[part 1 of 2: package /STLASWCs]
AUTOSAR XML (schema 4-3-0)
package /STLASWCs
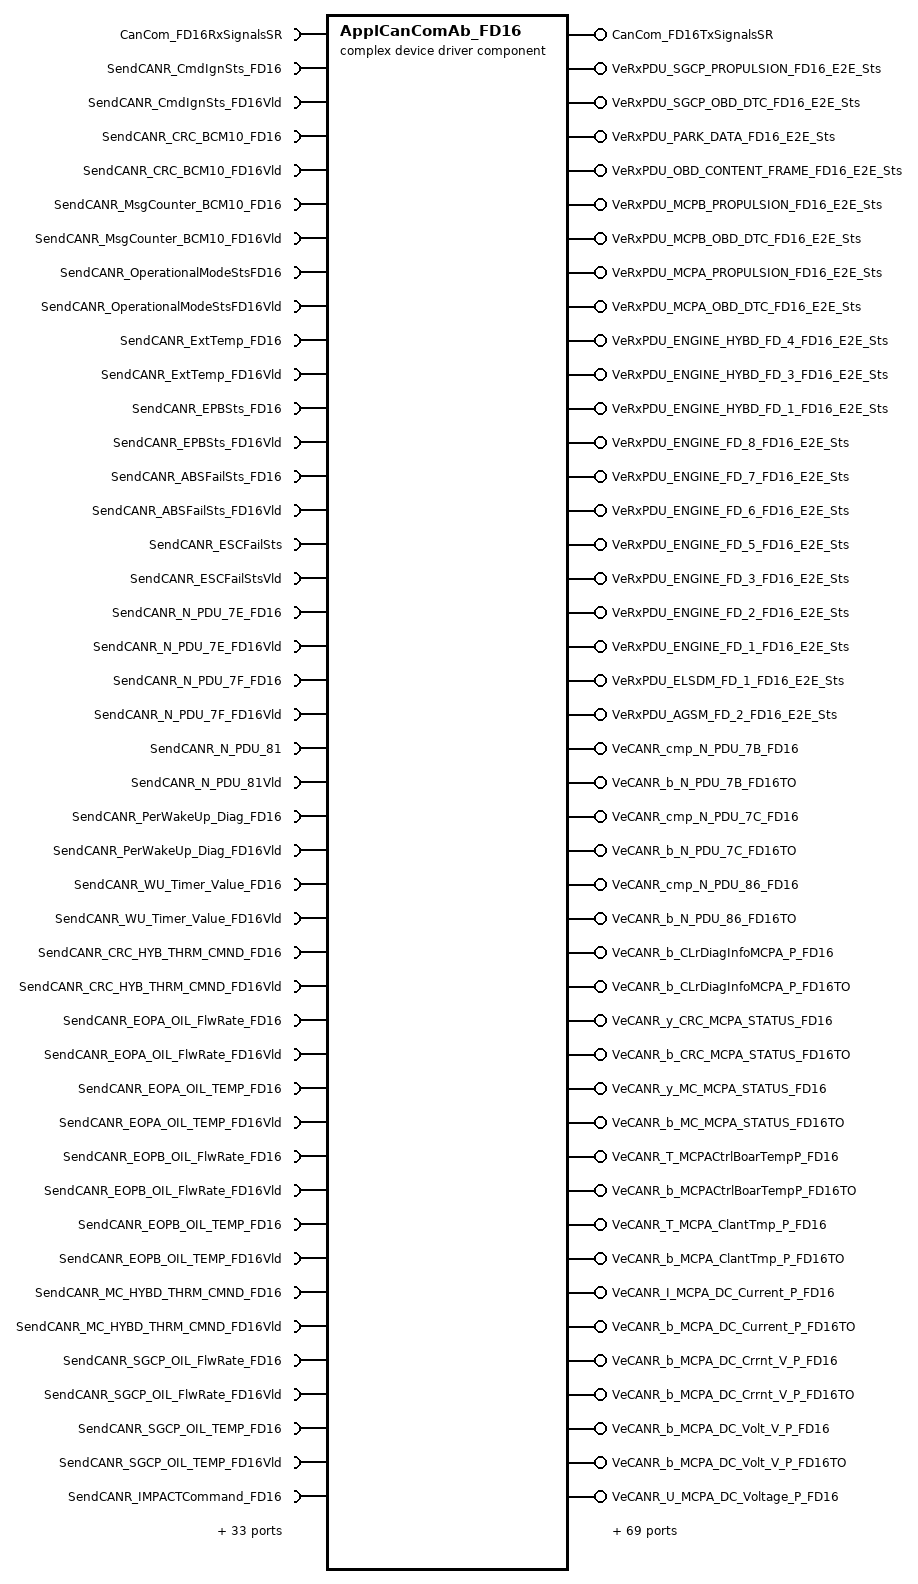
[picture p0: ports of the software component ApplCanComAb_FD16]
  complex device driver sw component type ApplCanComAb_FD16  # Application CAN Communication Abstraction Component - is responsible with receiving and sending CAN data from/to the lower BSW COM layers
    21 x provide port:
      CanCom_FD16TxSignalsSR: provided-interface=CanCom_FD16TxSignalsSR
        provided-com-specs:
          data-element=COMTX_CmdIgnSts_BCM_FD_10_FD16, init-value=constant-reference=COMTX_CmdIgnSts_BCM_FD_10_FD16_Init
          data-element=COMTX_CRC_BCM10_BCM_FD_10_FD16, init-value=constant-reference=COMTX_CRC_BCM10_BCM_FD_10_FD16_Init
          data-element=COMTX_MessageCounter_BCM10_BCM_FD_10_FD16, init-value=constant-reference=COMTX_MessageCounter_BCM10_BCM_FD_10_FD16_Init
          data-element=COMTX_OperationalModeSts_BCM_FD_2_FD16, init-value=constant-reference=COMTX_OperationalModeSts_BCM_FD_2_FD16_Init
          data-element=COMTX_ExternalTemperature_BCM_FD_9_FD16, init-value=constant-reference=COMTX_ExternalTemperature_BCM_FD_9_FD16_Init
          data-element=COMTX_EPBSts_BRAKE_FD_4_FD16, init-value=constant-reference=COMTX_EPBSts_BRAKE_FD_4_FD16_Init
          data-element=COMTX_ABSFailSts_BRAKE_FD_5_FD16, init-value=constant-reference=COMTX_ABSFailSts_BRAKE_FD_5_FD16_Init
          data-element=COMTX_ESCFailSts_BRAKE_FD_5_FD16, init-value=constant-reference=COMTX_ESCFailSts_BRAKE_FD_5_FD16_Init
          data-element=COMTX_N_PDU_7E_GLIWA_MCPA_RX_FD16, init-value=constant-reference=COMTX_N_PDU_7E_GLIWA_MCPA_RX_FD16_Init
          data-element=COMTX_N_PDU_7F_GLIWA_MCPB_RX_FD16, init-value=constant-reference=COMTX_N_PDU_7F_GLIWA_MCPB_RX_FD16_Init
          data-element=COMTX_N_PDU_81_GLIWA_SGCP_RX_FD16, init-value=constant-reference=COMTX_N_PDU_81_GLIWA_SGCP_RX_FD16_Init
          data-element=COMTX_PerWakeUp_Diag_HYBRID_SYSTEM_EPT1_FD16, init-value=constant-reference=COMTX_PerWakeUp_Diag_HYBRID_SYSTEM_EPT1_FD16_Init
          data-element=COMTX_WU_Timer_Value_HYBRID_SYSTEM_EPT1_FD16, init-value=constant-reference=COMTX_WU_Timer_Value_HYBRID_SYSTEM_EPT1_FD16_Init
          data-element=COMTX_CRC_HYBRID_THERMAL_COMMAND_HYBRID_THERMAL_COMMAND_FD16, init-value=constant-reference=COMTX_CRC_HYBRID_THERMAL_COMMAND_HYBRID_THERMAL_COMMAND_FD16_Init
          data-element=COMTX_EOPA_OIL_FlwRate_HYBRID_THERMAL_COMMAND_FD16, init-value=constant-reference=COMTX_EOPA_OIL_FlwRate_HYBRID_THERMAL_COMMAND_FD16_Init
          data-element=COMTX_EOPA_OIL_TEMP_HYBRID_THERMAL_COMMAND_FD16, init-value=constant-reference=COMTX_EOPA_OIL_TEMP_HYBRID_THERMAL_COMMAND_FD16_Init
          data-element=COMTX_EOPB_OIL_FlwRate_HYBRID_THERMAL_COMMAND_FD16, init-value=constant-reference=COMTX_EOPB_OIL_FlwRate_HYBRID_THERMAL_COMMAND_FD16_Init
          data-element=COMTX_EOPB_OIL_TEMP_HYBRID_THERMAL_COMMAND_FD16, init-value=constant-reference=COMTX_EOPB_OIL_TEMP_HYBRID_THERMAL_COMMAND_FD16_Init
          data-element=COMTX_MessageCounter_HYBRID_THERMAL_COMMAND_HYBRID_THERMAL_COMMAND_FD16, init-value=constant-reference=COMTX_MessageCounter_HYBRID_THERMAL_COMMAND_HYBRID_THERMAL_COMMAND_FD16_Init
          data-element=COMTX_SGCP_OIL_FlwRate_HYBRID_THERMAL_COMMAND_FD16, init-value=constant-reference=COMTX_SGCP_OIL_FlwRate_HYBRID_THERMAL_COMMAND_FD16_Init
          data-element=COMTX_SGCP_OIL_TEMP_HYBRID_THERMAL_COMMAND_FD16, init-value=constant-reference=COMTX_SGCP_OIL_TEMP_HYBRID_THERMAL_COMMAND_FD16_Init
          data-element=COMTX_IMPACTCommand_IMPACT_INFO_FD16, init-value=constant-reference=COMTX_IMPACTCommand_IMPACT_INFO_FD16_Init
          data-element=COMTX_IMPACTConfirm_IMPACT_INFO_FD16, init-value=constant-reference=COMTX_IMPACTConfirm_IMPACT_INFO_FD16_Init
          data-element=COMTX_TotalOdometer_IPC_FD_1_FD16, init-value=constant-reference=COMTX_TotalOdometer_IPC_FD_1_FD16_Init
          data-element=COMTX_Real_Time_Clock_REAL_TIME_CLOCK_FD16, init-value=constant-reference=COMTX_Real_Time_Clock_REAL_TIME_CLOCK_FD16_Init
          data-element=COMTX_Real_Time_Validity_REAL_TIME_CLOCK_FD16, init-value=constant-reference=COMTX_Real_Time_Validity_REAL_TIME_CLOCK_FD16_Init
          data-element=COMTX_GPS_Date_Day_TELEMATIC_FD_1_FD16, init-value=constant-reference=COMTX_GPS_Date_Day_TELEMATIC_FD_1_FD16_Init
          data-element=COMTX_GPS_Date_Month_TELEMATIC_FD_1_FD16, init-value=constant-reference=COMTX_GPS_Date_Month_TELEMATIC_FD_1_FD16_Init
          data-element=COMTX_GPS_Date_Year_TELEMATIC_FD_1_FD16, init-value=constant-reference=COMTX_GPS_Date_Year_TELEMATIC_FD_1_FD16_Init
          data-element=COMTX_GPS_UTC_Hour_TELEMATIC_FD_1_FD16, init-value=constant-reference=COMTX_GPS_UTC_Hour_TELEMATIC_FD_1_FD16_Init
          data-element=COMTX_GPS_UTC_Minute_TELEMATIC_FD_1_FD16, init-value=constant-reference=COMTX_GPS_UTC_Minute_TELEMATIC_FD_1_FD16_Init
          data-element=COMTX_GPS_UTC_Second_TELEMATIC_FD_1_FD16, init-value=constant-reference=COMTX_GPS_UTC_Second_TELEMATIC_FD_1_FD16_Init
          data-element=COMTX_T4_Sensor_Temp_VDCM_PWT3_FD16, init-value=constant-reference=COMTX_T4_Sensor_Temp_VDCM_PWT3_FD16_Init
          data-element=COMTX_T7_CoolantTempVldty_VDCM_PWT3_FD16, init-value=constant-reference=COMTX_T7_CoolantTempVldty_VDCM_PWT3_FD16_Init
          data-element=COMTX_T7_Sensor_Temp_VDCM_PWT3_FD16, init-value=constant-reference=COMTX_T7_Sensor_Temp_VDCM_PWT3_FD16_Init
          data-element=COMTX_RELSD_TgtTrq_VEHDYN_FD_1_FD16, init-value=constant-reference=COMTX_RELSD_TgtTrq_VEHDYN_FD_1_FD16_Init
          data-element=COMTX_VIN_DATA_VIN_FD16, init-value=constant-reference=COMTX_VIN_DATA_VIN_FD16_Init
          data-element=COMTX_VIN_MSG_VIN_FD16, init-value=constant-reference=COMTX_VIN_MSG_VIN_FD16_Init
      VeRxPDU_SGCP_PROPULSION_FD16_E2E_Sts: provided-com-specs=[{data-element=E2ECheckSts, init-value=0}, {data-element=OpRetVal, init-value=0}], provided-interface=VeRxPDU_SGCP_PROPULSION_FD16_E2E_Sts
      VeRxPDU_SGCP_OBD_DTC_FD16_E2E_Sts: provided-com-specs=[{data-element=E2ECheckSts, init-value=0}, {data-element=OpRetVal, init-value=0}], provided-interface=VeRxPDU_SGCP_OBD_DTC_FD16_E2E_Sts
      VeRxPDU_PARK_DATA_FD16_E2E_Sts: provided-com-specs=[{data-element=E2ECheckSts, init-value=0}, {data-element=OpRetVal, init-value=0}], provided-interface=VeRxPDU_PARK_DATA_FD16_E2E_Sts
      VeRxPDU_OBD_CONTENT_FRAME_FD16_E2E_Sts: provided-com-specs=[{data-element=E2ECheckSts, init-value=0}, {data-element=OpRetVal, init-value=0}], provided-interface=VeRxPDU_OBD_CONTENT_FRAME_FD16_E2E_Sts
      VeRxPDU_MCPB_PROPULSION_FD16_E2E_Sts: provided-com-specs=[{data-element=E2ECheckSts, init-value=0}, {data-element=OpRetVal, init-value=0}], provided-interface=VeRxPDU_MCPB_PROPULSION_FD16_E2E_Sts
      VeRxPDU_MCPB_OBD_DTC_FD16_E2E_Sts: provided-com-specs=[{data-element=E2ECheckSts, init-value=0}, {data-element=OpRetVal, init-value=0}], provided-interface=VeRxPDU_MCPB_OBD_DTC_FD16_E2E_Sts
      VeRxPDU_MCPA_PROPULSION_FD16_E2E_Sts: provided-com-specs=[{data-element=E2ECheckSts, init-value=0}, {data-element=OpRetVal, init-value=0}], provided-interface=VeRxPDU_MCPA_PROPULSION_FD16_E2E_Sts
      VeRxPDU_MCPA_OBD_DTC_FD16_E2E_Sts: provided-com-specs=[{data-element=E2ECheckSts, init-value=0}, {data-element=OpRetVal, init-value=0}], provided-interface=VeRxPDU_MCPA_OBD_DTC_FD16_E2E_Sts
      VeRxPDU_ENGINE_HYBD_FD_4_FD16_E2E_Sts: provided-com-specs=[{data-element=E2ECheckSts, init-value=0}, {data-element=OpRetVal, init-value=0}], provided-interface=VeRxPDU_ENGINE_HYBD_FD_4_FD16_E2E_Sts
      VeRxPDU_ENGINE_HYBD_FD_3_FD16_E2E_Sts: provided-com-specs=[{data-element=E2ECheckSts, init-value=0}, {data-element=OpRetVal, init-value=0}], provided-interface=VeRxPDU_ENGINE_HYBD_FD_3_FD16_E2E_Sts
      VeRxPDU_ENGINE_HYBD_FD_1_FD16_E2E_Sts: provided-com-specs=[{data-element=E2ECheckSts, init-value=0}, {data-element=OpRetVal, init-value=0}], provided-interface=VeRxPDU_ENGINE_HYBD_FD_1_FD16_E2E_Sts
      VeRxPDU_ENGINE_FD_8_FD16_E2E_Sts: provided-com-specs=[{data-element=E2ECheckSts, init-value=0}, {data-element=OpRetVal, init-value=0}], provided-interface=VeRxPDU_ENGINE_FD_8_FD16_E2E_Sts
      VeRxPDU_ENGINE_FD_7_FD16_E2E_Sts: provided-com-specs=[{data-element=E2ECheckSts, init-value=0}, {data-element=OpRetVal, init-value=0}], provided-interface=VeRxPDU_ENGINE_FD_7_FD16_E2E_Sts
      VeRxPDU_ENGINE_FD_6_FD16_E2E_Sts: provided-com-specs=[{data-element=E2ECheckSts, init-value=0}, {data-element=OpRetVal, init-value=0}], provided-interface=VeRxPDU_ENGINE_FD_6_FD16_E2E_Sts
      VeRxPDU_ENGINE_FD_5_FD16_E2E_Sts: provided-com-specs=[{data-element=E2ECheckSts, init-value=0}, {data-element=OpRetVal, init-value=0}], provided-interface=VeRxPDU_ENGINE_FD_5_FD16_E2E_Sts
      VeRxPDU_ENGINE_FD_3_FD16_E2E_Sts: provided-com-specs=[{data-element=E2ECheckSts, init-value=0}, {data-element=OpRetVal, init-value=0}], provided-interface=VeRxPDU_ENGINE_FD_3_FD16_E2E_Sts
      VeRxPDU_ENGINE_FD_2_FD16_E2E_Sts: provided-com-specs=[{data-element=E2ECheckSts, init-value=0}, {data-element=OpRetVal, init-value=0}], provided-interface=VeRxPDU_ENGINE_FD_2_FD16_E2E_Sts
      VeRxPDU_ENGINE_FD_1_FD16_E2E_Sts: provided-com-specs=[{data-element=E2ECheckSts, init-value=0}, {data-element=OpRetVal, init-value=0}], provided-interface=VeRxPDU_ENGINE_FD_1_FD16_E2E_Sts
      VeRxPDU_ELSDM_FD_1_FD16_E2E_Sts: provided-com-specs=[{data-element=E2ECheckSts, init-value=0}, {data-element=OpRetVal, init-value=0}], provided-interface=VeRxPDU_ELSDM_FD_1_FD16_E2E_Sts
      VeRxPDU_AGSM_FD_2_FD16_E2E_Sts: provided-com-specs=[{data-element=E2ECheckSts, init-value=0}, {data-element=OpRetVal, init-value=0}], provided-interface=VeRxPDU_AGSM_FD_2_FD16_E2E_Sts
    require port CanCom_FD16RxSignalsSR: required-interface=CanCom_FD16RxSignalsSR
      required-com-specs:
        data-element=COMRX_N_PDU_7B_GLIWA_MCPA_TX_FD16, handle-never-received=true, init-value=constant-reference=COMRX_N_PDU_7B_GLIWA_MCPA_TX_FD16_Init
        data-element=COMRX_N_PDU_7C_GLIWA_MCPB_TX_FD16, handle-never-received=true, init-value=constant-reference=COMRX_N_PDU_7C_GLIWA_MCPB_TX_FD16_Init
        data-element=COMRX_N_PDU_86_GLIWA_SGCP_TX_FD16, handle-never-received=true, init-value=constant-reference=COMRX_N_PDU_86_GLIWA_SGCP_TX_FD16_Init
        data-element=COMRX_CLrDiagInfo_MCPA_P_MCPA_STATUS_FD16, alive-timeout=0.2, handle-never-received=true, init-value=constant-reference=COMRX_CLrDiagInfo_MCPA_P_MCPA_STATUS_FD16_Init
        data-element=COMRX_CRC_MCPA_STATUS_MCPA_STATUS_FD16, alive-timeout=0.2, handle-never-received=true, init-value=constant-reference=COMRX_CRC_MCPA_STATUS_MCPA_STATUS_FD16_Init
        data-element=COMRX_MC_MCPA_STATUS_MCPA_STATUS_FD16, alive-timeout=0.2, handle-never-received=true, init-value=constant-reference=COMRX_MC_MCPA_STATUS_MCPA_STATUS_FD16_Init
        data-element=COMRX_MCPA_Control_Board_Temperature_P_MCPA_STATUS_FD16, alive-timeout=0.2, handle-never-received=true, init-value=constant-reference=COMRX_MCPA_Control_Board_Temperature_P_MCPA_STATUS_FD16_Init
        data-element=COMRX_MCPA_CoolantTemp_P_MCPA_STATUS_FD16, alive-timeout=0.2, handle-never-received=true, init-value=constant-reference=COMRX_MCPA_CoolantTemp_P_MCPA_STATUS_FD16_Init
        data-element=COMRX_MCPA_DC_Current_P_MCPA_STATUS_FD16, alive-timeout=0.2, handle-never-received=true, init-value=constant-reference=COMRX_MCPA_DC_Current_P_MCPA_STATUS_FD16_Init
        data-element=COMRX_MCPA_DC_Current_V_P_MCPA_STATUS_FD16, alive-timeout=0.2, handle-never-received=true, init-value=constant-reference=COMRX_MCPA_DC_Current_V_P_MCPA_STATUS_FD16_Init
        data-element=COMRX_MCPA_DC_Volt_V_P_MCPA_STATUS_FD16, alive-timeout=0.2, handle-never-received=true, init-value=constant-reference=COMRX_MCPA_DC_Volt_V_P_MCPA_STATUS_FD16_Init
        data-element=COMRX_MCPA_DC_Voltage_P_MCPA_STATUS_FD16, alive-timeout=0.2, handle-never-received=true, init-value=constant-reference=COMRX_MCPA_DC_Voltage_P_MCPA_STATUS_FD16_Init
        data-element=COMRX_MCPA_DerateReason_P_MCPA_STATUS_FD16, alive-timeout=0.2, handle-never-received=true, init-value=constant-reference=COMRX_MCPA_DerateReason_P_MCPA_STATUS_FD16_Init
        data-element=COMRX_MCPA_Inverter_Temp_P_MCPA_STATUS_FD16, alive-timeout=0.2, handle-never-received=true, init-value=constant-reference=COMRX_MCPA_Inverter_Temp_P_MCPA_STATUS_FD16_Init
        data-element=COMRX_MCPA_PIM_DC_Side_Busbar_Temp_P_MCPA_STATUS_FD16, alive-timeout=0.2, handle-never-received=true, init-value=constant-reference=COMRX_MCPA_PIM_DC_Side_Busbar_Temp_P_MCPA_STATUS_FD16_Init
        data-element=COMRX_MCPA_Rotor_Temperature_P_MCPA_STATUS_FD16, alive-timeout=0.2, handle-never-received=true, init-value=constant-reference=COMRX_MCPA_Rotor_Temperature_P_MCPA_STATUS_FD16_Init
        data-element=COMRX_MCPA_Service_Lamp_Request_P_MCPA_STATUS_FD16, alive-timeout=0.2, handle-never-received=true, init-value=constant-reference=COMRX_MCPA_Service_Lamp_Request_P_MCPA_STATUS_FD16_Init
        data-element=COMRX_CLrDiagInfo_MCPB_P_MCPB_STATUS_FD16, alive-timeout=0.2, handle-never-received=true, init-value=constant-reference=COMRX_CLrDiagInfo_MCPB_P_MCPB_STATUS_FD16_Init
        data-element=COMRX_CRC_MCPB_STATUS_MCPB_STATUS_FD16, alive-timeout=0.2, handle-never-received=true, init-value=constant-reference=COMRX_CRC_MCPB_STATUS_MCPB_STATUS_FD16_Init
        data-element=COMRX_MC_MCPB_STATUS_MCPB_STATUS_FD16, alive-timeout=0.2, handle-never-received=true, init-value=constant-reference=COMRX_MC_MCPB_STATUS_MCPB_STATUS_FD16_Init
        data-element=COMRX_MCPB_Control_Board_Temperature_P_MCPB_STATUS_FD16, alive-timeout=0.2, handle-never-received=true, init-value=constant-reference=COMRX_MCPB_Control_Board_Temperature_P_MCPB_STATUS_FD16_Init
        data-element=COMRX_MCPB_CoolantTemp_P_MCPB_STATUS_FD16, alive-timeout=0.2, handle-never-received=true, init-value=constant-reference=COMRX_MCPB_CoolantTemp_P_MCPB_STATUS_FD16_Init
        data-element=COMRX_MCPB_DC_Current_P_MCPB_STATUS_FD16, alive-timeout=0.2, handle-never-received=true, init-value=constant-reference=COMRX_MCPB_DC_Current_P_MCPB_STATUS_FD16_Init
        data-element=COMRX_MCPB_DC_Current_V_P_MCPB_STATUS_FD16, alive-timeout=0.2, handle-never-received=true, init-value=constant-reference=COMRX_MCPB_DC_Current_V_P_MCPB_STATUS_FD16_Init
        data-element=COMRX_MCPB_DC_Volt_V_P_MCPB_STATUS_FD16, alive-timeout=0.2, handle-never-received=true, init-value=constant-reference=COMRX_MCPB_DC_Volt_V_P_MCPB_STATUS_FD16_Init
        data-element=COMRX_MCPB_DC_Voltage_P_MCPB_STATUS_FD16, alive-timeout=0.2, handle-never-received=true, init-value=constant-reference=COMRX_MCPB_DC_Voltage_P_MCPB_STATUS_FD16_Init
        data-element=COMRX_MCPB_DerateReason_P_MCPB_STATUS_FD16, alive-timeout=0.2, handle-never-received=true, init-value=constant-reference=COMRX_MCPB_DerateReason_P_MCPB_STATUS_FD16_Init
        data-element=COMRX_MCPB_Inverter_Temp_P_MCPB_STATUS_FD16, alive-timeout=0.2, handle-never-received=true, init-value=constant-reference=COMRX_MCPB_Inverter_Temp_P_MCPB_STATUS_FD16_Init
        data-element=COMRX_MCPB_PIM_DC_Side_Busbar_Temp_P_MCPB_STATUS_FD16, alive-timeout=0.2, handle-never-received=true, init-value=constant-reference=COMRX_MCPB_PIM_DC_Side_Busbar_Temp_P_MCPB_STATUS_FD16_Init
        data-element=COMRX_MCPB_Rotor_Temperature_P_MCPB_STATUS_FD16, alive-timeout=0.2, handle-never-received=true, init-value=constant-reference=COMRX_MCPB_Rotor_Temperature_P_MCPB_STATUS_FD16_Init
        data-element=COMRX_MCPB_Service_Lamp_Request_P_MCPB_STATUS_FD16, alive-timeout=0.2, handle-never-received=true, init-value=constant-reference=COMRX_MCPB_Service_Lamp_Request_P_MCPB_STATUS_FD16_Init
        data-element=COMRX_CLrDiagInfo_SGCP_P_SGCP_STATUS_FD16, alive-timeout=0.2, handle-never-received=true, init-value=constant-reference=COMRX_CLrDiagInfo_SGCP_P_SGCP_STATUS_FD16_Init
        data-element=COMRX_CRC_SGCP_STATUS_SGCP_STATUS_FD16, alive-timeout=0.2, handle-never-received=true, init-value=constant-reference=COMRX_CRC_SGCP_STATUS_SGCP_STATUS_FD16_Init
        data-element=COMRX_MC_SGCP_STATUS_SGCP_STATUS_FD16, alive-timeout=0.2, handle-never-received=true, init-value=constant-reference=COMRX_MC_SGCP_STATUS_SGCP_STATUS_FD16_Init
        data-element=COMRX_SGCP_Control_Board_Temperature_P_SGCP_STATUS_FD16, alive-timeout=0.2, handle-never-received=true, init-value=constant-reference=COMRX_SGCP_Control_Board_Temperature_P_SGCP_STATUS_FD16_Init
        data-element=COMRX_SGCP_CoolantTemp_P_SGCP_STATUS_FD16, alive-timeout=0.2, handle-never-received=true, init-value=constant-reference=COMRX_SGCP_CoolantTemp_P_SGCP_STATUS_FD16_Init
        data-element=COMRX_SGCP_DC_Current_P_SGCP_STATUS_FD16, alive-timeout=0.2, handle-never-received=true, init-value=constant-reference=COMRX_SGCP_DC_Current_P_SGCP_STATUS_FD16_Init
        data-element=COMRX_SGCP_DC_Current_V_P_SGCP_STATUS_FD16, alive-timeout=0.2, handle-never-received=true, init-value=constant-reference=COMRX_SGCP_DC_Current_V_P_SGCP_STATUS_FD16_Init
        data-element=COMRX_SGCP_DC_Volt_V_P_SGCP_STATUS_FD16, alive-timeout=0.2, handle-never-received=true, init-value=constant-reference=COMRX_SGCP_DC_Volt_V_P_SGCP_STATUS_FD16_Init
        data-element=COMRX_SGCP_DC_Voltage_P_SGCP_STATUS_FD16, alive-timeout=0.2, handle-never-received=true, init-value=constant-reference=COMRX_SGCP_DC_Voltage_P_SGCP_STATUS_FD16_Init
        data-element=COMRX_SGCP_DerateReason_P_SGCP_STATUS_FD16, alive-timeout=0.2, handle-never-received=true, init-value=constant-reference=COMRX_SGCP_DerateReason_P_SGCP_STATUS_FD16_Init
        data-element=COMRX_SGCP_Inverter_Temp_P_SGCP_STATUS_FD16, alive-timeout=0.2, handle-never-received=true, init-value=constant-reference=COMRX_SGCP_Inverter_Temp_P_SGCP_STATUS_FD16_Init
        data-element=COMRX_SGCP_PIM_AC_Side_Busbar_Temp_P_SGCP_STATUS_FD16, alive-timeout=0.2, handle-never-received=true, init-value=constant-reference=COMRX_SGCP_PIM_AC_Side_Busbar_Temp_P_SGCP_STATUS_FD16_Init
        data-element=COMRX_SGCP_PIM_DC_Side_Busbar_Temp_P_SGCP_STATUS_FD16, alive-timeout=0.2, handle-never-received=true, init-value=constant-reference=COMRX_SGCP_PIM_DC_Side_Busbar_Temp_P_SGCP_STATUS_FD16_Init
        data-element=COMRX_SGCP_Rotor_Temperature_P_SGCP_STATUS_FD16, alive-timeout=0.2, handle-never-received=true, init-value=constant-reference=COMRX_SGCP_Rotor_Temperature_P_SGCP_STATUS_FD16_Init
        data-element=COMRX_SGCP_Service_Lamp_Request_P_SGCP_STATUS_FD16, alive-timeout=0.2, handle-never-received=true, init-value=constant-reference=COMRX_SGCP_Service_Lamp_Request_P_SGCP_STATUS_FD16_Init
    92 x provide port:
      VeCANR_cmp_N_PDU_7B_FD16: nonqueued-sender-com-spec{data-element=VeCANR_cmp_N_PDU_7B_FD16, init-value=VeCANR_cmp_N_PDU_7B_FD16Value:0}, provided-interface=VeCANR_cmp_N_PDU_7B_FD16
      VeCANR_b_N_PDU_7B_FD16TO: nonqueued-sender-com-spec{data-element=VeCANR_b_N_PDU_7B_FD16TO, init-value=VeCANR_b_N_PDU_7B_FD16TOValue:0}, provided-interface=VeCANR_b_N_PDU_7B_FD16TO
      VeCANR_cmp_N_PDU_7C_FD16: nonqueued-sender-com-spec{data-element=VeCANR_cmp_N_PDU_7C_FD16, init-value=VeCANR_cmp_N_PDU_7C_FD16Value:0}, provided-interface=VeCANR_cmp_N_PDU_7C_FD16
      VeCANR_b_N_PDU_7C_FD16TO: nonqueued-sender-com-spec{data-element=VeCANR_b_N_PDU_7C_FD16TO, init-value=VeCANR_b_N_PDU_7C_FD16TOValue:0}, provided-interface=VeCANR_b_N_PDU_7C_FD16TO
      VeCANR_cmp_N_PDU_86_FD16: nonqueued-sender-com-spec{data-element=VeCANR_cmp_N_PDU_86_FD16, init-value=VeCANR_cmp_N_PDU_86_FD16Value:0}, provided-interface=VeCANR_cmp_N_PDU_86_FD16
      VeCANR_b_N_PDU_86_FD16TO: nonqueued-sender-com-spec{data-element=VeCANR_b_N_PDU_86_FD16TO, init-value=VeCANR_b_N_PDU_86_FD16TOValue:0}, provided-interface=VeCANR_b_N_PDU_86_FD16TO
      VeCANR_b_CLrDiagInfoMCPA_P_FD16: nonqueued-sender-com-spec{data-element=VeCANR_b_CLrDiagInfoMCPA_P_FD16, init-value=VeCANR_b_CLrDiagInfoMCPA_P_FD16Value:0}, provided-interface=VeCANR_b_CLrDiagInfoMCPA_P_FD16
      VeCANR_b_CLrDiagInfoMCPA_P_FD16TO: nonqueued-sender-com-spec{data-element=VeCANR_b_CLrDiagInfoMCPA_P_FD16TO, init-value=VeCANR_b_CLrDiagInfoMCPA_P_FD16TOValue:0}, provided-interface=VeCANR_b_CLrDiagInfoMCPA_P_FD16TO
      VeCANR_y_CRC_MCPA_STATUS_FD16: nonqueued-sender-com-spec{data-element=VeCANR_y_CRC_MCPA_STATUS_FD16, init-value=VeCANR_y_CRC_MCPA_STATUS_FD16Value:0}, provided-interface=VeCANR_y_CRC_MCPA_STATUS_FD16
      VeCANR_b_CRC_MCPA_STATUS_FD16TO: nonqueued-sender-com-spec{data-element=VeCANR_b_CRC_MCPA_STATUS_FD16TO, init-value=VeCANR_b_CRC_MCPA_STATUS_FD16TOValue:0}, provided-interface=VeCANR_b_CRC_MCPA_STATUS_FD16TO
      VeCANR_y_MC_MCPA_STATUS_FD16: nonqueued-sender-com-spec{data-element=VeCANR_y_MC_MCPA_STATUS_FD16, init-value=VeCANR_y_MC_MCPA_STATUS_FD16Value:0}, provided-interface=VeCANR_y_MC_MCPA_STATUS_FD16
      VeCANR_b_MC_MCPA_STATUS_FD16TO: nonqueued-sender-com-spec{data-element=VeCANR_b_MC_MCPA_STATUS_FD16TO, init-value=VeCANR_b_MC_MCPA_STATUS_FD16TOValue:0}, provided-interface=VeCANR_b_MC_MCPA_STATUS_FD16TO
      VeCANR_T_MCPACtrlBoarTempP_FD16: nonqueued-sender-com-spec{data-element=VeCANR_T_MCPACtrlBoarTempP_FD16, init-value=VeCANR_T_MCPACtrlBoarTempP_FD16Value:215}, provided-interface=VeCANR_T_MCPACtrlBoarTempP_FD16
      VeCANR_b_MCPACtrlBoarTempP_FD16TO: nonqueued-sender-com-spec{data-element=VeCANR_b_MCPACtrlBoarTempP_FD16TO, init-value=VeCANR_b_MCPACtrlBoarTempP_FD16TOValue:0}, provided-interface=VeCANR_b_MCPACtrlBoarTempP_FD16TO
      VeCANR_T_MCPA_ClantTmp_P_FD16: nonqueued-sender-com-spec{data-element=VeCANR_T_MCPA_ClantTmp_P_FD16, init-value=VeCANR_T_MCPA_ClantTmp_P_FD16Value:-40}, provided-interface=VeCANR_T_MCPA_ClantTmp_P_FD16
      VeCANR_b_MCPA_ClantTmp_P_FD16TO: nonqueued-sender-com-spec{data-element=VeCANR_b_MCPA_ClantTmp_P_FD16TO, init-value=VeCANR_b_MCPA_ClantTmp_P_FD16TOValue:0}, provided-interface=VeCANR_b_MCPA_ClantTmp_P_FD16TO
      VeCANR_I_MCPA_DC_Current_P_FD16: nonqueued-sender-com-spec{data-element=VeCANR_I_MCPA_DC_Current_P_FD16, init-value=VeCANR_I_MCPA_DC_Current_P_FD16Value:0}, provided-interface=VeCANR_I_MCPA_DC_Current_P_FD16
      VeCANR_b_MCPA_DC_Current_P_FD16TO: nonqueued-sender-com-spec{data-element=VeCANR_b_MCPA_DC_Current_P_FD16TO, init-value=VeCANR_b_MCPA_DC_Current_P_FD16TOValue:0}, provided-interface=VeCANR_b_MCPA_DC_Current_P_FD16TO
      VeCANR_b_MCPA_DC_Crrnt_V_P_FD16: nonqueued-sender-com-spec{data-element=VeCANR_b_MCPA_DC_Crrnt_V_P_FD16, init-value=VeCANR_b_MCPA_DC_Crrnt_V_P_FD16Value:0}, provided-interface=VeCANR_b_MCPA_DC_Crrnt_V_P_FD16
      VeCANR_b_MCPA_DC_Crrnt_V_P_FD16TO: nonqueued-sender-com-spec{data-element=VeCANR_b_MCPA_DC_Crrnt_V_P_FD16TO, init-value=VeCANR_b_MCPA_DC_Crrnt_V_P_FD16TOValue:0}, provided-interface=VeCANR_b_MCPA_DC_Crrnt_V_P_FD16TO
      VeCANR_b_MCPA_DC_Volt_V_P_FD16: nonqueued-sender-com-spec{data-element=VeCANR_b_MCPA_DC_Volt_V_P_FD16, init-value=VeCANR_b_MCPA_DC_Volt_V_P_FD16Value:0}, provided-interface=VeCANR_b_MCPA_DC_Volt_V_P_FD16
      VeCANR_b_MCPA_DC_Volt_V_P_FD16TO: nonqueued-sender-com-spec{data-element=VeCANR_b_MCPA_DC_Volt_V_P_FD16TO, init-value=VeCANR_b_MCPA_DC_Volt_V_P_FD16TOValue:0}, provided-interface=VeCANR_b_MCPA_DC_Volt_V_P_FD16TO
      VeCANR_U_MCPA_DC_Voltage_P_FD16: nonqueued-sender-com-spec{data-element=VeCANR_U_MCPA_DC_Voltage_P_FD16, init-value=VeCANR_U_MCPA_DC_Voltage_P_FD16Value:0}, provided-interface=VeCANR_U_MCPA_DC_Voltage_P_FD16
      VeCANR_b_MCPA_DC_Voltage_P_FD16TO: nonqueued-sender-com-spec{data-element=VeCANR_b_MCPA_DC_Voltage_P_FD16TO, init-value=VeCANR_b_MCPA_DC_Voltage_P_FD16TOValue:0}, provided-interface=VeCANR_b_MCPA_DC_Voltage_P_FD16TO
      VeCANR_e_MCPA_DerateResn_P_FD16: nonqueued-sender-com-spec{data-element=VeCANR_e_MCPA_DerateResn_P_FD16, init-value=VeCANR_e_MCPA_DerateResn_P_FD16Value:0}, provided-interface=VeCANR_e_MCPA_DerateResn_P_FD16
      VeCANR_b_MCPA_DerateResn_P_FD16TO: nonqueued-sender-com-spec{data-element=VeCANR_b_MCPA_DerateResn_P_FD16TO, init-value=VeCANR_b_MCPA_DerateResn_P_FD16TOValue:0}, provided-interface=VeCANR_b_MCPA_DerateResn_P_FD16TO
      VeCANR_T_MCPA_InvertTemp_P_FD16: nonqueued-sender-com-spec{data-element=VeCANR_T_MCPA_InvertTemp_P_FD16, init-value=VeCANR_T_MCPA_InvertTemp_P_FD16Value:0}, provided-interface=VeCANR_T_MCPA_InvertTemp_P_FD16
      VeCANR_b_MCPA_InvertTemp_P_FD16TO: nonqueued-sender-com-spec{data-element=VeCANR_b_MCPA_InvertTemp_P_FD16TO, init-value=VeCANR_b_MCPA_InvertTemp_P_FD16TOValue:0}, provided-interface=VeCANR_b_MCPA_InvertTemp_P_FD16TO
      VeCANR_T_MCPAPIMDCSdBusTmpPFD16: nonqueued-sender-com-spec{data-element=VeCANR_T_MCPAPIMDCSdBusTmpPFD16, init-value=VeCANR_T_MCPAPIMDCSdBusTmpPFD16Value:-40}, provided-interface=VeCANR_T_MCPAPIMDCSdBusTmpPFD16
      VeCANR_b_MCPAPIMDCSdBusTmpPFD16TO: nonqueued-sender-com-spec{data-element=VeCANR_b_MCPAPIMDCSdBusTmpPFD16TO, init-value=VeCANR_b_MCPAPIMDCSdBusTmpPFD16TOValue:0}, provided-interface=VeCANR_b_MCPAPIMDCSdBusTmpPFD16TO
      VeCANR_T_MCPARotorTemp_P_FD16: nonqueued-sender-com-spec{data-element=VeCANR_T_MCPARotorTemp_P_FD16, init-value=VeCANR_T_MCPARotorTemp_P_FD16Value:215}, provided-interface=VeCANR_T_MCPARotorTemp_P_FD16
      VeCANR_b_MCPARotorTemp_P_FD16TO: nonqueued-sender-com-spec{data-element=VeCANR_b_MCPARotorTemp_P_FD16TO, init-value=VeCANR_b_MCPARotorTemp_P_FD16TOValue:0}, provided-interface=VeCANR_b_MCPARotorTemp_P_FD16TO
      VeCANR_b_MCPAServLampReq_P_FD16: nonqueued-sender-com-spec{data-element=VeCANR_b_MCPAServLampReq_P_FD16, init-value=VeCANR_b_MCPAServLampReq_P_FD16Value:0}, provided-interface=VeCANR_b_MCPAServLampReq_P_FD16
      VeCANR_b_MCPAServLampReq_P_FD16TO: nonqueued-sender-com-spec{data-element=VeCANR_b_MCPAServLampReq_P_FD16TO, init-value=VeCANR_b_MCPAServLampReq_P_FD16TOValue:0}, provided-interface=VeCANR_b_MCPAServLampReq_P_FD16TO
      VeCANR_b_CLrDiagInfoMCPB_P_FD16: nonqueued-sender-com-spec{data-element=VeCANR_b_CLrDiagInfoMCPB_P_FD16, init-value=VeCANR_b_CLrDiagInfoMCPB_P_FD16Value:0}, provided-interface=VeCANR_b_CLrDiagInfoMCPB_P_FD16
      VeCANR_b_CLrDiagInfoMCPB_P_FD16TO: nonqueued-sender-com-spec{data-element=VeCANR_b_CLrDiagInfoMCPB_P_FD16TO, init-value=VeCANR_b_CLrDiagInfoMCPB_P_FD16TOValue:0}, provided-interface=VeCANR_b_CLrDiagInfoMCPB_P_FD16TO
      VeCANR_y_CRC_MCPB_STATUS_FD16: nonqueued-sender-com-spec{data-element=VeCANR_y_CRC_MCPB_STATUS_FD16, init-value=VeCANR_y_CRC_MCPB_STATUS_FD16Value:0}, provided-interface=VeCANR_y_CRC_MCPB_STATUS_FD16
      VeCANR_b_CRC_MCPB_STATUS_FD16TO: nonqueued-sender-com-spec{data-element=VeCANR_b_CRC_MCPB_STATUS_FD16TO, init-value=VeCANR_b_CRC_MCPB_STATUS_FD16TOValue:0}, provided-interface=VeCANR_b_CRC_MCPB_STATUS_FD16TO
      VeCANR_y_MC_MCPB_STATUS_FD16: nonqueued-sender-com-spec{data-element=VeCANR_y_MC_MCPB_STATUS_FD16, init-value=VeCANR_y_MC_MCPB_STATUS_FD16Value:0}, provided-interface=VeCANR_y_MC_MCPB_STATUS_FD16
      VeCANR_b_MC_MCPB_STATUS_FD16TO: nonqueued-sender-com-spec{data-element=VeCANR_b_MC_MCPB_STATUS_FD16TO, init-value=VeCANR_b_MC_MCPB_STATUS_FD16TOValue:0}, provided-interface=VeCANR_b_MC_MCPB_STATUS_FD16TO
      VeCANR_y_MCPBCtrlBoarTempP_FD16: nonqueued-sender-com-spec{data-element=VeCANR_y_MCPBCtrlBoarTempP_FD16, init-value=VeCANR_y_MCPBCtrlBoarTempP_FD16Value:-40}, provided-interface=VeCANR_y_MCPBCtrlBoarTempP_FD16
      VeCANR_b_MCPBCtrlBoarTempP_FD16TO: nonqueued-sender-com-spec{data-element=VeCANR_b_MCPBCtrlBoarTempP_FD16TO, init-value=VeCANR_b_MCPBCtrlBoarTempP_FD16TOValue:0}, provided-interface=VeCANR_b_MCPBCtrlBoarTempP_FD16TO
      VeCANR_T_MCPB_CoolantTmp_P_FD16: nonqueued-sender-com-spec{data-element=VeCANR_T_MCPB_CoolantTmp_P_FD16, init-value=VeCANR_T_MCPB_CoolantTmp_P_FD16Value:-40}, provided-interface=VeCANR_T_MCPB_CoolantTmp_P_FD16
      VeCANR_b_MCPB_CoolantTmp_P_FD16TO: nonqueued-sender-com-spec{data-element=VeCANR_b_MCPB_CoolantTmp_P_FD16TO, init-value=VeCANR_b_MCPB_CoolantTmp_P_FD16TOValue:0}, provided-interface=VeCANR_b_MCPB_CoolantTmp_P_FD16TO
      VeCANR_I_MCPB_DC_Current_P_FD16: nonqueued-sender-com-spec{data-element=VeCANR_I_MCPB_DC_Current_P_FD16, init-value=VeCANR_I_MCPB_DC_Current_P_FD16Value:0}, provided-interface=VeCANR_I_MCPB_DC_Current_P_FD16
      VeCANR_b_MCPB_DC_Current_P_FD16TO: nonqueued-sender-com-spec{data-element=VeCANR_b_MCPB_DC_Current_P_FD16TO, init-value=VeCANR_b_MCPB_DC_Current_P_FD16TOValue:0}, provided-interface=VeCANR_b_MCPB_DC_Current_P_FD16TO
      VeCANR_b_MCPB_DC_Crrnt_V_P_FD16: nonqueued-sender-com-spec{data-element=VeCANR_b_MCPB_DC_Crrnt_V_P_FD16, init-value=VeCANR_b_MCPB_DC_Crrnt_V_P_FD16Value:0}, provided-interface=VeCANR_b_MCPB_DC_Crrnt_V_P_FD16
      VeCANR_b_MCPB_DC_Crrnt_V_P_FD16TO: nonqueued-sender-com-spec{data-element=VeCANR_b_MCPB_DC_Crrnt_V_P_FD16TO, init-value=VeCANR_b_MCPB_DC_Crrnt_V_P_FD16TOValue:0}, provided-interface=VeCANR_b_MCPB_DC_Crrnt_V_P_FD16TO
      VeCANR_b_MCPB_DC_Volt_V_P_FD16: nonqueued-sender-com-spec{data-element=VeCANR_b_MCPB_DC_Volt_V_P_FD16, init-value=VeCANR_b_MCPB_DC_Volt_V_P_FD16Value:0}, provided-interface=VeCANR_b_MCPB_DC_Volt_V_P_FD16
      VeCANR_b_MCPB_DC_Volt_V_P_FD16TO: nonqueued-sender-com-spec{data-element=VeCANR_b_MCPB_DC_Volt_V_P_FD16TO, init-value=VeCANR_b_MCPB_DC_Volt_V_P_FD16TOValue:0}, provided-interface=VeCANR_b_MCPB_DC_Volt_V_P_FD16TO
      VeCANR_U_MCPB_DC_Voltage_P_FD16: nonqueued-sender-com-spec{data-element=VeCANR_U_MCPB_DC_Voltage_P_FD16, init-value=VeCANR_U_MCPB_DC_Voltage_P_FD16Value:0}, provided-interface=VeCANR_U_MCPB_DC_Voltage_P_FD16
      VeCANR_b_MCPB_DC_Voltage_P_FD16TO: nonqueued-sender-com-spec{data-element=VeCANR_b_MCPB_DC_Voltage_P_FD16TO, init-value=VeCANR_b_MCPB_DC_Voltage_P_FD16TOValue:0}, provided-interface=VeCANR_b_MCPB_DC_Voltage_P_FD16TO
      VeCANR_e_MCPB_DerateResn_P_FD16: nonqueued-sender-com-spec{data-element=VeCANR_e_MCPB_DerateResn_P_FD16, init-value=VeCANR_e_MCPB_DerateResn_P_FD16Value:0}, provided-interface=VeCANR_e_MCPB_DerateResn_P_FD16
      VeCANR_b_MCPB_DerateResn_P_FD16TO: nonqueued-sender-com-spec{data-element=VeCANR_b_MCPB_DerateResn_P_FD16TO, init-value=VeCANR_b_MCPB_DerateResn_P_FD16TOValue:0}, provided-interface=VeCANR_b_MCPB_DerateResn_P_FD16TO
      VeCANR_T_MCPB_InvertTemp_P_FD16: nonqueued-sender-com-spec{data-element=VeCANR_T_MCPB_InvertTemp_P_FD16, init-value=VeCANR_T_MCPB_InvertTemp_P_FD16Value:0}, provided-interface=VeCANR_T_MCPB_InvertTemp_P_FD16
      VeCANR_b_MCPB_InvertTemp_P_FD16TO: nonqueued-sender-com-spec{data-element=VeCANR_b_MCPB_InvertTemp_P_FD16TO, init-value=VeCANR_b_MCPB_InvertTemp_P_FD16TOValue:0}, provided-interface=VeCANR_b_MCPB_InvertTemp_P_FD16TO
      VeCANR_T_MCPBPIMDCSdBusTmpPFD16: nonqueued-sender-com-spec{data-element=VeCANR_T_MCPBPIMDCSdBusTmpPFD16, init-value=VeCANR_T_MCPBPIMDCSdBusTmpPFD16Value:-40}, provided-interface=VeCANR_T_MCPBPIMDCSdBusTmpPFD16
      VeCANR_b_MCPBPIMDCSdBusTmpPFD16TO: nonqueued-sender-com-spec{data-element=VeCANR_b_MCPBPIMDCSdBusTmpPFD16TO, init-value=VeCANR_b_MCPBPIMDCSdBusTmpPFD16TOValue:0}, provided-interface=VeCANR_b_MCPBPIMDCSdBusTmpPFD16TO
      VeCANR_T_MCPBRotorTemp_P_FD16: nonqueued-sender-com-spec{data-element=VeCANR_T_MCPBRotorTemp_P_FD16, init-value=VeCANR_T_MCPBRotorTemp_P_FD16Value:215}, provided-interface=VeCANR_T_MCPBRotorTemp_P_FD16
      VeCANR_b_MCPBRotorTemp_P_FD16TO: nonqueued-sender-com-spec{data-element=VeCANR_b_MCPBRotorTemp_P_FD16TO, init-value=VeCANR_b_MCPBRotorTemp_P_FD16TOValue:0}, provided-interface=VeCANR_b_MCPBRotorTemp_P_FD16TO
      VeCANR_b_MCPBServLampReq_P_FD16: nonqueued-sender-com-spec{data-element=VeCANR_b_MCPBServLampReq_P_FD16, init-value=VeCANR_b_MCPBServLampReq_P_FD16Value:0}, provided-interface=VeCANR_b_MCPBServLampReq_P_FD16
      VeCANR_b_MCPBServLampReq_P_FD16TO: nonqueued-sender-com-spec{data-element=VeCANR_b_MCPBServLampReq_P_FD16TO, init-value=VeCANR_b_MCPBServLampReq_P_FD16TOValue:0}, provided-interface=VeCANR_b_MCPBServLampReq_P_FD16TO
      VeCANR_b_CLrDiagInfoSGCP_P_FD16: nonqueued-sender-com-spec{data-element=VeCANR_b_CLrDiagInfoSGCP_P_FD16, init-value=VeCANR_b_CLrDiagInfoSGCP_P_FD16Value:0}, provided-interface=VeCANR_b_CLrDiagInfoSGCP_P_FD16
      VeCANR_b_CLrDiagInfoSGCP_P_FD16TO: nonqueued-sender-com-spec{data-element=VeCANR_b_CLrDiagInfoSGCP_P_FD16TO, init-value=VeCANR_b_CLrDiagInfoSGCP_P_FD16TOValue:0}, provided-interface=VeCANR_b_CLrDiagInfoSGCP_P_FD16TO
      VeCANR_y_CRC_SGCP_STATUS_FD16: nonqueued-sender-com-spec{data-element=VeCANR_y_CRC_SGCP_STATUS_FD16, init-value=VeCANR_y_CRC_SGCP_STATUS_FD16Value:0}, provided-interface=VeCANR_y_CRC_SGCP_STATUS_FD16
      VeCANR_b_CRC_SGCP_STATUS_FD16TO: nonqueued-sender-com-spec{data-element=VeCANR_b_CRC_SGCP_STATUS_FD16TO, init-value=VeCANR_b_CRC_SGCP_STATUS_FD16TOValue:0}, provided-interface=VeCANR_b_CRC_SGCP_STATUS_FD16TO
      VeCANR_y_MC_SGCP_STATUS_FD16: nonqueued-sender-com-spec{data-element=VeCANR_y_MC_SGCP_STATUS_FD16, init-value=VeCANR_y_MC_SGCP_STATUS_FD16Value:0}, provided-interface=VeCANR_y_MC_SGCP_STATUS_FD16
      VeCANR_b_MC_SGCP_STATUS_FD16TO: nonqueued-sender-com-spec{data-element=VeCANR_b_MC_SGCP_STATUS_FD16TO, init-value=VeCANR_b_MC_SGCP_STATUS_FD16TOValue:0}, provided-interface=VeCANR_b_MC_SGCP_STATUS_FD16TO
      VeCANR_T_SGCPCtrlBoarTempP_FD16: nonqueued-sender-com-spec{data-element=VeCANR_T_SGCPCtrlBoarTempP_FD16, init-value=VeCANR_T_SGCPCtrlBoarTempP_FD16Value:215}, provided-interface=VeCANR_T_SGCPCtrlBoarTempP_FD16
      VeCANR_b_SGCPCtrlBoarTempP_FD16TO: nonqueued-sender-com-spec{data-element=VeCANR_b_SGCPCtrlBoarTempP_FD16TO, init-value=VeCANR_b_SGCPCtrlBoarTempP_FD16TOValue:0}, provided-interface=VeCANR_b_SGCPCtrlBoarTempP_FD16TO
      VeCANR_T_SGCP_CoolantTmp_P_FD16: nonqueued-sender-com-spec{data-element=VeCANR_T_SGCP_CoolantTmp_P_FD16, init-value=VeCANR_T_SGCP_CoolantTmp_P_FD16Value:-40}, provided-interface=VeCANR_T_SGCP_CoolantTmp_P_FD16
      VeCANR_b_SGCP_CoolantTmp_P_FD16TO: nonqueued-sender-com-spec{data-element=VeCANR_b_SGCP_CoolantTmp_P_FD16TO, init-value=VeCANR_b_SGCP_CoolantTmp_P_FD16TOValue:0}, provided-interface=VeCANR_b_SGCP_CoolantTmp_P_FD16TO
      VeCANR_I_SGCP_DC_Current_P_FD16: nonqueued-sender-com-spec{data-element=VeCANR_I_SGCP_DC_Current_P_FD16, init-value=VeCANR_I_SGCP_DC_Current_P_FD16Value:0}, provided-interface=VeCANR_I_SGCP_DC_Current_P_FD16
      VeCANR_b_SGCP_DC_Current_P_FD16TO: nonqueued-sender-com-spec{data-element=VeCANR_b_SGCP_DC_Current_P_FD16TO, init-value=VeCANR_b_SGCP_DC_Current_P_FD16TOValue:0}, provided-interface=VeCANR_b_SGCP_DC_Current_P_FD16TO
      VeCANR_b_SGCP_DC_Crrnt_V_P_FD16: nonqueued-sender-com-spec{data-element=VeCANR_b_SGCP_DC_Crrnt_V_P_FD16, init-value=VeCANR_b_SGCP_DC_Crrnt_V_P_FD16Value:0}, provided-interface=VeCANR_b_SGCP_DC_Crrnt_V_P_FD16
      VeCANR_b_SGCP_DC_Crrnt_V_P_FD16TO: nonqueued-sender-com-spec{data-element=VeCANR_b_SGCP_DC_Crrnt_V_P_FD16TO, init-value=VeCANR_b_SGCP_DC_Crrnt_V_P_FD16TOValue:0}, provided-interface=VeCANR_b_SGCP_DC_Crrnt_V_P_FD16TO
      VeCANR_b_SGCP_DC_Volt_V_P_FD16: nonqueued-sender-com-spec{data-element=VeCANR_b_SGCP_DC_Volt_V_P_FD16, init-value=VeCANR_b_SGCP_DC_Volt_V_P_FD16Value:0}, provided-interface=VeCANR_b_SGCP_DC_Volt_V_P_FD16
      VeCANR_b_SGCP_DC_Volt_V_P_FD16TO: nonqueued-sender-com-spec{data-element=VeCANR_b_SGCP_DC_Volt_V_P_FD16TO, init-value=VeCANR_b_SGCP_DC_Volt_V_P_FD16TOValue:0}, provided-interface=VeCANR_b_SGCP_DC_Volt_V_P_FD16TO
      VeCANR_U_SGCP_DC_Voltage_P_FD16: nonqueued-sender-com-spec{data-element=VeCANR_U_SGCP_DC_Voltage_P_FD16, init-value=VeCANR_U_SGCP_DC_Voltage_P_FD16Value:0}, provided-interface=VeCANR_U_SGCP_DC_Voltage_P_FD16
      VeCANR_b_SGCP_DC_Voltage_P_FD16TO: nonqueued-sender-com-spec{data-element=VeCANR_b_SGCP_DC_Voltage_P_FD16TO, init-value=VeCANR_b_SGCP_DC_Voltage_P_FD16TOValue:0}, provided-interface=VeCANR_b_SGCP_DC_Voltage_P_FD16TO
      VeCANR_e_SGCP_DerateResn_P_FD16: nonqueued-sender-com-spec{data-element=VeCANR_e_SGCP_DerateResn_P_FD16, init-value=VeCANR_e_SGCP_DerateResn_P_FD16Value:0}, provided-interface=VeCANR_e_SGCP_DerateResn_P_FD16
      VeCANR_b_SGCP_DerateResn_P_FD16TO: nonqueued-sender-com-spec{data-element=VeCANR_b_SGCP_DerateResn_P_FD16TO, init-value=VeCANR_b_SGCP_DerateResn_P_FD16TOValue:0}, provided-interface=VeCANR_b_SGCP_DerateResn_P_FD16TO
      VeCANR_T_SGCP_InvertTemp_P_FD16: nonqueued-sender-com-spec{data-element=VeCANR_T_SGCP_InvertTemp_P_FD16, init-value=VeCANR_T_SGCP_InvertTemp_P_FD16Value:0}, provided-interface=VeCANR_T_SGCP_InvertTemp_P_FD16
      VeCANR_b_SGCP_InvertTemp_P_FD16TO: nonqueued-sender-com-spec{data-element=VeCANR_b_SGCP_InvertTemp_P_FD16TO, init-value=VeCANR_b_SGCP_InvertTemp_P_FD16TOValue:0}, provided-interface=VeCANR_b_SGCP_InvertTemp_P_FD16TO
      VeCANR_y_SGCPPIMACSdBusTmpPFD16: nonqueued-sender-com-spec{data-element=VeCANR_y_SGCPPIMACSdBusTmpPFD16, init-value=VeCANR_y_SGCPPIMACSdBusTmpPFD16Value:-40}, provided-interface=VeCANR_y_SGCPPIMACSdBusTmpPFD16
      VeCANR_b_SGCPPIMACSdBusTmpPFD16TO: nonqueued-sender-com-spec{data-element=VeCANR_b_SGCPPIMACSdBusTmpPFD16TO, init-value=VeCANR_b_SGCPPIMACSdBusTmpPFD16TOValue:0}, provided-interface=VeCANR_b_SGCPPIMACSdBusTmpPFD16TO
      VeCANR_T_SGCPPIMDCSdBusTmpPFD16: nonqueued-sender-com-spec{data-element=VeCANR_T_SGCPPIMDCSdBusTmpPFD16, init-value=VeCANR_T_SGCPPIMDCSdBusTmpPFD16Value:-40}, provided-interface=VeCANR_T_SGCPPIMDCSdBusTmpPFD16
      VeCANR_b_SGCPPIMDCSdBusTmpPFD16TO: nonqueued-sender-com-spec{data-element=VeCANR_b_SGCPPIMDCSdBusTmpPFD16TO, init-value=VeCANR_b_SGCPPIMDCSdBusTmpPFD16TOValue:0}, provided-interface=VeCANR_b_SGCPPIMDCSdBusTmpPFD16TO
      VeCANR_T_SGCPRotorTemp_P_FD16: nonqueued-sender-com-spec{data-element=VeCANR_T_SGCPRotorTemp_P_FD16, init-value=VeCANR_T_SGCPRotorTemp_P_FD16Value:215}, provided-interface=VeCANR_T_SGCPRotorTemp_P_FD16
      VeCANR_b_SGCPRotorTemp_P_FD16TO: nonqueued-sender-com-spec{data-element=VeCANR_b_SGCPRotorTemp_P_FD16TO, init-value=VeCANR_b_SGCPRotorTemp_P_FD16TOValue:0}, provided-interface=VeCANR_b_SGCPRotorTemp_P_FD16TO
      VeCANR_b_SGCPServLampReq_P_FD16: nonqueued-sender-com-spec{data-element=VeCANR_b_SGCPServLampReq_P_FD16, init-value=VeCANR_b_SGCPServLampReq_P_FD16Value:0}, provided-interface=VeCANR_b_SGCPServLampReq_P_FD16
      VeCANR_b_SGCPServLampReq_P_FD16TO: nonqueued-sender-com-spec{data-element=VeCANR_b_SGCPServLampReq_P_FD16TO, init-value=VeCANR_b_SGCPServLampReq_P_FD16TOValue:0}, provided-interface=VeCANR_b_SGCPServLampReq_P_FD16TO
    76 x require port:
      SendCANR_CmdIgnSts_FD16: nonqueued-receiver-com-spec{data-element=SendCANR_CmdIgnSts_FD16, init-value=SendCANR_CmdIgnSts_FD16Value:0}, required-interface=SendCANR_CmdIgnSts_FD16
      SendCANR_CmdIgnSts_FD16Vld: nonqueued-receiver-com-spec{data-element=SendCANR_CmdIgnSts_FD16Vld, init-value=SendCANR_CmdIgnSts_FD16VldValue:1}, required-interface=SendCANR_CmdIgnSts_FD16Vld
      SendCANR_CRC_BCM10_FD16: nonqueued-receiver-com-spec{data-element=SendCANR_CRC_BCM10_FD16, init-value=SendCANR_CRC_BCM10_FD16Value:0}, required-interface=SendCANR_CRC_BCM10_FD16
      SendCANR_CRC_BCM10_FD16Vld: nonqueued-receiver-com-spec{data-element=SendCANR_CRC_BCM10_FD16Vld, init-value=SendCANR_CRC_BCM10_FD16VldValue:1}, required-interface=SendCANR_CRC_BCM10_FD16Vld
      SendCANR_MsgCounter_BCM10_FD16: nonqueued-receiver-com-spec{data-element=SendCANR_MsgCounter_BCM10_FD16, init-value=SendCANR_MsgCounter_BCM10_FD16Value:0}, required-interface=SendCANR_MsgCounter_BCM10_FD16
      SendCANR_MsgCounter_BCM10_FD16Vld: nonqueued-receiver-com-spec{data-element=SendCANR_MsgCounter_BCM10_FD16Vld, init-value=SendCANR_MsgCounter_BCM10_FD16VldValue:1}, required-interface=SendCANR_MsgCounter_BCM10_FD16Vld
      SendCANR_OperationalModeStsFD16: nonqueued-receiver-com-spec{data-element=SendCANR_OperationalModeStsFD16, init-value=SendCANR_OperationalModeStsFD16Value:0}, required-interface=SendCANR_OperationalModeStsFD16
      SendCANR_OperationalModeStsFD16Vld: nonqueued-receiver-com-spec{data-element=SendCANR_OperationalModeStsFD16Vld, init-value=SendCANR_OperationalModeStsFD16VldValue:1}, required-interface=SendCANR_OperationalModeStsFD16Vld
      SendCANR_ExtTemp_FD16: nonqueued-receiver-com-spec{data-element=SendCANR_ExtTemp_FD16, init-value=SendCANR_ExtTemp_FD16Value:-85}, required-interface=SendCANR_ExtTemp_FD16
      SendCANR_ExtTemp_FD16Vld: nonqueued-receiver-com-spec{data-element=SendCANR_ExtTemp_FD16Vld, init-value=SendCANR_ExtTemp_FD16VldValue:1}, required-interface=SendCANR_ExtTemp_FD16Vld
      SendCANR_EPBSts_FD16: nonqueued-receiver-com-spec{data-element=SendCANR_EPBSts_FD16, init-value=SendCANR_EPBSts_FD16Value:0}, required-interface=SendCANR_EPBSts_FD16
      SendCANR_EPBSts_FD16Vld: nonqueued-receiver-com-spec{data-element=SendCANR_EPBSts_FD16Vld, init-value=SendCANR_EPBSts_FD16VldValue:1}, required-interface=SendCANR_EPBSts_FD16Vld
      SendCANR_ABSFailSts_FD16: nonqueued-receiver-com-spec{data-element=SendCANR_ABSFailSts_FD16, init-value=SendCANR_ABSFailSts_FD16Value:0}, required-interface=SendCANR_ABSFailSts_FD16
      SendCANR_ABSFailSts_FD16Vld: nonqueued-receiver-com-spec{data-element=SendCANR_ABSFailSts_FD16Vld, init-value=SendCANR_ABSFailSts_FD16VldValue:1}, required-interface=SendCANR_ABSFailSts_FD16Vld
      SendCANR_ESCFailSts: nonqueued-receiver-com-spec{data-element=SendCANR_ESCFailSts, init-value=SendCANR_ESCFailStsValue:0}, required-interface=SendCANR_ESCFailSts
      SendCANR_ESCFailStsVld: nonqueued-receiver-com-spec{data-element=SendCANR_ESCFailStsVld, init-value=SendCANR_ESCFailStsVldValue:1}, required-interface=SendCANR_ESCFailStsVld
      SendCANR_N_PDU_7E_FD16: nonqueued-receiver-com-spec{data-element=SendCANR_N_PDU_7E_FD16, init-value=SendCANR_N_PDU_7E_FD16Value:0}, required-interface=SendCANR_N_PDU_7E_FD16
      SendCANR_N_PDU_7E_FD16Vld: nonqueued-receiver-com-spec{data-element=SendCANR_N_PDU_7E_FD16Vld, init-value=SendCANR_N_PDU_7E_FD16VldValue:1}, required-interface=SendCANR_N_PDU_7E_FD16Vld
      SendCANR_N_PDU_7F_FD16: nonqueued-receiver-com-spec{data-element=SendCANR_N_PDU_7F_FD16, init-value=SendCANR_N_PDU_7F_FD16Value:0}, required-interface=SendCANR_N_PDU_7F_FD16
      SendCANR_N_PDU_7F_FD16Vld: nonqueued-receiver-com-spec{data-element=SendCANR_N_PDU_7F_FD16Vld, init-value=SendCANR_N_PDU_7F_FD16VldValue:1}, required-interface=SendCANR_N_PDU_7F_FD16Vld
      SendCANR_N_PDU_81: nonqueued-receiver-com-spec{data-element=SendCANR_N_PDU_81, init-value=SendCANR_N_PDU_81Value:0}, required-interface=SendCANR_N_PDU_81
      SendCANR_N_PDU_81Vld: nonqueued-receiver-com-spec{data-element=SendCANR_N_PDU_81Vld, init-value=SendCANR_N_PDU_81VldValue:1}, required-interface=SendCANR_N_PDU_81Vld
      SendCANR_PerWakeUp_Diag_FD16: nonqueued-receiver-com-spec{data-element=SendCANR_PerWakeUp_Diag_FD16, init-value=SendCANR_PerWakeUp_Diag_FD16Value:0}, required-interface=SendCANR_PerWakeUp_Diag_FD16
      SendCANR_PerWakeUp_Diag_FD16Vld: nonqueued-receiver-com-spec{data-element=SendCANR_PerWakeUp_Diag_FD16Vld, init-value=SendCANR_PerWakeUp_Diag_FD16VldValue:1}, required-interface=SendCANR_PerWakeUp_Diag_FD16Vld
      SendCANR_WU_Timer_Value_FD16: nonqueued-receiver-com-spec{data-element=SendCANR_WU_Timer_Value_FD16, init-value=SendCANR_WU_Timer_Value_FD16Value:0}, required-interface=SendCANR_WU_Timer_Value_FD16
      SendCANR_WU_Timer_Value_FD16Vld: nonqueued-receiver-com-spec{data-element=SendCANR_WU_Timer_Value_FD16Vld, init-value=SendCANR_WU_Timer_Value_FD16VldValue:1}, required-interface=SendCANR_WU_Timer_Value_FD16Vld
      SendCANR_CRC_HYB_THRM_CMND_FD16: nonqueued-receiver-com-spec{data-element=SendCANR_CRC_HYB_THRM_CMND_FD16, init-value=SendCANR_CRC_HYB_THRM_CMND_FD16Value:0}, required-interface=SendCANR_CRC_HYB_THRM_CMND_FD16
      SendCANR_CRC_HYB_THRM_CMND_FD16Vld: nonqueued-receiver-com-spec{data-element=SendCANR_CRC_HYB_THRM_CMND_FD16Vld, init-value=SendCANR_CRC_HYB_THRM_CMND_FD16VldValue:1}, required-interface=SendCANR_CRC_HYB_THRM_CMND_FD16Vld
      SendCANR_EOPA_OIL_FlwRate_FD16: nonqueued-receiver-com-spec{data-element=SendCANR_EOPA_OIL_FlwRate_FD16, init-value=SendCANR_EOPA_OIL_FlwRate_FD16Value:0}, required-interface=SendCANR_EOPA_OIL_FlwRate_FD16
      SendCANR_EOPA_OIL_FlwRate_FD16Vld: nonqueued-receiver-com-spec{data-element=SendCANR_EOPA_OIL_FlwRate_FD16Vld, init-value=SendCANR_EOPA_OIL_FlwRate_FD16VldValue:1}, required-interface=SendCANR_EOPA_OIL_FlwRate_FD16Vld
      SendCANR_EOPA_OIL_TEMP_FD16: nonqueued-receiver-com-spec{data-element=SendCANR_EOPA_OIL_TEMP_FD16, init-value=SendCANR_EOPA_OIL_TEMP_FD16Value:-50}, required-interface=SendCANR_EOPA_OIL_TEMP_FD16
      SendCANR_EOPA_OIL_TEMP_FD16Vld: nonqueued-receiver-com-spec{data-element=SendCANR_EOPA_OIL_TEMP_FD16Vld, init-value=SendCANR_EOPA_OIL_TEMP_FD16VldValue:1}, required-interface=SendCANR_EOPA_OIL_TEMP_FD16Vld
      SendCANR_EOPB_OIL_FlwRate_FD16: nonqueued-receiver-com-spec{data-element=SendCANR_EOPB_OIL_FlwRate_FD16, init-value=SendCANR_EOPB_OIL_FlwRate_FD16Value:0}, required-interface=SendCANR_EOPB_OIL_FlwRate_FD16
      SendCANR_EOPB_OIL_FlwRate_FD16Vld: nonqueued-receiver-com-spec{data-element=SendCANR_EOPB_OIL_FlwRate_FD16Vld, init-value=SendCANR_EOPB_OIL_FlwRate_FD16VldValue:1}, required-interface=SendCANR_EOPB_OIL_FlwRate_FD16Vld
      SendCANR_EOPB_OIL_TEMP_FD16: nonqueued-receiver-com-spec{data-element=SendCANR_EOPB_OIL_TEMP_FD16, init-value=SendCANR_EOPB_OIL_TEMP_FD16Value:-50}, required-interface=SendCANR_EOPB_OIL_TEMP_FD16
      SendCANR_EOPB_OIL_TEMP_FD16Vld: nonqueued-receiver-com-spec{data-element=SendCANR_EOPB_OIL_TEMP_FD16Vld, init-value=SendCANR_EOPB_OIL_TEMP_FD16VldValue:1}, required-interface=SendCANR_EOPB_OIL_TEMP_FD16Vld
      SendCANR_MC_HYBD_THRM_CMND_FD16: nonqueued-receiver-com-spec{data-element=SendCANR_MC_HYBD_THRM_CMND_FD16, init-value=SendCANR_MC_HYBD_THRM_CMND_FD16Value:0}, required-interface=SendCANR_MC_HYBD_THRM_CMND_FD16
      SendCANR_MC_HYBD_THRM_CMND_FD16Vld: nonqueued-receiver-com-spec{data-element=SendCANR_MC_HYBD_THRM_CMND_FD16Vld, init-value=SendCANR_MC_HYBD_THRM_CMND_FD16VldValue:1}, required-interface=SendCANR_MC_HYBD_THRM_CMND_FD16Vld
      SendCANR_SGCP_OIL_FlwRate_FD16: nonqueued-receiver-com-spec{data-element=SendCANR_SGCP_OIL_FlwRate_FD16, init-value=SendCANR_SGCP_OIL_FlwRate_FD16Value:0}, required-interface=SendCANR_SGCP_OIL_FlwRate_FD16
      SendCANR_SGCP_OIL_FlwRate_FD16Vld: nonqueued-receiver-com-spec{data-element=SendCANR_SGCP_OIL_FlwRate_FD16Vld, init-value=SendCANR_SGCP_OIL_FlwRate_FD16VldValue:1}, required-interface=SendCANR_SGCP_OIL_FlwRate_FD16Vld
      SendCANR_SGCP_OIL_TEMP_FD16: nonqueued-receiver-com-spec{data-element=SendCANR_SGCP_OIL_TEMP_FD16, init-value=SendCANR_SGCP_OIL_TEMP_FD16Value:-50}, required-interface=SendCANR_SGCP_OIL_TEMP_FD16
      SendCANR_SGCP_OIL_TEMP_FD16Vld: nonqueued-receiver-com-spec{data-element=SendCANR_SGCP_OIL_TEMP_FD16Vld, init-value=SendCANR_SGCP_OIL_TEMP_FD16VldValue:1}, required-interface=SendCANR_SGCP_OIL_TEMP_FD16Vld
      SendCANR_IMPACTCommand_FD16: nonqueued-receiver-com-spec{data-element=SendCANR_IMPACTCommand_FD16, init-value=SendCANR_IMPACTCommand_FD16Value:0}, required-interface=SendCANR_IMPACTCommand_FD16
      SendCANR_IMPACTCommand_FD16Vld: nonqueued-receiver-com-spec{data-element=SendCANR_IMPACTCommand_FD16Vld, init-value=SendCANR_IMPACTCommand_FD16VldValue:1}, required-interface=SendCANR_IMPACTCommand_FD16Vld
      SendCANR_IMPACTConfirm_FD16: nonqueued-receiver-com-spec{data-element=SendCANR_IMPACTConfirm_FD16, init-value=SendCANR_IMPACTConfirm_FD16Value:1}, required-interface=SendCANR_IMPACTConfirm_FD16
      SendCANR_IMPACTConfirm_FD16Vld: nonqueued-receiver-com-spec{data-element=SendCANR_IMPACTConfirm_FD16Vld, init-value=SendCANR_IMPACTConfirm_FD16VldValue:1}, required-interface=SendCANR_IMPACTConfirm_FD16Vld
      SendCANR_TotalOdometer_FD16: nonqueued-receiver-com-spec{data-element=SendCANR_TotalOdometer_FD16, init-value=SendCANR_TotalOdometer_FD16Value:0}, required-interface=SendCANR_TotalOdometer_FD16
      SendCANR_TotalOdometer_FD16Vld: nonqueued-receiver-com-spec{data-element=SendCANR_TotalOdometer_FD16Vld, init-value=SendCANR_TotalOdometer_FD16VldValue:1}, required-interface=SendCANR_TotalOdometer_FD16Vld
      SendCANR_Real_Time_Clock_FD16: nonqueued-receiver-com-spec{data-element=SendCANR_Real_Time_Clock_FD16, init-value=SendCANR_Real_Time_Clock_FD16Value:0}, required-interface=SendCANR_Real_Time_Clock_FD16
      SendCANR_Real_Time_Clock_FD16Vld: nonqueued-receiver-com-spec{data-element=SendCANR_Real_Time_Clock_FD16Vld, init-value=SendCANR_Real_Time_Clock_FD16VldValue:1}, required-interface=SendCANR_Real_Time_Clock_FD16Vld
      SendCANR_Real_Time_Valdity_FD16: nonqueued-receiver-com-spec{data-element=SendCANR_Real_Time_Valdity_FD16, init-value=SendCANR_Real_Time_Valdity_FD16Value:0}, required-interface=SendCANR_Real_Time_Valdity_FD16
      SendCANR_Real_Time_Valdity_FD16Vld: nonqueued-receiver-com-spec{data-element=SendCANR_Real_Time_Valdity_FD16Vld, init-value=SendCANR_Real_Time_Valdity_FD16VldValue:1}, required-interface=SendCANR_Real_Time_Valdity_FD16Vld
      SendCANR_GPS_Date_Day_FD16: nonqueued-receiver-com-spec{data-element=SendCANR_GPS_Date_Day_FD16, init-value=SendCANR_GPS_Date_Day_FD16Value:255}, required-interface=SendCANR_GPS_Date_Day_FD16
      SendCANR_GPS_Date_Day_FD16Vld: nonqueued-receiver-com-spec{data-element=SendCANR_GPS_Date_Day_FD16Vld, init-value=SendCANR_GPS_Date_Day_FD16VldValue:1}, required-interface=SendCANR_GPS_Date_Day_FD16Vld
      SendCANR_GPS_Date_Month_FD16: nonqueued-receiver-com-spec{data-element=SendCANR_GPS_Date_Month_FD16, init-value=SendCANR_GPS_Date_Month_FD16Value:255}, required-interface=SendCANR_GPS_Date_Month_FD16
      SendCANR_GPS_Date_Month_FD16Vld: nonqueued-receiver-com-spec{data-element=SendCANR_GPS_Date_Month_FD16Vld, init-value=SendCANR_GPS_Date_Month_FD16VldValue:1}, required-interface=SendCANR_GPS_Date_Month_FD16Vld
      SendCANR_GPS_Date_Year_FD16: nonqueued-receiver-com-spec{data-element=SendCANR_GPS_Date_Year_FD16, init-value=SendCANR_GPS_Date_Year_FD16Value:65535}, required-interface=SendCANR_GPS_Date_Year_FD16
      SendCANR_GPS_Date_Year_FD16Vld: nonqueued-receiver-com-spec{data-element=SendCANR_GPS_Date_Year_FD16Vld, init-value=SendCANR_GPS_Date_Year_FD16VldValue:1}, required-interface=SendCANR_GPS_Date_Year_FD16Vld
      SendCANR_GPS_UTC_Hour_FD16: nonqueued-receiver-com-spec{data-element=SendCANR_GPS_UTC_Hour_FD16, init-value=SendCANR_GPS_UTC_Hour_FD16Value:255}, required-interface=SendCANR_GPS_UTC_Hour_FD16
      SendCANR_GPS_UTC_Hour_FD16Vld: nonqueued-receiver-com-spec{data-element=SendCANR_GPS_UTC_Hour_FD16Vld, init-value=SendCANR_GPS_UTC_Hour_FD16VldValue:1}, required-interface=SendCANR_GPS_UTC_Hour_FD16Vld
      SendCANR_GPS_UTC_Minute_FD16: nonqueued-receiver-com-spec{data-element=SendCANR_GPS_UTC_Minute_FD16, init-value=SendCANR_GPS_UTC_Minute_FD16Value:255}, required-interface=SendCANR_GPS_UTC_Minute_FD16
      SendCANR_GPS_UTC_Minute_FD16Vld: nonqueued-receiver-com-spec{data-element=SendCANR_GPS_UTC_Minute_FD16Vld, init-value=SendCANR_GPS_UTC_Minute_FD16VldValue:1}, required-interface=SendCANR_GPS_UTC_Minute_FD16Vld
      SendCANR_GPS_UTC_Second_FD16: nonqueued-receiver-com-spec{data-element=SendCANR_GPS_UTC_Second_FD16, init-value=SendCANR_GPS_UTC_Second_FD16Value:655.35}, required-interface=SendCANR_GPS_UTC_Second_FD16
      SendCANR_GPS_UTC_Second_FD16Vld: nonqueued-receiver-com-spec{data-element=SendCANR_GPS_UTC_Second_FD16Vld, init-value=SendCANR_GPS_UTC_Second_FD16VldValue:1}, required-interface=SendCANR_GPS_UTC_Second_FD16Vld
      SendCANR_T4_Sensor_Temp_FD16: nonqueued-receiver-com-spec{data-element=SendCANR_T4_Sensor_Temp_FD16, init-value=SendCANR_T4_Sensor_Temp_FD16Value:-40}, required-interface=SendCANR_T4_Sensor_Temp_FD16
      SendCANR_T4_Sensor_Temp_FD16Vld: nonqueued-receiver-com-spec{data-element=SendCANR_T4_Sensor_Temp_FD16Vld, init-value=SendCANR_T4_Sensor_Temp_FD16VldValue:1}, required-interface=SendCANR_T4_Sensor_Temp_FD16Vld
      SendCANR_T7_CoolntTmpVldty_FD16: nonqueued-receiver-com-spec{data-element=SendCANR_T7_CoolntTmpVldty_FD16, init-value=SendCANR_T7_CoolntTmpVldty_FD16Value:0}, required-interface=SendCANR_T7_CoolntTmpVldty_FD16
      SendCANR_T7_CoolntTmpVldty_FD16Vld: nonqueued-receiver-com-spec{data-element=SendCANR_T7_CoolntTmpVldty_FD16Vld, init-value=SendCANR_T7_CoolntTmpVldty_FD16VldValue:1}, required-interface=SendCANR_T7_CoolntTmpVldty_FD16Vld
      SendCANR_T7_Sensor_Temp_FD16: nonqueued-receiver-com-spec{data-element=SendCANR_T7_Sensor_Temp_FD16, init-value=SendCANR_T7_Sensor_Temp_FD16Value:-40}, required-interface=SendCANR_T7_Sensor_Temp_FD16
      SendCANR_T7_Sensor_Temp_FD16Vld: nonqueued-receiver-com-spec{data-element=SendCANR_T7_Sensor_Temp_FD16Vld, init-value=SendCANR_T7_Sensor_Temp_FD16VldValue:1}, required-interface=SendCANR_T7_Sensor_Temp_FD16Vld
      SendCANR_RELSD_TgtTrq_FD16: nonqueued-receiver-com-spec{data-element=SendCANR_RELSD_TgtTrq_FD16, init-value=SendCANR_RELSD_TgtTrq_FD16Value:0}, required-interface=SendCANR_RELSD_TgtTrq_FD16
      SendCANR_RELSD_TgtTrq_FD16Vld: nonqueued-receiver-com-spec{data-element=SendCANR_RELSD_TgtTrq_FD16Vld, init-value=SendCANR_RELSD_TgtTrq_FD16VldValue:1}, required-interface=SendCANR_RELSD_TgtTrq_FD16Vld
      SendCANR_VIN_DATA_FD16: nonqueued-receiver-com-spec{data-element=SendCANR_VIN_DATA_FD16, init-value=SendCANR_VIN_DATA_FD16Value:0}, required-interface=SendCANR_VIN_DATA_FD16
      SendCANR_VIN_DATA_FD16Vld: nonqueued-receiver-com-spec{data-element=SendCANR_VIN_DATA_FD16Vld, init-value=SendCANR_VIN_DATA_FD16VldValue:1}, required-interface=SendCANR_VIN_DATA_FD16Vld
      SendCANR_VIN_MSG_FD16: nonqueued-receiver-com-spec{data-element=SendCANR_VIN_MSG_FD16, init-value=SendCANR_VIN_MSG_FD16Value:3}, required-interface=SendCANR_VIN_MSG_FD16
      SendCANR_VIN_MSG_FD16Vld: nonqueued-receiver-com-spec{data-element=SendCANR_VIN_MSG_FD16Vld, init-value=SendCANR_VIN_MSG_FD16VldValue:1}, required-interface=SendCANR_VIN_MSG_FD16Vld
    behavior IBApplCanComAb_FD16: data-type-mapping=ADTtoIDTMapping, handle-termination-and-restart=NO-SUPPORT
      init event IninEve: start-on-event=ApplCanComAb_FD16Inin
      data received event DRECOMRX_N_PDU_7B_GLIWA_MCPA_TX_FD16: start-on-event=COMRX_N_PDU_7B_GLIWA_MCPA_TX_FD16_Received, data=CanCom_FD16RxSignalsSR.COMRX_N_PDU_7B_GLIWA_MCPA_TX_FD16
      data receive error event DEECOMRX_N_PDU_7B_GLIWA_MCPA_TX_FD16: start-on-event=COMRX_N_PDU_7B_GLIWA_MCPA_TX_FD16_Error, data=CanCom_FD16RxSignalsSR.COMRX_N_PDU_7B_GLIWA_MCPA_TX_FD16
      data received event DRECOMRX_N_PDU_7C_GLIWA_MCPB_TX_FD16: start-on-event=COMRX_N_PDU_7C_GLIWA_MCPB_TX_FD16_Received, data=CanCom_FD16RxSignalsSR.COMRX_N_PDU_7C_GLIWA_MCPB_TX_FD16
      data receive error event DEECOMRX_N_PDU_7C_GLIWA_MCPB_TX_FD16: start-on-event=COMRX_N_PDU_7C_GLIWA_MCPB_TX_FD16_Error, data=CanCom_FD16RxSignalsSR.COMRX_N_PDU_7C_GLIWA_MCPB_TX_FD16
      data received event DRECOMRX_N_PDU_86_GLIWA_SGCP_TX_FD16: start-on-event=COMRX_N_PDU_86_GLIWA_SGCP_TX_FD16_Received, data=CanCom_FD16RxSignalsSR.COMRX_N_PDU_86_GLIWA_SGCP_TX_FD16
      data receive error event DEECOMRX_N_PDU_86_GLIWA_SGCP_TX_FD16: start-on-event=COMRX_N_PDU_86_GLIWA_SGCP_TX_FD16_Error, data=CanCom_FD16RxSignalsSR.COMRX_N_PDU_86_GLIWA_SGCP_TX_FD16
      data received event DRECOMRX_CLrDiagInfo_MCPA_P_MCPA_STATUS_FD16: start-on-event=COMRX_CLrDiagInfo_MCPA_P_MCPA_STATUS_FD16_Received, data=CanCom_FD16RxSignalsSR.COMRX_CLrDiagInfo_MCPA_P_MCPA_STATUS_FD16
      data receive error event DEECOMRX_CLrDiagInfo_MCPA_P_MCPA_STATUS_FD16: start-on-event=COMRX_CLrDiagInfo_MCPA_P_MCPA_STATUS_FD16_Error, data=CanCom_FD16RxSignalsSR.COMRX_CLrDiagInfo_MCPA_P_MCPA_STATUS_FD16
      data received event DRECOMRX_CRC_MCPA_STATUS_MCPA_STATUS_FD16: start-on-event=COMRX_CRC_MCPA_STATUS_MCPA_STATUS_FD16_Received, data=CanCom_FD16RxSignalsSR.COMRX_CRC_MCPA_STATUS_MCPA_STATUS_FD16
      data receive error event DEECOMRX_CRC_MCPA_STATUS_MCPA_STATUS_FD16: start-on-event=COMRX_CRC_MCPA_STATUS_MCPA_STATUS_FD16_Error, data=CanCom_FD16RxSignalsSR.COMRX_CRC_MCPA_STATUS_MCPA_STATUS_FD16
      data received event DRECOMRX_MC_MCPA_STATUS_MCPA_STATUS_FD16: start-on-event=COMRX_MC_MCPA_STATUS_MCPA_STATUS_FD16_Received, data=CanCom_FD16RxSignalsSR.COMRX_MC_MCPA_STATUS_MCPA_STATUS_FD16
      data receive error event DEECOMRX_MC_MCPA_STATUS_MCPA_STATUS_FD16: start-on-event=COMRX_MC_MCPA_STATUS_MCPA_STATUS_FD16_Error, data=CanCom_FD16RxSignalsSR.COMRX_MC_MCPA_STATUS_MCPA_STATUS_FD16
      data received event DRECOMRX_MCPA_Control_Board_Temperature_P_MCPA_STATUS_FD16: start-on-event=COMRX_MCPA_Control_Board_Temperature_P_MCPA_STATUS_FD16_Received, data=CanCom_FD16RxSignalsSR.COMRX_MCPA_Control_Board_Temperature_P_MCPA_STATUS_FD16
      data receive error event DEECOMRX_MCPA_Control_Board_Temperature_P_MCPA_STATUS_FD16: start-on-event=COMRX_MCPA_Control_Board_Temperature_P_MCPA_STATUS_FD16_Error, data=CanCom_FD16RxSignalsSR.COMRX_MCPA_Control_Board_Temperature_P_MCPA_STATUS_FD16
      data received event DRECOMRX_MCPA_CoolantTemp_P_MCPA_STATUS_FD16: start-on-event=COMRX_MCPA_CoolantTemp_P_MCPA_STATUS_FD16_Received, data=CanCom_FD16RxSignalsSR.COMRX_MCPA_CoolantTemp_P_MCPA_STATUS_FD16
      data receive error event DEECOMRX_MCPA_CoolantTemp_P_MCPA_STATUS_FD16: start-on-event=COMRX_MCPA_CoolantTemp_P_MCPA_STATUS_FD16_Error, data=CanCom_FD16RxSignalsSR.COMRX_MCPA_CoolantTemp_P_MCPA_STATUS_FD16
      data received event DRECOMRX_MCPA_DC_Current_P_MCPA_STATUS_FD16: start-on-event=COMRX_MCPA_DC_Current_P_MCPA_STATUS_FD16_Received, data=CanCom_FD16RxSignalsSR.COMRX_MCPA_DC_Current_P_MCPA_STATUS_FD16
      data receive error event DEECOMRX_MCPA_DC_Current_P_MCPA_STATUS_FD16: start-on-event=COMRX_MCPA_DC_Current_P_MCPA_STATUS_FD16_Error, data=CanCom_FD16RxSignalsSR.COMRX_MCPA_DC_Current_P_MCPA_STATUS_FD16
      data received event DRECOMRX_MCPA_DC_Current_V_P_MCPA_STATUS_FD16: start-on-event=COMRX_MCPA_DC_Current_V_P_MCPA_STATUS_FD16_Received, data=CanCom_FD16RxSignalsSR.COMRX_MCPA_DC_Current_V_P_MCPA_STATUS_FD16
      data receive error event DEECOMRX_MCPA_DC_Current_V_P_MCPA_STATUS_FD16: start-on-event=COMRX_MCPA_DC_Current_V_P_MCPA_STATUS_FD16_Error, data=CanCom_FD16RxSignalsSR.COMRX_MCPA_DC_Current_V_P_MCPA_STATUS_FD16
      data received event DRECOMRX_MCPA_DC_Volt_V_P_MCPA_STATUS_FD16: start-on-event=COMRX_MCPA_DC_Volt_V_P_MCPA_STATUS_FD16_Received, data=CanCom_FD16RxSignalsSR.COMRX_MCPA_DC_Volt_V_P_MCPA_STATUS_FD16
      data receive error event DEECOMRX_MCPA_DC_Volt_V_P_MCPA_STATUS_FD16: start-on-event=COMRX_MCPA_DC_Volt_V_P_MCPA_STATUS_FD16_Error, data=CanCom_FD16RxSignalsSR.COMRX_MCPA_DC_Volt_V_P_MCPA_STATUS_FD16
      data received event DRECOMRX_MCPA_DC_Voltage_P_MCPA_STATUS_FD16: start-on-event=COMRX_MCPA_DC_Voltage_P_MCPA_STATUS_FD16_Received, data=CanCom_FD16RxSignalsSR.COMRX_MCPA_DC_Voltage_P_MCPA_STATUS_FD16
      data receive error event DEECOMRX_MCPA_DC_Voltage_P_MCPA_STATUS_FD16: start-on-event=COMRX_MCPA_DC_Voltage_P_MCPA_STATUS_FD16_Error, data=CanCom_FD16RxSignalsSR.COMRX_MCPA_DC_Voltage_P_MCPA_STATUS_FD16
      data received event DRECOMRX_MCPA_DerateReason_P_MCPA_STATUS_FD16: start-on-event=COMRX_MCPA_DerateReason_P_MCPA_STATUS_FD16_Received, data=CanCom_FD16RxSignalsSR.COMRX_MCPA_DerateReason_P_MCPA_STATUS_FD16
      data receive error event DEECOMRX_MCPA_DerateReason_P_MCPA_STATUS_FD16: start-on-event=COMRX_MCPA_DerateReason_P_MCPA_STATUS_FD16_Error, data=CanCom_FD16RxSignalsSR.COMRX_MCPA_DerateReason_P_MCPA_STATUS_FD16
      data received event DRECOMRX_MCPA_Inverter_Temp_P_MCPA_STATUS_FD16: start-on-event=COMRX_MCPA_Inverter_Temp_P_MCPA_STATUS_FD16_Received, data=CanCom_FD16RxSignalsSR.COMRX_MCPA_Inverter_Temp_P_MCPA_STATUS_FD16
      data receive error event DEECOMRX_MCPA_Inverter_Temp_P_MCPA_STATUS_FD16: start-on-event=COMRX_MCPA_Inverter_Temp_P_MCPA_STATUS_FD16_Error, data=CanCom_FD16RxSignalsSR.COMRX_MCPA_Inverter_Temp_P_MCPA_STATUS_FD16
      data received event DRECOMRX_MCPA_PIM_DC_Side_Busbar_Temp_P_MCPA_STATUS_FD16: start-on-event=COMRX_MCPA_PIM_DC_Side_Busbar_Temp_P_MCPA_STATUS_FD16_Received, data=CanCom_FD16RxSignalsSR.COMRX_MCPA_PIM_DC_Side_Busbar_Temp_P_MCPA_STATUS_FD16
      data receive error event DEECOMRX_MCPA_PIM_DC_Side_Busbar_Temp_P_MCPA_STATUS_FD16: start-on-event=COMRX_MCPA_PIM_DC_Side_Busbar_Temp_P_MCPA_STATUS_FD16_Error, data=CanCom_FD16RxSignalsSR.COMRX_MCPA_PIM_DC_Side_Busbar_Temp_P_MCPA_STATUS_FD16
      data received event DRECOMRX_MCPA_Rotor_Temperature_P_MCPA_STATUS_FD16: start-on-event=COMRX_MCPA_Rotor_Temperature_P_MCPA_STATUS_FD16_Received, data=CanCom_FD16RxSignalsSR.COMRX_MCPA_Rotor_Temperature_P_MCPA_STATUS_FD16
      data receive error event DEECOMRX_MCPA_Rotor_Temperature_P_MCPA_STATUS_FD16: start-on-event=COMRX_MCPA_Rotor_Temperature_P_MCPA_STATUS_FD16_Error, data=CanCom_FD16RxSignalsSR.COMRX_MCPA_Rotor_Temperature_P_MCPA_STATUS_FD16
      data received event DRECOMRX_MCPA_Service_Lamp_Request_P_MCPA_STATUS_FD16: start-on-event=COMRX_MCPA_Service_Lamp_Request_P_MCPA_STATUS_FD16_Received, data=CanCom_FD16RxSignalsSR.COMRX_MCPA_Service_Lamp_Request_P_MCPA_STATUS_FD16
      data receive error event DEECOMRX_MCPA_Service_Lamp_Request_P_MCPA_STATUS_FD16: start-on-event=COMRX_MCPA_Service_Lamp_Request_P_MCPA_STATUS_FD16_Error, data=CanCom_FD16RxSignalsSR.COMRX_MCPA_Service_Lamp_Request_P_MCPA_STATUS_FD16
      data received event DRECOMRX_CLrDiagInfo_MCPB_P_MCPB_STATUS_FD16: start-on-event=COMRX_CLrDiagInfo_MCPB_P_MCPB_STATUS_FD16_Received, data=CanCom_FD16RxSignalsSR.COMRX_CLrDiagInfo_MCPB_P_MCPB_STATUS_FD16
      data receive error event DEECOMRX_CLrDiagInfo_MCPB_P_MCPB_STATUS_FD16: start-on-event=COMRX_CLrDiagInfo_MCPB_P_MCPB_STATUS_FD16_Error, data=CanCom_FD16RxSignalsSR.COMRX_CLrDiagInfo_MCPB_P_MCPB_STATUS_FD16
      data received event DRECOMRX_CRC_MCPB_STATUS_MCPB_STATUS_FD16: start-on-event=COMRX_CRC_MCPB_STATUS_MCPB_STATUS_FD16_Received, data=CanCom_FD16RxSignalsSR.COMRX_CRC_MCPB_STATUS_MCPB_STATUS_FD16
      data receive error event DEECOMRX_CRC_MCPB_STATUS_MCPB_STATUS_FD16: start-on-event=COMRX_CRC_MCPB_STATUS_MCPB_STATUS_FD16_Error, data=CanCom_FD16RxSignalsSR.COMRX_CRC_MCPB_STATUS_MCPB_STATUS_FD16
      data received event DRECOMRX_MC_MCPB_STATUS_MCPB_STATUS_FD16: start-on-event=COMRX_MC_MCPB_STATUS_MCPB_STATUS_FD16_Received, data=CanCom_FD16RxSignalsSR.COMRX_MC_MCPB_STATUS_MCPB_STATUS_FD16
      data receive error event DEECOMRX_MC_MCPB_STATUS_MCPB_STATUS_FD16: start-on-event=COMRX_MC_MCPB_STATUS_MCPB_STATUS_FD16_Error, data=CanCom_FD16RxSignalsSR.COMRX_MC_MCPB_STATUS_MCPB_STATUS_FD16
      data received event DRECOMRX_MCPB_Control_Board_Temperature_P_MCPB_STATUS_FD16: start-on-event=COMRX_MCPB_Control_Board_Temperature_P_MCPB_STATUS_FD16_Received, data=CanCom_FD16RxSignalsSR.COMRX_MCPB_Control_Board_Temperature_P_MCPB_STATUS_FD16
      data receive error event DEECOMRX_MCPB_Control_Board_Temperature_P_MCPB_STATUS_FD16: start-on-event=COMRX_MCPB_Control_Board_Temperature_P_MCPB_STATUS_FD16_Error, data=CanCom_FD16RxSignalsSR.COMRX_MCPB_Control_Board_Temperature_P_MCPB_STATUS_FD16
      data received event DRECOMRX_MCPB_CoolantTemp_P_MCPB_STATUS_FD16: start-on-event=COMRX_MCPB_CoolantTemp_P_MCPB_STATUS_FD16_Received, data=CanCom_FD16RxSignalsSR.COMRX_MCPB_CoolantTemp_P_MCPB_STATUS_FD16
      data receive error event DEECOMRX_MCPB_CoolantTemp_P_MCPB_STATUS_FD16: start-on-event=COMRX_MCPB_CoolantTemp_P_MCPB_STATUS_FD16_Error, data=CanCom_FD16RxSignalsSR.COMRX_MCPB_CoolantTemp_P_MCPB_STATUS_FD16
      data received event DRECOMRX_MCPB_DC_Current_P_MCPB_STATUS_FD16: start-on-event=COMRX_MCPB_DC_Current_P_MCPB_STATUS_FD16_Received, data=CanCom_FD16RxSignalsSR.COMRX_MCPB_DC_Current_P_MCPB_STATUS_FD16
      data receive error event DEECOMRX_MCPB_DC_Current_P_MCPB_STATUS_FD16: start-on-event=COMRX_MCPB_DC_Current_P_MCPB_STATUS_FD16_Error, data=CanCom_FD16RxSignalsSR.COMRX_MCPB_DC_Current_P_MCPB_STATUS_FD16
      data received event DRECOMRX_MCPB_DC_Current_V_P_MCPB_STATUS_FD16: start-on-event=COMRX_MCPB_DC_Current_V_P_MCPB_STATUS_FD16_Received, data=CanCom_FD16RxSignalsSR.COMRX_MCPB_DC_Current_V_P_MCPB_STATUS_FD16
      data receive error event DEECOMRX_MCPB_DC_Current_V_P_MCPB_STATUS_FD16: start-on-event=COMRX_MCPB_DC_Current_V_P_MCPB_STATUS_FD16_Error, data=CanCom_FD16RxSignalsSR.COMRX_MCPB_DC_Current_V_P_MCPB_STATUS_FD16
      data received event DRECOMRX_MCPB_DC_Volt_V_P_MCPB_STATUS_FD16: start-on-event=COMRX_MCPB_DC_Volt_V_P_MCPB_STATUS_FD16_Received, data=CanCom_FD16RxSignalsSR.COMRX_MCPB_DC_Volt_V_P_MCPB_STATUS_FD16
      data receive error event DEECOMRX_MCPB_DC_Volt_V_P_MCPB_STATUS_FD16: start-on-event=COMRX_MCPB_DC_Volt_V_P_MCPB_STATUS_FD16_Error, data=CanCom_FD16RxSignalsSR.COMRX_MCPB_DC_Volt_V_P_MCPB_STATUS_FD16
      data received event DRECOMRX_MCPB_DC_Voltage_P_MCPB_STATUS_FD16: start-on-event=COMRX_MCPB_DC_Voltage_P_MCPB_STATUS_FD16_Received, data=CanCom_FD16RxSignalsSR.COMRX_MCPB_DC_Voltage_P_MCPB_STATUS_FD16
      data receive error event DEECOMRX_MCPB_DC_Voltage_P_MCPB_STATUS_FD16: start-on-event=COMRX_MCPB_DC_Voltage_P_MCPB_STATUS_FD16_Error, data=CanCom_FD16RxSignalsSR.COMRX_MCPB_DC_Voltage_P_MCPB_STATUS_FD16
      data received event DRECOMRX_MCPB_DerateReason_P_MCPB_STATUS_FD16: start-on-event=COMRX_MCPB_DerateReason_P_MCPB_STATUS_FD16_Received, data=CanCom_FD16RxSignalsSR.COMRX_MCPB_DerateReason_P_MCPB_STATUS_FD16
      data receive error event DEECOMRX_MCPB_DerateReason_P_MCPB_STATUS_FD16: start-on-event=COMRX_MCPB_DerateReason_P_MCPB_STATUS_FD16_Error, data=CanCom_FD16RxSignalsSR.COMRX_MCPB_DerateReason_P_MCPB_STATUS_FD16
      data received event DRECOMRX_MCPB_Inverter_Temp_P_MCPB_STATUS_FD16: start-on-event=COMRX_MCPB_Inverter_Temp_P_MCPB_STATUS_FD16_Received, data=CanCom_FD16RxSignalsSR.COMRX_MCPB_Inverter_Temp_P_MCPB_STATUS_FD16
      data receive error event DEECOMRX_MCPB_Inverter_Temp_P_MCPB_STATUS_FD16: start-on-event=COMRX_MCPB_Inverter_Temp_P_MCPB_STATUS_FD16_Error, data=CanCom_FD16RxSignalsSR.COMRX_MCPB_Inverter_Temp_P_MCPB_STATUS_FD16
      data received event DRECOMRX_MCPB_PIM_DC_Side_Busbar_Temp_P_MCPB_STATUS_FD16: start-on-event=COMRX_MCPB_PIM_DC_Side_Busbar_Temp_P_MCPB_STATUS_FD16_Received, data=CanCom_FD16RxSignalsSR.COMRX_MCPB_PIM_DC_Side_Busbar_Temp_P_MCPB_STATUS_FD16
      data receive error event DEECOMRX_MCPB_PIM_DC_Side_Busbar_Temp_P_MCPB_STATUS_FD16: start-on-event=COMRX_MCPB_PIM_DC_Side_Busbar_Temp_P_MCPB_STATUS_FD16_Error, data=CanCom_FD16RxSignalsSR.COMRX_MCPB_PIM_DC_Side_Busbar_Temp_P_MCPB_STATUS_FD16
      data received event DRECOMRX_MCPB_Rotor_Temperature_P_MCPB_STATUS_FD16: start-on-event=COMRX_MCPB_Rotor_Temperature_P_MCPB_STATUS_FD16_Received, data=CanCom_FD16RxSignalsSR.COMRX_MCPB_Rotor_Temperature_P_MCPB_STATUS_FD16
      data receive error event DEECOMRX_MCPB_Rotor_Temperature_P_MCPB_STATUS_FD16: start-on-event=COMRX_MCPB_Rotor_Temperature_P_MCPB_STATUS_FD16_Error, data=CanCom_FD16RxSignalsSR.COMRX_MCPB_Rotor_Temperature_P_MCPB_STATUS_FD16
      data received event DRECOMRX_MCPB_Service_Lamp_Request_P_MCPB_STATUS_FD16: start-on-event=COMRX_MCPB_Service_Lamp_Request_P_MCPB_STATUS_FD16_Received, data=CanCom_FD16RxSignalsSR.COMRX_MCPB_Service_Lamp_Request_P_MCPB_STATUS_FD16
      data receive error event DEECOMRX_MCPB_Service_Lamp_Request_P_MCPB_STATUS_FD16: start-on-event=COMRX_MCPB_Service_Lamp_Request_P_MCPB_STATUS_FD16_Error, data=CanCom_FD16RxSignalsSR.COMRX_MCPB_Service_Lamp_Request_P_MCPB_STATUS_FD16
      data received event DRECOMRX_CLrDiagInfo_SGCP_P_SGCP_STATUS_FD16: start-on-event=COMRX_CLrDiagInfo_SGCP_P_SGCP_STATUS_FD16_Received, data=CanCom_FD16RxSignalsSR.COMRX_CLrDiagInfo_SGCP_P_SGCP_STATUS_FD16
      data receive error event DEECOMRX_CLrDiagInfo_SGCP_P_SGCP_STATUS_FD16: start-on-event=COMRX_CLrDiagInfo_SGCP_P_SGCP_STATUS_FD16_Error, data=CanCom_FD16RxSignalsSR.COMRX_CLrDiagInfo_SGCP_P_SGCP_STATUS_FD16
      data received event DRECOMRX_CRC_SGCP_STATUS_SGCP_STATUS_FD16: start-on-event=COMRX_CRC_SGCP_STATUS_SGCP_STATUS_FD16_Received, data=CanCom_FD16RxSignalsSR.COMRX_CRC_SGCP_STATUS_SGCP_STATUS_FD16
      data receive error event DEECOMRX_CRC_SGCP_STATUS_SGCP_STATUS_FD16: start-on-event=COMRX_CRC_SGCP_STATUS_SGCP_STATUS_FD16_Error, data=CanCom_FD16RxSignalsSR.COMRX_CRC_SGCP_STATUS_SGCP_STATUS_FD16
      data received event DRECOMRX_MC_SGCP_STATUS_SGCP_STATUS_FD16: start-on-event=COMRX_MC_SGCP_STATUS_SGCP_STATUS_FD16_Received, data=CanCom_FD16RxSignalsSR.COMRX_MC_SGCP_STATUS_SGCP_STATUS_FD16
      data receive error event DEECOMRX_MC_SGCP_STATUS_SGCP_STATUS_FD16: start-on-event=COMRX_MC_SGCP_STATUS_SGCP_STATUS_FD16_Error, data=CanCom_FD16RxSignalsSR.COMRX_MC_SGCP_STATUS_SGCP_STATUS_FD16
      data received event DRECOMRX_SGCP_Control_Board_Temperature_P_SGCP_STATUS_FD16: start-on-event=COMRX_SGCP_Control_Board_Temperature_P_SGCP_STATUS_FD16_Received, data=CanCom_FD16RxSignalsSR.COMRX_SGCP_Control_Board_Temperature_P_SGCP_STATUS_FD16
      data receive error event DEECOMRX_SGCP_Control_Board_Temperature_P_SGCP_STATUS_FD16: start-on-event=COMRX_SGCP_Control_Board_Temperature_P_SGCP_STATUS_FD16_Error, data=CanCom_FD16RxSignalsSR.COMRX_SGCP_Control_Board_Temperature_P_SGCP_STATUS_FD16
      data received event DRECOMRX_SGCP_CoolantTemp_P_SGCP_STATUS_FD16: start-on-event=COMRX_SGCP_CoolantTemp_P_SGCP_STATUS_FD16_Received, data=CanCom_FD16RxSignalsSR.COMRX_SGCP_CoolantTemp_P_SGCP_STATUS_FD16
      data receive error event DEECOMRX_SGCP_CoolantTemp_P_SGCP_STATUS_FD16: start-on-event=COMRX_SGCP_CoolantTemp_P_SGCP_STATUS_FD16_Error, data=CanCom_FD16RxSignalsSR.COMRX_SGCP_CoolantTemp_P_SGCP_STATUS_FD16
      data received event DRECOMRX_SGCP_DC_Current_P_SGCP_STATUS_FD16: start-on-event=COMRX_SGCP_DC_Current_P_SGCP_STATUS_FD16_Received, data=CanCom_FD16RxSignalsSR.COMRX_SGCP_DC_Current_P_SGCP_STATUS_FD16
      data receive error event DEECOMRX_SGCP_DC_Current_P_SGCP_STATUS_FD16: start-on-event=COMRX_SGCP_DC_Current_P_SGCP_STATUS_FD16_Error, data=CanCom_FD16RxSignalsSR.COMRX_SGCP_DC_Current_P_SGCP_STATUS_FD16
      data received event DRECOMRX_SGCP_DC_Current_V_P_SGCP_STATUS_FD16: start-on-event=COMRX_SGCP_DC_Current_V_P_SGCP_STATUS_FD16_Received, data=CanCom_FD16RxSignalsSR.COMRX_SGCP_DC_Current_V_P_SGCP_STATUS_FD16
      data receive error event DEECOMRX_SGCP_DC_Current_V_P_SGCP_STATUS_FD16: start-on-event=COMRX_SGCP_DC_Current_V_P_SGCP_STATUS_FD16_Error, data=CanCom_FD16RxSignalsSR.COMRX_SGCP_DC_Current_V_P_SGCP_STATUS_FD16
      data received event DRECOMRX_SGCP_DC_Volt_V_P_SGCP_STATUS_FD16: start-on-event=COMRX_SGCP_DC_Volt_V_P_SGCP_STATUS_FD16_Received, data=CanCom_FD16RxSignalsSR.COMRX_SGCP_DC_Volt_V_P_SGCP_STATUS_FD16
      data receive error event DEECOMRX_SGCP_DC_Volt_V_P_SGCP_STATUS_FD16: start-on-event=COMRX_SGCP_DC_Volt_V_P_SGCP_STATUS_FD16_Error, data=CanCom_FD16RxSignalsSR.COMRX_SGCP_DC_Volt_V_P_SGCP_STATUS_FD16
      data received event DRECOMRX_SGCP_DC_Voltage_P_SGCP_STATUS_FD16: start-on-event=COMRX_SGCP_DC_Voltage_P_SGCP_STATUS_FD16_Received, data=CanCom_FD16RxSignalsSR.COMRX_SGCP_DC_Voltage_P_SGCP_STATUS_FD16
      data receive error event DEECOMRX_SGCP_DC_Voltage_P_SGCP_STATUS_FD16: start-on-event=COMRX_SGCP_DC_Voltage_P_SGCP_STATUS_FD16_Error, data=CanCom_FD16RxSignalsSR.COMRX_SGCP_DC_Voltage_P_SGCP_STATUS_FD16
      data received event DRECOMRX_SGCP_DerateReason_P_SGCP_STATUS_FD16: start-on-event=COMRX_SGCP_DerateReason_P_SGCP_STATUS_FD16_Received, data=CanCom_FD16RxSignalsSR.COMRX_SGCP_DerateReason_P_SGCP_STATUS_FD16
      data receive error event DEECOMRX_SGCP_DerateReason_P_SGCP_STATUS_FD16: start-on-event=COMRX_SGCP_DerateReason_P_SGCP_STATUS_FD16_Error, data=CanCom_FD16RxSignalsSR.COMRX_SGCP_DerateReason_P_SGCP_STATUS_FD16
      data received event DRECOMRX_SGCP_Inverter_Temp_P_SGCP_STATUS_FD16: start-on-event=COMRX_SGCP_Inverter_Temp_P_SGCP_STATUS_FD16_Received, data=CanCom_FD16RxSignalsSR.COMRX_SGCP_Inverter_Temp_P_SGCP_STATUS_FD16
      data receive error event DEECOMRX_SGCP_Inverter_Temp_P_SGCP_STATUS_FD16: start-on-event=COMRX_SGCP_Inverter_Temp_P_SGCP_STATUS_FD16_Error, data=CanCom_FD16RxSignalsSR.COMRX_SGCP_Inverter_Temp_P_SGCP_STATUS_FD16
      data received event DRECOMRX_SGCP_PIM_AC_Side_Busbar_Temp_P_SGCP_STATUS_FD16: start-on-event=COMRX_SGCP_PIM_AC_Side_Busbar_Temp_P_SGCP_STATUS_FD16_Received, data=CanCom_FD16RxSignalsSR.COMRX_SGCP_PIM_AC_Side_Busbar_Temp_P_SGCP_STATUS_FD16
      data receive error event DEECOMRX_SGCP_PIM_AC_Side_Busbar_Temp_P_SGCP_STATUS_FD16: start-on-event=COMRX_SGCP_PIM_AC_Side_Busbar_Temp_P_SGCP_STATUS_FD16_Error, data=CanCom_FD16RxSignalsSR.COMRX_SGCP_PIM_AC_Side_Busbar_Temp_P_SGCP_STATUS_FD16
      data received event DRECOMRX_SGCP_PIM_DC_Side_Busbar_Temp_P_SGCP_STATUS_FD16: start-on-event=COMRX_SGCP_PIM_DC_Side_Busbar_Temp_P_SGCP_STATUS_FD16_Received, data=CanCom_FD16RxSignalsSR.COMRX_SGCP_PIM_DC_Side_Busbar_Temp_P_SGCP_STATUS_FD16
      data receive error event DEECOMRX_SGCP_PIM_DC_Side_Busbar_Temp_P_SGCP_STATUS_FD16: start-on-event=COMRX_SGCP_PIM_DC_Side_Busbar_Temp_P_SGCP_STATUS_FD16_Error, data=CanCom_FD16RxSignalsSR.COMRX_SGCP_PIM_DC_Side_Busbar_Temp_P_SGCP_STATUS_FD16
      data received event DRECOMRX_SGCP_Rotor_Temperature_P_SGCP_STATUS_FD16: start-on-event=COMRX_SGCP_Rotor_Temperature_P_SGCP_STATUS_FD16_Received, data=CanCom_FD16RxSignalsSR.COMRX_SGCP_Rotor_Temperature_P_SGCP_STATUS_FD16
      data receive error event DEECOMRX_SGCP_Rotor_Temperature_P_SGCP_STATUS_FD16: start-on-event=COMRX_SGCP_Rotor_Temperature_P_SGCP_STATUS_FD16_Error, data=CanCom_FD16RxSignalsSR.COMRX_SGCP_Rotor_Temperature_P_SGCP_STATUS_FD16
      data received event DRECOMRX_SGCP_Service_Lamp_Request_P_SGCP_STATUS_FD16: start-on-event=COMRX_SGCP_Service_Lamp_Request_P_SGCP_STATUS_FD16_Received, data=CanCom_FD16RxSignalsSR.COMRX_SGCP_Service_Lamp_Request_P_SGCP_STATUS_FD16
      data receive error event DEECOMRX_SGCP_Service_Lamp_Request_P_SGCP_STATUS_FD16: start-on-event=COMRX_SGCP_Service_Lamp_Request_P_SGCP_STATUS_FD16_Error, data=CanCom_FD16RxSignalsSR.COMRX_SGCP_Service_Lamp_Request_P_SGCP_STATUS_FD16
      38 x data received event:
        DRESendCANR_CmdIgnSts_FD16: start-on-event=SendCANR_CmdIgnSts_FD16, data=SendCANR_CmdIgnSts_FD16.SendCANR_CmdIgnSts_FD16
        DRESendCANR_CRC_BCM10_FD16: start-on-event=SendCANR_CRC_BCM10_FD16, data=SendCANR_CRC_BCM10_FD16.SendCANR_CRC_BCM10_FD16
        DRESendCANR_MsgCounter_BCM10_FD16: start-on-event=SendCANR_MsgCounter_BCM10_FD16, data=SendCANR_MsgCounter_BCM10_FD16.SendCANR_MsgCounter_BCM10_FD16
        DRESendCANR_OperationalModeStsFD16: start-on-event=SendCANR_OperationalModeStsFD16, data=SendCANR_OperationalModeStsFD16.SendCANR_OperationalModeStsFD16
        DRESendCANR_ExtTemp_FD16: start-on-event=SendCANR_ExtTemp_FD16, data=SendCANR_ExtTemp_FD16.SendCANR_ExtTemp_FD16
        DRESendCANR_EPBSts_FD16: start-on-event=SendCANR_EPBSts_FD16, data=SendCANR_EPBSts_FD16.SendCANR_EPBSts_FD16
        DRESendCANR_ABSFailSts_FD16: start-on-event=SendCANR_ABSFailSts_FD16, data=SendCANR_ABSFailSts_FD16.SendCANR_ABSFailSts_FD16
        DRESendCANR_ESCFailSts: start-on-event=SendCANR_ESCFailSts, data=SendCANR_ESCFailSts.SendCANR_ESCFailSts
        DRESendCANR_N_PDU_7E_FD16: start-on-event=SendCANR_N_PDU_7E_FD16, data=SendCANR_N_PDU_7E_FD16.SendCANR_N_PDU_7E_FD16
        DRESendCANR_N_PDU_7F_FD16: start-on-event=SendCANR_N_PDU_7F_FD16, data=SendCANR_N_PDU_7F_FD16.SendCANR_N_PDU_7F_FD16
        DRESendCANR_N_PDU_81: start-on-event=SendCANR_N_PDU_81, data=SendCANR_N_PDU_81.SendCANR_N_PDU_81
        DRESendCANR_PerWakeUp_Diag_FD16: start-on-event=SendCANR_PerWakeUp_Diag_FD16, data=SendCANR_PerWakeUp_Diag_FD16.SendCANR_PerWakeUp_Diag_FD16
        DRESendCANR_WU_Timer_Value_FD16: start-on-event=SendCANR_WU_Timer_Value_FD16, data=SendCANR_WU_Timer_Value_FD16.SendCANR_WU_Timer_Value_FD16
        DRESendCANR_CRC_HYB_THRM_CMND_FD16: start-on-event=SendCANR_CRC_HYB_THRM_CMND_FD16, data=SendCANR_CRC_HYB_THRM_CMND_FD16.SendCANR_CRC_HYB_THRM_CMND_FD16
        DRESendCANR_EOPA_OIL_FlwRate_FD16: start-on-event=SendCANR_EOPA_OIL_FlwRate_FD16, data=SendCANR_EOPA_OIL_FlwRate_FD16.SendCANR_EOPA_OIL_FlwRate_FD16
        DRESendCANR_EOPA_OIL_TEMP_FD16: start-on-event=SendCANR_EOPA_OIL_TEMP_FD16, data=SendCANR_EOPA_OIL_TEMP_FD16.SendCANR_EOPA_OIL_TEMP_FD16
        DRESendCANR_EOPB_OIL_FlwRate_FD16: start-on-event=SendCANR_EOPB_OIL_FlwRate_FD16, data=SendCANR_EOPB_OIL_FlwRate_FD16.SendCANR_EOPB_OIL_FlwRate_FD16
        DRESendCANR_EOPB_OIL_TEMP_FD16: start-on-event=SendCANR_EOPB_OIL_TEMP_FD16, data=SendCANR_EOPB_OIL_TEMP_FD16.SendCANR_EOPB_OIL_TEMP_FD16
        DRESendCANR_MC_HYBD_THRM_CMND_FD16: start-on-event=SendCANR_MC_HYBD_THRM_CMND_FD16, data=SendCANR_MC_HYBD_THRM_CMND_FD16.SendCANR_MC_HYBD_THRM_CMND_FD16
        DRESendCANR_SGCP_OIL_FlwRate_FD16: start-on-event=SendCANR_SGCP_OIL_FlwRate_FD16, data=SendCANR_SGCP_OIL_FlwRate_FD16.SendCANR_SGCP_OIL_FlwRate_FD16
        DRESendCANR_SGCP_OIL_TEMP_FD16: start-on-event=SendCANR_SGCP_OIL_TEMP_FD16, data=SendCANR_SGCP_OIL_TEMP_FD16.SendCANR_SGCP_OIL_TEMP_FD16
        DRESendCANR_IMPACTCommand_FD16: start-on-event=SendCANR_IMPACTCommand_FD16, data=SendCANR_IMPACTCommand_FD16.SendCANR_IMPACTCommand_FD16
        DRESendCANR_IMPACTConfirm_FD16: start-on-event=SendCANR_IMPACTConfirm_FD16, data=SendCANR_IMPACTConfirm_FD16.SendCANR_IMPACTConfirm_FD16
        DRESendCANR_TotalOdometer_FD16: start-on-event=SendCANR_TotalOdometer_FD16, data=SendCANR_TotalOdometer_FD16.SendCANR_TotalOdometer_FD16
        DRESendCANR_Real_Time_Clock_FD16: start-on-event=SendCANR_Real_Time_Clock_FD16, data=SendCANR_Real_Time_Clock_FD16.SendCANR_Real_Time_Clock_FD16
        DRESendCANR_Real_Time_Valdity_FD16: start-on-event=SendCANR_Real_Time_Valdity_FD16, data=SendCANR_Real_Time_Valdity_FD16.SendCANR_Real_Time_Valdity_FD16
        DRESendCANR_GPS_Date_Day_FD16: start-on-event=SendCANR_GPS_Date_Day_FD16, data=SendCANR_GPS_Date_Day_FD16.SendCANR_GPS_Date_Day_FD16
        DRESendCANR_GPS_Date_Month_FD16: start-on-event=SendCANR_GPS_Date_Month_FD16, data=SendCANR_GPS_Date_Month_FD16.SendCANR_GPS_Date_Month_FD16
        DRESendCANR_GPS_Date_Year_FD16: start-on-event=SendCANR_GPS_Date_Year_FD16, data=SendCANR_GPS_Date_Year_FD16.SendCANR_GPS_Date_Year_FD16
        DRESendCANR_GPS_UTC_Hour_FD16: start-on-event=SendCANR_GPS_UTC_Hour_FD16, data=SendCANR_GPS_UTC_Hour_FD16.SendCANR_GPS_UTC_Hour_FD16
        DRESendCANR_GPS_UTC_Minute_FD16: start-on-event=SendCANR_GPS_UTC_Minute_FD16, data=SendCANR_GPS_UTC_Minute_FD16.SendCANR_GPS_UTC_Minute_FD16
        DRESendCANR_GPS_UTC_Second_FD16: start-on-event=SendCANR_GPS_UTC_Second_FD16, data=SendCANR_GPS_UTC_Second_FD16.SendCANR_GPS_UTC_Second_FD16
        DRESendCANR_T4_Sensor_Temp_FD16: start-on-event=SendCANR_T4_Sensor_Temp_FD16, data=SendCANR_T4_Sensor_Temp_FD16.SendCANR_T4_Sensor_Temp_FD16
        DRESendCANR_T7_CoolntTmpVldty_FD16: start-on-event=SendCANR_T7_CoolntTmpVldty_FD16, data=SendCANR_T7_CoolntTmpVldty_FD16.SendCANR_T7_CoolntTmpVldty_FD16
        DRESendCANR_T7_Sensor_Temp_FD16: start-on-event=SendCANR_T7_Sensor_Temp_FD16, data=SendCANR_T7_Sensor_Temp_FD16.SendCANR_T7_Sensor_Temp_FD16
        DRESendCANR_RELSD_TgtTrq_FD16: start-on-event=SendCANR_RELSD_TgtTrq_FD16, data=SendCANR_RELSD_TgtTrq_FD16.SendCANR_RELSD_TgtTrq_FD16
        DRESendCANR_VIN_DATA_FD16: start-on-event=SendCANR_VIN_DATA_FD16, data=SendCANR_VIN_DATA_FD16.SendCANR_VIN_DATA_FD16
        DRESendCANR_VIN_MSG_FD16: start-on-event=SendCANR_VIN_MSG_FD16, data=SendCANR_VIN_MSG_FD16.SendCANR_VIN_MSG_FD16
      131 x runnable:
        ApplCanComAb_FD16Inin: symbol=ApplCanComAb_FD16_ApplCanComAb_FD16Inin  # CAN SWC initialization runnable
          data-send-points:
            40 x access:
              DSP_VeRxPDU_SGCP_PROPULSION_FD16_E2E_Sts_E2ECheckSts: accessed-variable=VeRxPDU_SGCP_PROPULSION_FD16_E2E_Sts.E2ECheckSts
              DSP_VeRxPDU_SGCP_PROPULSION_FD16_E2E_Sts_OpRetVal: accessed-variable=VeRxPDU_SGCP_PROPULSION_FD16_E2E_Sts.OpRetVal
              DSP_VeRxPDU_SGCP_OBD_DTC_FD16_E2E_Sts_E2ECheckSts: accessed-variable=VeRxPDU_SGCP_OBD_DTC_FD16_E2E_Sts.E2ECheckSts
              DSP_VeRxPDU_SGCP_OBD_DTC_FD16_E2E_Sts_OpRetVal: accessed-variable=VeRxPDU_SGCP_OBD_DTC_FD16_E2E_Sts.OpRetVal
              DSP_VeRxPDU_PARK_DATA_FD16_E2E_Sts_E2ECheckSts: accessed-variable=VeRxPDU_PARK_DATA_FD16_E2E_Sts.E2ECheckSts
              DSP_VeRxPDU_PARK_DATA_FD16_E2E_Sts_OpRetVal: accessed-variable=VeRxPDU_PARK_DATA_FD16_E2E_Sts.OpRetVal
              DSP_VeRxPDU_OBD_CONTENT_FRAME_FD16_E2E_Sts_E2ECheckSts: accessed-variable=VeRxPDU_OBD_CONTENT_FRAME_FD16_E2E_Sts.E2ECheckSts
              DSP_VeRxPDU_OBD_CONTENT_FRAME_FD16_E2E_Sts_OpRetVal: accessed-variable=VeRxPDU_OBD_CONTENT_FRAME_FD16_E2E_Sts.OpRetVal
              DSP_VeRxPDU_MCPB_PROPULSION_FD16_E2E_Sts_E2ECheckSts: accessed-variable=VeRxPDU_MCPB_PROPULSION_FD16_E2E_Sts.E2ECheckSts
              DSP_VeRxPDU_MCPB_PROPULSION_FD16_E2E_Sts_OpRetVal: accessed-variable=VeRxPDU_MCPB_PROPULSION_FD16_E2E_Sts.OpRetVal
              DSP_VeRxPDU_MCPB_OBD_DTC_FD16_E2E_Sts_E2ECheckSts: accessed-variable=VeRxPDU_MCPB_OBD_DTC_FD16_E2E_Sts.E2ECheckSts
              DSP_VeRxPDU_MCPB_OBD_DTC_FD16_E2E_Sts_OpRetVal: accessed-variable=VeRxPDU_MCPB_OBD_DTC_FD16_E2E_Sts.OpRetVal
              DSP_VeRxPDU_MCPA_PROPULSION_FD16_E2E_Sts_E2ECheckSts: accessed-variable=VeRxPDU_MCPA_PROPULSION_FD16_E2E_Sts.E2ECheckSts
              DSP_VeRxPDU_MCPA_PROPULSION_FD16_E2E_Sts_OpRetVal: accessed-variable=VeRxPDU_MCPA_PROPULSION_FD16_E2E_Sts.OpRetVal
              DSP_VeRxPDU_MCPA_OBD_DTC_FD16_E2E_Sts_E2ECheckSts: accessed-variable=VeRxPDU_MCPA_OBD_DTC_FD16_E2E_Sts.E2ECheckSts
              DSP_VeRxPDU_MCPA_OBD_DTC_FD16_E2E_Sts_OpRetVal: accessed-variable=VeRxPDU_MCPA_OBD_DTC_FD16_E2E_Sts.OpRetVal
              DSP_VeRxPDU_ENGINE_HYBD_FD_4_FD16_E2E_Sts_E2ECheckSts: accessed-variable=VeRxPDU_ENGINE_HYBD_FD_4_FD16_E2E_Sts.E2ECheckSts
              DSP_VeRxPDU_ENGINE_HYBD_FD_4_FD16_E2E_Sts_OpRetVal: accessed-variable=VeRxPDU_ENGINE_HYBD_FD_4_FD16_E2E_Sts.OpRetVal
              DSP_VeRxPDU_ENGINE_HYBD_FD_3_FD16_E2E_Sts_E2ECheckSts: accessed-variable=VeRxPDU_ENGINE_HYBD_FD_3_FD16_E2E_Sts.E2ECheckSts
              DSP_VeRxPDU_ENGINE_HYBD_FD_3_FD16_E2E_Sts_OpRetVal: accessed-variable=VeRxPDU_ENGINE_HYBD_FD_3_FD16_E2E_Sts.OpRetVal
              DSP_VeRxPDU_ENGINE_HYBD_FD_1_FD16_E2E_Sts_E2ECheckSts: accessed-variable=VeRxPDU_ENGINE_HYBD_FD_1_FD16_E2E_Sts.E2ECheckSts
              DSP_VeRxPDU_ENGINE_HYBD_FD_1_FD16_E2E_Sts_OpRetVal: accessed-variable=VeRxPDU_ENGINE_HYBD_FD_1_FD16_E2E_Sts.OpRetVal
              DSP_VeRxPDU_ENGINE_FD_8_FD16_E2E_Sts_E2ECheckSts: accessed-variable=VeRxPDU_ENGINE_FD_8_FD16_E2E_Sts.E2ECheckSts
              DSP_VeRxPDU_ENGINE_FD_8_FD16_E2E_Sts_OpRetVal: accessed-variable=VeRxPDU_ENGINE_FD_8_FD16_E2E_Sts.OpRetVal
              DSP_VeRxPDU_ENGINE_FD_7_FD16_E2E_Sts_E2ECheckSts: accessed-variable=VeRxPDU_ENGINE_FD_7_FD16_E2E_Sts.E2ECheckSts
              DSP_VeRxPDU_ENGINE_FD_7_FD16_E2E_Sts_OpRetVal: accessed-variable=VeRxPDU_ENGINE_FD_7_FD16_E2E_Sts.OpRetVal
              DSP_VeRxPDU_ENGINE_FD_6_FD16_E2E_Sts_E2ECheckSts: accessed-variable=VeRxPDU_ENGINE_FD_6_FD16_E2E_Sts.E2ECheckSts
              DSP_VeRxPDU_ENGINE_FD_6_FD16_E2E_Sts_OpRetVal: accessed-variable=VeRxPDU_ENGINE_FD_6_FD16_E2E_Sts.OpRetVal
              DSP_VeRxPDU_ENGINE_FD_5_FD16_E2E_Sts_E2ECheckSts: accessed-variable=VeRxPDU_ENGINE_FD_5_FD16_E2E_Sts.E2ECheckSts
              DSP_VeRxPDU_ENGINE_FD_5_FD16_E2E_Sts_OpRetVal: accessed-variable=VeRxPDU_ENGINE_FD_5_FD16_E2E_Sts.OpRetVal
              DSP_VeRxPDU_ENGINE_FD_3_FD16_E2E_Sts_E2ECheckSts: accessed-variable=VeRxPDU_ENGINE_FD_3_FD16_E2E_Sts.E2ECheckSts
              DSP_VeRxPDU_ENGINE_FD_3_FD16_E2E_Sts_OpRetVal: accessed-variable=VeRxPDU_ENGINE_FD_3_FD16_E2E_Sts.OpRetVal
              DSP_VeRxPDU_ENGINE_FD_2_FD16_E2E_Sts_E2ECheckSts: accessed-variable=VeRxPDU_ENGINE_FD_2_FD16_E2E_Sts.E2ECheckSts
              DSP_VeRxPDU_ENGINE_FD_2_FD16_E2E_Sts_OpRetVal: accessed-variable=VeRxPDU_ENGINE_FD_2_FD16_E2E_Sts.OpRetVal
              DSP_VeRxPDU_ENGINE_FD_1_FD16_E2E_Sts_E2ECheckSts: accessed-variable=VeRxPDU_ENGINE_FD_1_FD16_E2E_Sts.E2ECheckSts
              DSP_VeRxPDU_ENGINE_FD_1_FD16_E2E_Sts_OpRetVal: accessed-variable=VeRxPDU_ENGINE_FD_1_FD16_E2E_Sts.OpRetVal
              DSP_VeRxPDU_ELSDM_FD_1_FD16_E2E_Sts_E2ECheckSts: accessed-variable=VeRxPDU_ELSDM_FD_1_FD16_E2E_Sts.E2ECheckSts
              DSP_VeRxPDU_ELSDM_FD_1_FD16_E2E_Sts_OpRetVal: accessed-variable=VeRxPDU_ELSDM_FD_1_FD16_E2E_Sts.OpRetVal
              DSP_VeRxPDU_AGSM_FD_2_FD16_E2E_Sts_E2ECheckSts: accessed-variable=VeRxPDU_AGSM_FD_2_FD16_E2E_Sts.E2ECheckSts
              DSP_VeRxPDU_AGSM_FD_2_FD16_E2E_Sts_OpRetVal: accessed-variable=VeRxPDU_AGSM_FD_2_FD16_E2E_Sts.OpRetVal
          27 x parameter access:
            SCPVA_KeCANR_b_ComTxMsg_BCM_FD_10_FD16_Enbld: accessed-parameter=KeCANR_b_ComTxMsg_BCM_FD_10_FD16_Enbld
            SCPVA_KeCANR_b_ComTxMsg_BCM_FD_2_FD16_Enbld: accessed-parameter=KeCANR_b_ComTxMsg_BCM_FD_2_FD16_Enbld
            SCPVA_KeCANR_b_ComTxMsg_BCM_FD_9_FD16_Enbld: accessed-parameter=KeCANR_b_ComTxMsg_BCM_FD_9_FD16_Enbld
            SCPVA_KeCANR_b_ComTxMsg_BRAKE_FD_2_FD16_Enbld: accessed-parameter=KeCANR_b_ComTxMsg_BRAKE_FD_2_FD16_Enbld
            SCPVA_KeCANR_b_ComTxMsg_BRAKE_FD_4_FD16_Enbld: accessed-parameter=KeCANR_b_ComTxMsg_BRAKE_FD_4_FD16_Enbld
            SCPVA_KeCANR_b_ComTxMsg_BRAKE_FD_5_FD16_Enbld: accessed-parameter=KeCANR_b_ComTxMsg_BRAKE_FD_5_FD16_Enbld
            SCPVA_KeCANR_b_ComTxMsg_GLIWA_MCPA_RX_FD16_Enbld: accessed-parameter=KeCANR_b_ComTxMsg_GLIWA_MCPA_RX_FD16_Enbld
            SCPVA_KeCANR_b_ComTxMsg_GLIWA_MCPB_RX_FD16_Enbld: accessed-parameter=KeCANR_b_ComTxMsg_GLIWA_MCPB_RX_FD16_Enbld
            SCPVA_KeCANR_b_ComTxMsg_GLIWA_SGCP_RX_FD16_Enbld: accessed-parameter=KeCANR_b_ComTxMsg_GLIWA_SGCP_RX_FD16_Enbld
            SCPVA_KeCANR_b_ComTxMsg_HYBRID_POWERTRAIN1_FD16_Enbld: accessed-parameter=KeCANR_b_ComTxMsg_HYBRID_POWERTRAIN1_FD16_Enbld
            SCPVA_KeCANR_b_ComTxMsg_HYBRID_POWERTRAIN2_FD16_Enbld: accessed-parameter=KeCANR_b_ComTxMsg_HYBRID_POWERTRAIN2_FD16_Enbld
            SCPVA_KeCANR_b_ComTxMsg_HYBRID_POWERTRAIN5_FD16_Enbld: accessed-parameter=KeCANR_b_ComTxMsg_HYBRID_POWERTRAIN5_FD16_Enbld
            SCPVA_KeCANR_b_ComTxMsg_HYBRID_SYSTEM_EPT1_FD16_Enbld: accessed-parameter=KeCANR_b_ComTxMsg_HYBRID_SYSTEM_EPT1_FD16_Enbld
            SCPVA_KeCANR_b_ComTxMsg_HYBRID_THERMAL_COMMAND_FD16_Enbld: accessed-parameter=KeCANR_b_ComTxMsg_HYBRID_THERMAL_COMMAND_FD16_Enbld
            SCPVA_KeCANR_b_ComTxMsg_IMPACT_INFO_FD16_Enbld: accessed-parameter=KeCANR_b_ComTxMsg_IMPACT_INFO_FD16_Enbld
            SCPVA_KeCANR_b_ComTxMsg_INVTARGET_PROPULSION1_FD16_Enbld: accessed-parameter=KeCANR_b_ComTxMsg_INVTARGET_PROPULSION1_FD16_Enbld
            SCPVA_KeCANR_b_ComTxMsg_INVTARGET_PROPULSION2_FD16_Enbld: accessed-parameter=KeCANR_b_ComTxMsg_INVTARGET_PROPULSION2_FD16_Enbld
            SCPVA_KeCANR_b_ComTxMsg_IPC_FD_1_FD16_Enbld: accessed-parameter=KeCANR_b_ComTxMsg_IPC_FD_1_FD16_Enbld
            SCPVA_KeCANR_b_ComTxMsg_PT_ENERGY_FD_1_FD16_Enbld: accessed-parameter=KeCANR_b_ComTxMsg_PT_ENERGY_FD_1_FD16_Enbld
            SCPVA_KeCANR_b_ComTxMsg_PT_SYSTEM_FD_1_FD16_Enbld: accessed-parameter=KeCANR_b_ComTxMsg_PT_SYSTEM_FD_1_FD16_Enbld
            SCPVA_KeCANR_b_ComTxMsg_PT_TORQUE_FD_1_FD16_Enbld: accessed-parameter=KeCANR_b_ComTxMsg_PT_TORQUE_FD_1_FD16_Enbld
            SCPVA_KeCANR_b_ComTxMsg_REAL_TIME_CLOCK_FD16_Enbld: accessed-parameter=KeCANR_b_ComTxMsg_REAL_TIME_CLOCK_FD16_Enbld
            SCPVA_KeCANR_b_ComTxMsg_TELEMATIC_FD_1_FD16_Enbld: accessed-parameter=KeCANR_b_ComTxMsg_TELEMATIC_FD_1_FD16_Enbld
            SCPVA_KeCANR_b_ComTxMsg_VDCM_PWT3_FD16_Enbld: accessed-parameter=KeCANR_b_ComTxMsg_VDCM_PWT3_FD16_Enbld
            SCPVA_KeCANR_b_ComTxMsg_VEHDYN_FD_1_FD16_Enbld: accessed-parameter=KeCANR_b_ComTxMsg_VEHDYN_FD_1_FD16_Enbld
            SCPVA_KeCANR_b_ComTxMsg_VIN_FD16_Enbld: accessed-parameter=KeCANR_b_ComTxMsg_VIN_FD16_Enbld
            SCPVA_KeCANR_b_ComTxMsg_CFG_DATA_CODE_REQUEST_FD16_Enbld: accessed-parameter=KeCANR_b_ComTxMsg_CFG_DATA_CODE_REQUEST_FD16_Enbld
        COMRX_N_PDU_7B_GLIWA_MCPA_TX_FD16_Received: symbol=ApplCanComAb_FD16_COMRX_N_PDU_7B_GLIWA_MCPA_TX_FD16_Received  # Received
          data-receive-point-by-arguments:
            access DRP_CanCom_FD16RxSignalsSR_COMRX_N_PDU_7B_GLIWA_MCPA_TX_FD16: accessed-variable=CanCom_FD16RxSignalsSR.COMRX_N_PDU_7B_GLIWA_MCPA_TX_FD16
          data-send-points:
            access DSP_VeCANR_cmp_N_PDU_7B_FD16_VeCANR_cmp_N_PDU_7B_FD16: accessed-variable=VeCANR_cmp_N_PDU_7B_FD16.VeCANR_cmp_N_PDU_7B_FD16
            access DSP_VeCANR_b_N_PDU_7B_FD16TO_VeCANR_b_N_PDU_7B_FD16TO: accessed-variable=VeCANR_b_N_PDU_7B_FD16TO.VeCANR_b_N_PDU_7B_FD16TO
        COMRX_N_PDU_7B_GLIWA_MCPA_TX_FD16_Error: symbol=ApplCanComAb_FD16_COMRX_N_PDU_7B_GLIWA_MCPA_TX_FD16_Error  # Error
          data-receive-point-by-arguments:
            access DRP_CanCom_FD16RxSignalsSR_COMRX_N_PDU_7B_GLIWA_MCPA_TX_FD16: accessed-variable=CanCom_FD16RxSignalsSR.COMRX_N_PDU_7B_GLIWA_MCPA_TX_FD16
          data-send-points:
            access DSP_VeCANR_cmp_N_PDU_7B_FD16_VeCANR_cmp_N_PDU_7B_FD16: accessed-variable=VeCANR_cmp_N_PDU_7B_FD16.VeCANR_cmp_N_PDU_7B_FD16
            access DSP_VeCANR_b_N_PDU_7B_FD16TO_VeCANR_b_N_PDU_7B_FD16TO: accessed-variable=VeCANR_b_N_PDU_7B_FD16TO.VeCANR_b_N_PDU_7B_FD16TO
        COMRX_N_PDU_7C_GLIWA_MCPB_TX_FD16_Received: symbol=ApplCanComAb_FD16_COMRX_N_PDU_7C_GLIWA_MCPB_TX_FD16_Received  # Received
          data-receive-point-by-arguments:
            access DRP_CanCom_FD16RxSignalsSR_COMRX_N_PDU_7C_GLIWA_MCPB_TX_FD16: accessed-variable=CanCom_FD16RxSignalsSR.COMRX_N_PDU_7C_GLIWA_MCPB_TX_FD16
          data-send-points:
            access DSP_VeCANR_cmp_N_PDU_7C_FD16_VeCANR_cmp_N_PDU_7C_FD16: accessed-variable=VeCANR_cmp_N_PDU_7C_FD16.VeCANR_cmp_N_PDU_7C_FD16
            access DSP_VeCANR_b_N_PDU_7C_FD16TO_VeCANR_b_N_PDU_7C_FD16TO: accessed-variable=VeCANR_b_N_PDU_7C_FD16TO.VeCANR_b_N_PDU_7C_FD16TO
        COMRX_N_PDU_7C_GLIWA_MCPB_TX_FD16_Error: symbol=ApplCanComAb_FD16_COMRX_N_PDU_7C_GLIWA_MCPB_TX_FD16_Error  # Error
          data-receive-point-by-arguments:
            access DRP_CanCom_FD16RxSignalsSR_COMRX_N_PDU_7C_GLIWA_MCPB_TX_FD16: accessed-variable=CanCom_FD16RxSignalsSR.COMRX_N_PDU_7C_GLIWA_MCPB_TX_FD16
          data-send-points:
            access DSP_VeCANR_cmp_N_PDU_7C_FD16_VeCANR_cmp_N_PDU_7C_FD16: accessed-variable=VeCANR_cmp_N_PDU_7C_FD16.VeCANR_cmp_N_PDU_7C_FD16
            access DSP_VeCANR_b_N_PDU_7C_FD16TO_VeCANR_b_N_PDU_7C_FD16TO: accessed-variable=VeCANR_b_N_PDU_7C_FD16TO.VeCANR_b_N_PDU_7C_FD16TO
        COMRX_N_PDU_86_GLIWA_SGCP_TX_FD16_Received: symbol=ApplCanComAb_FD16_COMRX_N_PDU_86_GLIWA_SGCP_TX_FD16_Received  # Received
          data-receive-point-by-arguments:
            access DRP_CanCom_FD16RxSignalsSR_COMRX_N_PDU_86_GLIWA_SGCP_TX_FD16: accessed-variable=CanCom_FD16RxSignalsSR.COMRX_N_PDU_86_GLIWA_SGCP_TX_FD16
          data-send-points:
            access DSP_VeCANR_cmp_N_PDU_86_FD16_VeCANR_cmp_N_PDU_86_FD16: accessed-variable=VeCANR_cmp_N_PDU_86_FD16.VeCANR_cmp_N_PDU_86_FD16
            access DSP_VeCANR_b_N_PDU_86_FD16TO_VeCANR_b_N_PDU_86_FD16TO: accessed-variable=VeCANR_b_N_PDU_86_FD16TO.VeCANR_b_N_PDU_86_FD16TO
        COMRX_N_PDU_86_GLIWA_SGCP_TX_FD16_Error: symbol=ApplCanComAb_FD16_COMRX_N_PDU_86_GLIWA_SGCP_TX_FD16_Error  # Error
          data-receive-point-by-arguments:
            access DRP_CanCom_FD16RxSignalsSR_COMRX_N_PDU_86_GLIWA_SGCP_TX_FD16: accessed-variable=CanCom_FD16RxSignalsSR.COMRX_N_PDU_86_GLIWA_SGCP_TX_FD16
          data-send-points:
            access DSP_VeCANR_cmp_N_PDU_86_FD16_VeCANR_cmp_N_PDU_86_FD16: accessed-variable=VeCANR_cmp_N_PDU_86_FD16.VeCANR_cmp_N_PDU_86_FD16
            access DSP_VeCANR_b_N_PDU_86_FD16TO_VeCANR_b_N_PDU_86_FD16TO: accessed-variable=VeCANR_b_N_PDU_86_FD16TO.VeCANR_b_N_PDU_86_FD16TO
        COMRX_CLrDiagInfo_MCPA_P_MCPA_STATUS_FD16_Received: symbol=ApplCanComAb_FD16_COMRX_CLrDiagInfo_MCPA_P_MCPA_STATUS_FD16_Received  # Received
          data-receive-point-by-arguments:
            access DRP_CanCom_FD16RxSignalsSR_COMRX_CLrDiagInfo_MCPA_P_MCPA_STATUS_FD16: accessed-variable=CanCom_FD16RxSignalsSR.COMRX_CLrDiagInfo_MCPA_P_MCPA_STATUS_FD16
          data-send-points:
            access DSP_VeCANR_b_CLrDiagInfoMCPA_P_FD16_VeCANR_b_CLrDiagInfoMCPA_P_FD16: accessed-variable=VeCANR_b_CLrDiagInfoMCPA_P_FD16.VeCANR_b_CLrDiagInfoMCPA_P_FD16
            access DSP_VeCANR_b_CLrDiagInfoMCPA_P_FD16TO_VeCANR_b_CLrDiagInfoMCPA_P_FD16TO: accessed-variable=VeCANR_b_CLrDiagInfoMCPA_P_FD16TO.VeCANR_b_CLrDiagInfoMCPA_P_FD16TO
        COMRX_CLrDiagInfo_MCPA_P_MCPA_STATUS_FD16_Error: symbol=ApplCanComAb_FD16_COMRX_CLrDiagInfo_MCPA_P_MCPA_STATUS_FD16_Error  # Error
          data-receive-point-by-arguments:
            access DRP_CanCom_FD16RxSignalsSR_COMRX_CLrDiagInfo_MCPA_P_MCPA_STATUS_FD16: accessed-variable=CanCom_FD16RxSignalsSR.COMRX_CLrDiagInfo_MCPA_P_MCPA_STATUS_FD16
          data-send-points:
            access DSP_VeCANR_b_CLrDiagInfoMCPA_P_FD16_VeCANR_b_CLrDiagInfoMCPA_P_FD16: accessed-variable=VeCANR_b_CLrDiagInfoMCPA_P_FD16.VeCANR_b_CLrDiagInfoMCPA_P_FD16
            access DSP_VeCANR_b_CLrDiagInfoMCPA_P_FD16TO_VeCANR_b_CLrDiagInfoMCPA_P_FD16TO: accessed-variable=VeCANR_b_CLrDiagInfoMCPA_P_FD16TO.VeCANR_b_CLrDiagInfoMCPA_P_FD16TO
        COMRX_CRC_MCPA_STATUS_MCPA_STATUS_FD16_Received: symbol=ApplCanComAb_FD16_COMRX_CRC_MCPA_STATUS_MCPA_STATUS_FD16_Received  # Received
          data-receive-point-by-arguments:
            access DRP_CanCom_FD16RxSignalsSR_COMRX_CRC_MCPA_STATUS_MCPA_STATUS_FD16: accessed-variable=CanCom_FD16RxSignalsSR.COMRX_CRC_MCPA_STATUS_MCPA_STATUS_FD16
          data-send-points:
            access DSP_VeCANR_y_CRC_MCPA_STATUS_FD16_VeCANR_y_CRC_MCPA_STATUS_FD16: accessed-variable=VeCANR_y_CRC_MCPA_STATUS_FD16.VeCANR_y_CRC_MCPA_STATUS_FD16
            access DSP_VeCANR_b_CRC_MCPA_STATUS_FD16TO_VeCANR_b_CRC_MCPA_STATUS_FD16TO: accessed-variable=VeCANR_b_CRC_MCPA_STATUS_FD16TO.VeCANR_b_CRC_MCPA_STATUS_FD16TO
        COMRX_CRC_MCPA_STATUS_MCPA_STATUS_FD16_Error: symbol=ApplCanComAb_FD16_COMRX_CRC_MCPA_STATUS_MCPA_STATUS_FD16_Error  # Error
          data-receive-point-by-arguments:
            access DRP_CanCom_FD16RxSignalsSR_COMRX_CRC_MCPA_STATUS_MCPA_STATUS_FD16: accessed-variable=CanCom_FD16RxSignalsSR.COMRX_CRC_MCPA_STATUS_MCPA_STATUS_FD16
          data-send-points:
            access DSP_VeCANR_y_CRC_MCPA_STATUS_FD16_VeCANR_y_CRC_MCPA_STATUS_FD16: accessed-variable=VeCANR_y_CRC_MCPA_STATUS_FD16.VeCANR_y_CRC_MCPA_STATUS_FD16
            access DSP_VeCANR_b_CRC_MCPA_STATUS_FD16TO_VeCANR_b_CRC_MCPA_STATUS_FD16TO: accessed-variable=VeCANR_b_CRC_MCPA_STATUS_FD16TO.VeCANR_b_CRC_MCPA_STATUS_FD16TO
        COMRX_MC_MCPA_STATUS_MCPA_STATUS_FD16_Received: symbol=ApplCanComAb_FD16_COMRX_MC_MCPA_STATUS_MCPA_STATUS_FD16_Received  # Received
          data-receive-point-by-arguments:
            access DRP_CanCom_FD16RxSignalsSR_COMRX_MC_MCPA_STATUS_MCPA_STATUS_FD16: accessed-variable=CanCom_FD16RxSignalsSR.COMRX_MC_MCPA_STATUS_MCPA_STATUS_FD16
          data-send-points:
            access DSP_VeCANR_y_MC_MCPA_STATUS_FD16_VeCANR_y_MC_MCPA_STATUS_FD16: accessed-variable=VeCANR_y_MC_MCPA_STATUS_FD16.VeCANR_y_MC_MCPA_STATUS_FD16
            access DSP_VeCANR_b_MC_MCPA_STATUS_FD16TO_VeCANR_b_MC_MCPA_STATUS_FD16TO: accessed-variable=VeCANR_b_MC_MCPA_STATUS_FD16TO.VeCANR_b_MC_MCPA_STATUS_FD16TO
        COMRX_MC_MCPA_STATUS_MCPA_STATUS_FD16_Error: symbol=ApplCanComAb_FD16_COMRX_MC_MCPA_STATUS_MCPA_STATUS_FD16_Error  # Error
          data-receive-point-by-arguments:
            access DRP_CanCom_FD16RxSignalsSR_COMRX_MC_MCPA_STATUS_MCPA_STATUS_FD16: accessed-variable=CanCom_FD16RxSignalsSR.COMRX_MC_MCPA_STATUS_MCPA_STATUS_FD16
          data-send-points:
            access DSP_VeCANR_y_MC_MCPA_STATUS_FD16_VeCANR_y_MC_MCPA_STATUS_FD16: accessed-variable=VeCANR_y_MC_MCPA_STATUS_FD16.VeCANR_y_MC_MCPA_STATUS_FD16
            access DSP_VeCANR_b_MC_MCPA_STATUS_FD16TO_VeCANR_b_MC_MCPA_STATUS_FD16TO: accessed-variable=VeCANR_b_MC_MCPA_STATUS_FD16TO.VeCANR_b_MC_MCPA_STATUS_FD16TO
        COMRX_MCPA_Control_Board_Temperature_P_MCPA_STATUS_FD16_Received: symbol=ApplCanComAb_FD16_COMRX_MCPA_Control_Board_Temperature_P_MCPA_STATUS_FD16_Received  # Received
          data-receive-point-by-arguments:
            access DRP_CanCom_FD16RxSignalsSR_COMRX_MCPA_Control_Board_Temperature_P_MCPA_STATUS_FD16: accessed-variable=CanCom_FD16RxSignalsSR.COMRX_MCPA_Control_Board_Temperature_P_MCPA_STATUS_FD16
          data-send-points:
            access DSP_VeCANR_T_MCPACtrlBoarTempP_FD16_VeCANR_T_MCPACtrlBoarTempP_FD16: accessed-variable=VeCANR_T_MCPACtrlBoarTempP_FD16.VeCANR_T_MCPACtrlBoarTempP_FD16
            access DSP_VeCANR_b_MCPACtrlBoarTempP_FD16TO_VeCANR_b_MCPACtrlBoarTempP_FD16TO: accessed-variable=VeCANR_b_MCPACtrlBoarTempP_FD16TO.VeCANR_b_MCPACtrlBoarTempP_FD16TO
        COMRX_MCPA_Control_Board_Temperature_P_MCPA_STATUS_FD16_Error: symbol=ApplCanComAb_FD16_COMRX_MCPA_Control_Board_Temperature_P_MCPA_STATUS_FD16_Error  # Error
          data-receive-point-by-arguments:
            access DRP_CanCom_FD16RxSignalsSR_COMRX_MCPA_Control_Board_Temperature_P_MCPA_STATUS_FD16: accessed-variable=CanCom_FD16RxSignalsSR.COMRX_MCPA_Control_Board_Temperature_P_MCPA_STATUS_FD16
          data-send-points:
            access DSP_VeCANR_T_MCPACtrlBoarTempP_FD16_VeCANR_T_MCPACtrlBoarTempP_FD16: accessed-variable=VeCANR_T_MCPACtrlBoarTempP_FD16.VeCANR_T_MCPACtrlBoarTempP_FD16
            access DSP_VeCANR_b_MCPACtrlBoarTempP_FD16TO_VeCANR_b_MCPACtrlBoarTempP_FD16TO: accessed-variable=VeCANR_b_MCPACtrlBoarTempP_FD16TO.VeCANR_b_MCPACtrlBoarTempP_FD16TO
        COMRX_MCPA_CoolantTemp_P_MCPA_STATUS_FD16_Received: symbol=ApplCanComAb_FD16_COMRX_MCPA_CoolantTemp_P_MCPA_STATUS_FD16_Received  # Received
          data-receive-point-by-arguments:
            access DRP_CanCom_FD16RxSignalsSR_COMRX_MCPA_CoolantTemp_P_MCPA_STATUS_FD16: accessed-variable=CanCom_FD16RxSignalsSR.COMRX_MCPA_CoolantTemp_P_MCPA_STATUS_FD16
          data-send-points:
            access DSP_VeCANR_T_MCPA_ClantTmp_P_FD16_VeCANR_T_MCPA_ClantTmp_P_FD16: accessed-variable=VeCANR_T_MCPA_ClantTmp_P_FD16.VeCANR_T_MCPA_ClantTmp_P_FD16
            access DSP_VeCANR_b_MCPA_ClantTmp_P_FD16TO_VeCANR_b_MCPA_ClantTmp_P_FD16TO: accessed-variable=VeCANR_b_MCPA_ClantTmp_P_FD16TO.VeCANR_b_MCPA_ClantTmp_P_FD16TO
        COMRX_MCPA_CoolantTemp_P_MCPA_STATUS_FD16_Error: symbol=ApplCanComAb_FD16_COMRX_MCPA_CoolantTemp_P_MCPA_STATUS_FD16_Error  # Error
          data-receive-point-by-arguments:
            access DRP_CanCom_FD16RxSignalsSR_COMRX_MCPA_CoolantTemp_P_MCPA_STATUS_FD16: accessed-variable=CanCom_FD16RxSignalsSR.COMRX_MCPA_CoolantTemp_P_MCPA_STATUS_FD16
          data-send-points:
            access DSP_VeCANR_T_MCPA_ClantTmp_P_FD16_VeCANR_T_MCPA_ClantTmp_P_FD16: accessed-variable=VeCANR_T_MCPA_ClantTmp_P_FD16.VeCANR_T_MCPA_ClantTmp_P_FD16
            access DSP_VeCANR_b_MCPA_ClantTmp_P_FD16TO_VeCANR_b_MCPA_ClantTmp_P_FD16TO: accessed-variable=VeCANR_b_MCPA_ClantTmp_P_FD16TO.VeCANR_b_MCPA_ClantTmp_P_FD16TO
        COMRX_MCPA_DC_Current_P_MCPA_STATUS_FD16_Received: symbol=ApplCanComAb_FD16_COMRX_MCPA_DC_Current_P_MCPA_STATUS_FD16_Received  # Received
          data-receive-point-by-arguments:
            access DRP_CanCom_FD16RxSignalsSR_COMRX_MCPA_DC_Current_P_MCPA_STATUS_FD16: accessed-variable=CanCom_FD16RxSignalsSR.COMRX_MCPA_DC_Current_P_MCPA_STATUS_FD16
          data-send-points:
            access DSP_VeCANR_I_MCPA_DC_Current_P_FD16_VeCANR_I_MCPA_DC_Current_P_FD16: accessed-variable=VeCANR_I_MCPA_DC_Current_P_FD16.VeCANR_I_MCPA_DC_Current_P_FD16
            access DSP_VeCANR_b_MCPA_DC_Current_P_FD16TO_VeCANR_b_MCPA_DC_Current_P_FD16TO: accessed-variable=VeCANR_b_MCPA_DC_Current_P_FD16TO.VeCANR_b_MCPA_DC_Current_P_FD16TO
        COMRX_MCPA_DC_Current_P_MCPA_STATUS_FD16_Error: symbol=ApplCanComAb_FD16_COMRX_MCPA_DC_Current_P_MCPA_STATUS_FD16_Error  # Error
          data-receive-point-by-arguments:
            access DRP_CanCom_FD16RxSignalsSR_COMRX_MCPA_DC_Current_P_MCPA_STATUS_FD16: accessed-variable=CanCom_FD16RxSignalsSR.COMRX_MCPA_DC_Current_P_MCPA_STATUS_FD16
          data-send-points:
            access DSP_VeCANR_I_MCPA_DC_Current_P_FD16_VeCANR_I_MCPA_DC_Current_P_FD16: accessed-variable=VeCANR_I_MCPA_DC_Current_P_FD16.VeCANR_I_MCPA_DC_Current_P_FD16
            access DSP_VeCANR_b_MCPA_DC_Current_P_FD16TO_VeCANR_b_MCPA_DC_Current_P_FD16TO: accessed-variable=VeCANR_b_MCPA_DC_Current_P_FD16TO.VeCANR_b_MCPA_DC_Current_P_FD16TO
        COMRX_MCPA_DC_Current_V_P_MCPA_STATUS_FD16_Received: symbol=ApplCanComAb_FD16_COMRX_MCPA_DC_Current_V_P_MCPA_STATUS_FD16_Received  # Received
          data-receive-point-by-arguments:
            access DRP_CanCom_FD16RxSignalsSR_COMRX_MCPA_DC_Current_V_P_MCPA_STATUS_FD16: accessed-variable=CanCom_FD16RxSignalsSR.COMRX_MCPA_DC_Current_V_P_MCPA_STATUS_FD16
          data-send-points:
            access DSP_VeCANR_b_MCPA_DC_Crrnt_V_P_FD16_VeCANR_b_MCPA_DC_Crrnt_V_P_FD16: accessed-variable=VeCANR_b_MCPA_DC_Crrnt_V_P_FD16.VeCANR_b_MCPA_DC_Crrnt_V_P_FD16
            access DSP_VeCANR_b_MCPA_DC_Crrnt_V_P_FD16TO_VeCANR_b_MCPA_DC_Crrnt_V_P_FD16TO: accessed-variable=VeCANR_b_MCPA_DC_Crrnt_V_P_FD16TO.VeCANR_b_MCPA_DC_Crrnt_V_P_FD16TO
        COMRX_MCPA_DC_Current_V_P_MCPA_STATUS_FD16_Error: symbol=ApplCanComAb_FD16_COMRX_MCPA_DC_Current_V_P_MCPA_STATUS_FD16_Error  # Error
          data-receive-point-by-arguments:
            access DRP_CanCom_FD16RxSignalsSR_COMRX_MCPA_DC_Current_V_P_MCPA_STATUS_FD16: accessed-variable=CanCom_FD16RxSignalsSR.COMRX_MCPA_DC_Current_V_P_MCPA_STATUS_FD16
          data-send-points:
            access DSP_VeCANR_b_MCPA_DC_Crrnt_V_P_FD16_VeCANR_b_MCPA_DC_Crrnt_V_P_FD16: accessed-variable=VeCANR_b_MCPA_DC_Crrnt_V_P_FD16.VeCANR_b_MCPA_DC_Crrnt_V_P_FD16
            access DSP_VeCANR_b_MCPA_DC_Crrnt_V_P_FD16TO_VeCANR_b_MCPA_DC_Crrnt_V_P_FD16TO: accessed-variable=VeCANR_b_MCPA_DC_Crrnt_V_P_FD16TO.VeCANR_b_MCPA_DC_Crrnt_V_P_FD16TO
        COMRX_MCPA_DC_Volt_V_P_MCPA_STATUS_FD16_Received: symbol=ApplCanComAb_FD16_COMRX_MCPA_DC_Volt_V_P_MCPA_STATUS_FD16_Received  # Received
          data-receive-point-by-arguments:
            access DRP_CanCom_FD16RxSignalsSR_COMRX_MCPA_DC_Volt_V_P_MCPA_STATUS_FD16: accessed-variable=CanCom_FD16RxSignalsSR.COMRX_MCPA_DC_Volt_V_P_MCPA_STATUS_FD16
          data-send-points:
            access DSP_VeCANR_b_MCPA_DC_Volt_V_P_FD16_VeCANR_b_MCPA_DC_Volt_V_P_FD16: accessed-variable=VeCANR_b_MCPA_DC_Volt_V_P_FD16.VeCANR_b_MCPA_DC_Volt_V_P_FD16
            access DSP_VeCANR_b_MCPA_DC_Volt_V_P_FD16TO_VeCANR_b_MCPA_DC_Volt_V_P_FD16TO: accessed-variable=VeCANR_b_MCPA_DC_Volt_V_P_FD16TO.VeCANR_b_MCPA_DC_Volt_V_P_FD16TO
        COMRX_MCPA_DC_Volt_V_P_MCPA_STATUS_FD16_Error: symbol=ApplCanComAb_FD16_COMRX_MCPA_DC_Volt_V_P_MCPA_STATUS_FD16_Error  # Error
          data-receive-point-by-arguments:
            access DRP_CanCom_FD16RxSignalsSR_COMRX_MCPA_DC_Volt_V_P_MCPA_STATUS_FD16: accessed-variable=CanCom_FD16RxSignalsSR.COMRX_MCPA_DC_Volt_V_P_MCPA_STATUS_FD16
          data-send-points:
            access DSP_VeCANR_b_MCPA_DC_Volt_V_P_FD16_VeCANR_b_MCPA_DC_Volt_V_P_FD16: accessed-variable=VeCANR_b_MCPA_DC_Volt_V_P_FD16.VeCANR_b_MCPA_DC_Volt_V_P_FD16
            access DSP_VeCANR_b_MCPA_DC_Volt_V_P_FD16TO_VeCANR_b_MCPA_DC_Volt_V_P_FD16TO: accessed-variable=VeCANR_b_MCPA_DC_Volt_V_P_FD16TO.VeCANR_b_MCPA_DC_Volt_V_P_FD16TO
        COMRX_MCPA_DC_Voltage_P_MCPA_STATUS_FD16_Received: symbol=ApplCanComAb_FD16_COMRX_MCPA_DC_Voltage_P_MCPA_STATUS_FD16_Received  # Received
          data-receive-point-by-arguments:
            access DRP_CanCom_FD16RxSignalsSR_COMRX_MCPA_DC_Voltage_P_MCPA_STATUS_FD16: accessed-variable=CanCom_FD16RxSignalsSR.COMRX_MCPA_DC_Voltage_P_MCPA_STATUS_FD16
          data-send-points:
            access DSP_VeCANR_U_MCPA_DC_Voltage_P_FD16_VeCANR_U_MCPA_DC_Voltage_P_FD16: accessed-variable=VeCANR_U_MCPA_DC_Voltage_P_FD16.VeCANR_U_MCPA_DC_Voltage_P_FD16
            access DSP_VeCANR_b_MCPA_DC_Voltage_P_FD16TO_VeCANR_b_MCPA_DC_Voltage_P_FD16TO: accessed-variable=VeCANR_b_MCPA_DC_Voltage_P_FD16TO.VeCANR_b_MCPA_DC_Voltage_P_FD16TO
        COMRX_MCPA_DC_Voltage_P_MCPA_STATUS_FD16_Error: symbol=ApplCanComAb_FD16_COMRX_MCPA_DC_Voltage_P_MCPA_STATUS_FD16_Error  # Error
          data-receive-point-by-arguments:
            access DRP_CanCom_FD16RxSignalsSR_COMRX_MCPA_DC_Voltage_P_MCPA_STATUS_FD16: accessed-variable=CanCom_FD16RxSignalsSR.COMRX_MCPA_DC_Voltage_P_MCPA_STATUS_FD16
          data-send-points:
            access DSP_VeCANR_U_MCPA_DC_Voltage_P_FD16_VeCANR_U_MCPA_DC_Voltage_P_FD16: accessed-variable=VeCANR_U_MCPA_DC_Voltage_P_FD16.VeCANR_U_MCPA_DC_Voltage_P_FD16
            access DSP_VeCANR_b_MCPA_DC_Voltage_P_FD16TO_VeCANR_b_MCPA_DC_Voltage_P_FD16TO: accessed-variable=VeCANR_b_MCPA_DC_Voltage_P_FD16TO.VeCANR_b_MCPA_DC_Voltage_P_FD16TO
        COMRX_MCPA_DerateReason_P_MCPA_STATUS_FD16_Received: symbol=ApplCanComAb_FD16_COMRX_MCPA_DerateReason_P_MCPA_STATUS_FD16_Received  # Received
          data-receive-point-by-arguments:
            access DRP_CanCom_FD16RxSignalsSR_COMRX_MCPA_DerateReason_P_MCPA_STATUS_FD16: accessed-variable=CanCom_FD16RxSignalsSR.COMRX_MCPA_DerateReason_P_MCPA_STATUS_FD16
          data-send-points:
            access DSP_VeCANR_e_MCPA_DerateResn_P_FD16_VeCANR_e_MCPA_DerateResn_P_FD16: accessed-variable=VeCANR_e_MCPA_DerateResn_P_FD16.VeCANR_e_MCPA_DerateResn_P_FD16
            access DSP_VeCANR_b_MCPA_DerateResn_P_FD16TO_VeCANR_b_MCPA_DerateResn_P_FD16TO: accessed-variable=VeCANR_b_MCPA_DerateResn_P_FD16TO.VeCANR_b_MCPA_DerateResn_P_FD16TO
        COMRX_MCPA_DerateReason_P_MCPA_STATUS_FD16_Error: symbol=ApplCanComAb_FD16_COMRX_MCPA_DerateReason_P_MCPA_STATUS_FD16_Error  # Error
          data-receive-point-by-arguments:
            access DRP_CanCom_FD16RxSignalsSR_COMRX_MCPA_DerateReason_P_MCPA_STATUS_FD16: accessed-variable=CanCom_FD16RxSignalsSR.COMRX_MCPA_DerateReason_P_MCPA_STATUS_FD16
          data-send-points:
            access DSP_VeCANR_e_MCPA_DerateResn_P_FD16_VeCANR_e_MCPA_DerateResn_P_FD16: accessed-variable=VeCANR_e_MCPA_DerateResn_P_FD16.VeCANR_e_MCPA_DerateResn_P_FD16
            access DSP_VeCANR_b_MCPA_DerateResn_P_FD16TO_VeCANR_b_MCPA_DerateResn_P_FD16TO: accessed-variable=VeCANR_b_MCPA_DerateResn_P_FD16TO.VeCANR_b_MCPA_DerateResn_P_FD16TO
        COMRX_MCPA_Inverter_Temp_P_MCPA_STATUS_FD16_Received: symbol=ApplCanComAb_FD16_COMRX_MCPA_Inverter_Temp_P_MCPA_STATUS_FD16_Received  # Received
          data-receive-point-by-arguments:
            access DRP_CanCom_FD16RxSignalsSR_COMRX_MCPA_Inverter_Temp_P_MCPA_STATUS_FD16: accessed-variable=CanCom_FD16RxSignalsSR.COMRX_MCPA_Inverter_Temp_P_MCPA_STATUS_FD16
          data-send-points:
            access DSP_VeCANR_T_MCPA_InvertTemp_P_FD16_VeCANR_T_MCPA_InvertTemp_P_FD16: accessed-variable=VeCANR_T_MCPA_InvertTemp_P_FD16.VeCANR_T_MCPA_InvertTemp_P_FD16
            access DSP_VeCANR_b_MCPA_InvertTemp_P_FD16TO_VeCANR_b_MCPA_InvertTemp_P_FD16TO: accessed-variable=VeCANR_b_MCPA_InvertTemp_P_FD16TO.VeCANR_b_MCPA_InvertTemp_P_FD16TO
        COMRX_MCPA_Inverter_Temp_P_MCPA_STATUS_FD16_Error: symbol=ApplCanComAb_FD16_COMRX_MCPA_Inverter_Temp_P_MCPA_STATUS_FD16_Error  # Error
          data-receive-point-by-arguments:
            access DRP_CanCom_FD16RxSignalsSR_COMRX_MCPA_Inverter_Temp_P_MCPA_STATUS_FD16: accessed-variable=CanCom_FD16RxSignalsSR.COMRX_MCPA_Inverter_Temp_P_MCPA_STATUS_FD16
          data-send-points:
            access DSP_VeCANR_T_MCPA_InvertTemp_P_FD16_VeCANR_T_MCPA_InvertTemp_P_FD16: accessed-variable=VeCANR_T_MCPA_InvertTemp_P_FD16.VeCANR_T_MCPA_InvertTemp_P_FD16
            access DSP_VeCANR_b_MCPA_InvertTemp_P_FD16TO_VeCANR_b_MCPA_InvertTemp_P_FD16TO: accessed-variable=VeCANR_b_MCPA_InvertTemp_P_FD16TO.VeCANR_b_MCPA_InvertTemp_P_FD16TO
        COMRX_MCPA_PIM_DC_Side_Busbar_Temp_P_MCPA_STATUS_FD16_Received: symbol=ApplCanComAb_FD16_COMRX_MCPA_PIM_DC_Side_Busbar_Temp_P_MCPA_STATUS_FD16_Received  # Received
          data-receive-point-by-arguments:
            access DRP_CanCom_FD16RxSignalsSR_COMRX_MCPA_PIM_DC_Side_Busbar_Temp_P_MCPA_STATUS_FD16: accessed-variable=CanCom_FD16RxSignalsSR.COMRX_MCPA_PIM_DC_Side_Busbar_Temp_P_MCPA_STATUS_FD16
          data-send-points:
            access DSP_VeCANR_T_MCPAPIMDCSdBusTmpPFD16_VeCANR_T_MCPAPIMDCSdBusTmpPFD16: accessed-variable=VeCANR_T_MCPAPIMDCSdBusTmpPFD16.VeCANR_T_MCPAPIMDCSdBusTmpPFD16
            access DSP_VeCANR_b_MCPAPIMDCSdBusTmpPFD16TO_VeCANR_b_MCPAPIMDCSdBusTmpPFD16TO: accessed-variable=VeCANR_b_MCPAPIMDCSdBusTmpPFD16TO.VeCANR_b_MCPAPIMDCSdBusTmpPFD16TO
        COMRX_MCPA_PIM_DC_Side_Busbar_Temp_P_MCPA_STATUS_FD16_Error: symbol=ApplCanComAb_FD16_COMRX_MCPA_PIM_DC_Side_Busbar_Temp_P_MCPA_STATUS_FD16_Error  # Error
          data-receive-point-by-arguments:
            access DRP_CanCom_FD16RxSignalsSR_COMRX_MCPA_PIM_DC_Side_Busbar_Temp_P_MCPA_STATUS_FD16: accessed-variable=CanCom_FD16RxSignalsSR.COMRX_MCPA_PIM_DC_Side_Busbar_Temp_P_MCPA_STATUS_FD16
          data-send-points:
            access DSP_VeCANR_T_MCPAPIMDCSdBusTmpPFD16_VeCANR_T_MCPAPIMDCSdBusTmpPFD16: accessed-variable=VeCANR_T_MCPAPIMDCSdBusTmpPFD16.VeCANR_T_MCPAPIMDCSdBusTmpPFD16
            access DSP_VeCANR_b_MCPAPIMDCSdBusTmpPFD16TO_VeCANR_b_MCPAPIMDCSdBusTmpPFD16TO: accessed-variable=VeCANR_b_MCPAPIMDCSdBusTmpPFD16TO.VeCANR_b_MCPAPIMDCSdBusTmpPFD16TO
        COMRX_MCPA_Rotor_Temperature_P_MCPA_STATUS_FD16_Received: symbol=ApplCanComAb_FD16_COMRX_MCPA_Rotor_Temperature_P_MCPA_STATUS_FD16_Received  # Received
          data-receive-point-by-arguments:
            access DRP_CanCom_FD16RxSignalsSR_COMRX_MCPA_Rotor_Temperature_P_MCPA_STATUS_FD16: accessed-variable=CanCom_FD16RxSignalsSR.COMRX_MCPA_Rotor_Temperature_P_MCPA_STATUS_FD16
          data-send-points:
            access DSP_VeCANR_T_MCPARotorTemp_P_FD16_VeCANR_T_MCPARotorTemp_P_FD16: accessed-variable=VeCANR_T_MCPARotorTemp_P_FD16.VeCANR_T_MCPARotorTemp_P_FD16
            access DSP_VeCANR_b_MCPARotorTemp_P_FD16TO_VeCANR_b_MCPARotorTemp_P_FD16TO: accessed-variable=VeCANR_b_MCPARotorTemp_P_FD16TO.VeCANR_b_MCPARotorTemp_P_FD16TO
        COMRX_MCPA_Rotor_Temperature_P_MCPA_STATUS_FD16_Error: symbol=ApplCanComAb_FD16_COMRX_MCPA_Rotor_Temperature_P_MCPA_STATUS_FD16_Error  # Error
          data-receive-point-by-arguments:
            access DRP_CanCom_FD16RxSignalsSR_COMRX_MCPA_Rotor_Temperature_P_MCPA_STATUS_FD16: accessed-variable=CanCom_FD16RxSignalsSR.COMRX_MCPA_Rotor_Temperature_P_MCPA_STATUS_FD16
          data-send-points:
            access DSP_VeCANR_T_MCPARotorTemp_P_FD16_VeCANR_T_MCPARotorTemp_P_FD16: accessed-variable=VeCANR_T_MCPARotorTemp_P_FD16.VeCANR_T_MCPARotorTemp_P_FD16
            access DSP_VeCANR_b_MCPARotorTemp_P_FD16TO_VeCANR_b_MCPARotorTemp_P_FD16TO: accessed-variable=VeCANR_b_MCPARotorTemp_P_FD16TO.VeCANR_b_MCPARotorTemp_P_FD16TO
        COMRX_MCPA_Service_Lamp_Request_P_MCPA_STATUS_FD16_Received: symbol=ApplCanComAb_FD16_COMRX_MCPA_Service_Lamp_Request_P_MCPA_STATUS_FD16_Received  # Received
          data-receive-point-by-arguments:
            access DRP_CanCom_FD16RxSignalsSR_COMRX_MCPA_Service_Lamp_Request_P_MCPA_STATUS_FD16: accessed-variable=CanCom_FD16RxSignalsSR.COMRX_MCPA_Service_Lamp_Request_P_MCPA_STATUS_FD16
          data-send-points:
            access DSP_VeCANR_b_MCPAServLampReq_P_FD16_VeCANR_b_MCPAServLampReq_P_FD16: accessed-variable=VeCANR_b_MCPAServLampReq_P_FD16.VeCANR_b_MCPAServLampReq_P_FD16
            access DSP_VeCANR_b_MCPAServLampReq_P_FD16TO_VeCANR_b_MCPAServLampReq_P_FD16TO: accessed-variable=VeCANR_b_MCPAServLampReq_P_FD16TO.VeCANR_b_MCPAServLampReq_P_FD16TO
        COMRX_MCPA_Service_Lamp_Request_P_MCPA_STATUS_FD16_Error: symbol=ApplCanComAb_FD16_COMRX_MCPA_Service_Lamp_Request_P_MCPA_STATUS_FD16_Error  # Error
          data-receive-point-by-arguments:
            access DRP_CanCom_FD16RxSignalsSR_COMRX_MCPA_Service_Lamp_Request_P_MCPA_STATUS_FD16: accessed-variable=CanCom_FD16RxSignalsSR.COMRX_MCPA_Service_Lamp_Request_P_MCPA_STATUS_FD16
          data-send-points:
            access DSP_VeCANR_b_MCPAServLampReq_P_FD16_VeCANR_b_MCPAServLampReq_P_FD16: accessed-variable=VeCANR_b_MCPAServLampReq_P_FD16.VeCANR_b_MCPAServLampReq_P_FD16
            access DSP_VeCANR_b_MCPAServLampReq_P_FD16TO_VeCANR_b_MCPAServLampReq_P_FD16TO: accessed-variable=VeCANR_b_MCPAServLampReq_P_FD16TO.VeCANR_b_MCPAServLampReq_P_FD16TO
        COMRX_CLrDiagInfo_MCPB_P_MCPB_STATUS_FD16_Received: symbol=ApplCanComAb_FD16_COMRX_CLrDiagInfo_MCPB_P_MCPB_STATUS_FD16_Received  # Received
          data-receive-point-by-arguments:
            access DRP_CanCom_FD16RxSignalsSR_COMRX_CLrDiagInfo_MCPB_P_MCPB_STATUS_FD16: accessed-variable=CanCom_FD16RxSignalsSR.COMRX_CLrDiagInfo_MCPB_P_MCPB_STATUS_FD16
          data-send-points:
            access DSP_VeCANR_b_CLrDiagInfoMCPB_P_FD16_VeCANR_b_CLrDiagInfoMCPB_P_FD16: accessed-variable=VeCANR_b_CLrDiagInfoMCPB_P_FD16.VeCANR_b_CLrDiagInfoMCPB_P_FD16
            access DSP_VeCANR_b_CLrDiagInfoMCPB_P_FD16TO_VeCANR_b_CLrDiagInfoMCPB_P_FD16TO: accessed-variable=VeCANR_b_CLrDiagInfoMCPB_P_FD16TO.VeCANR_b_CLrDiagInfoMCPB_P_FD16TO
        COMRX_CLrDiagInfo_MCPB_P_MCPB_STATUS_FD16_Error: symbol=ApplCanComAb_FD16_COMRX_CLrDiagInfo_MCPB_P_MCPB_STATUS_FD16_Error  # Error
          data-receive-point-by-arguments:
            access DRP_CanCom_FD16RxSignalsSR_COMRX_CLrDiagInfo_MCPB_P_MCPB_STATUS_FD16: accessed-variable=CanCom_FD16RxSignalsSR.COMRX_CLrDiagInfo_MCPB_P_MCPB_STATUS_FD16
          data-send-points:
            access DSP_VeCANR_b_CLrDiagInfoMCPB_P_FD16_VeCANR_b_CLrDiagInfoMCPB_P_FD16: accessed-variable=VeCANR_b_CLrDiagInfoMCPB_P_FD16.VeCANR_b_CLrDiagInfoMCPB_P_FD16
            access DSP_VeCANR_b_CLrDiagInfoMCPB_P_FD16TO_VeCANR_b_CLrDiagInfoMCPB_P_FD16TO: accessed-variable=VeCANR_b_CLrDiagInfoMCPB_P_FD16TO.VeCANR_b_CLrDiagInfoMCPB_P_FD16TO
        COMRX_CRC_MCPB_STATUS_MCPB_STATUS_FD16_Received: symbol=ApplCanComAb_FD16_COMRX_CRC_MCPB_STATUS_MCPB_STATUS_FD16_Received  # Received
          data-receive-point-by-arguments:
            access DRP_CanCom_FD16RxSignalsSR_COMRX_CRC_MCPB_STATUS_MCPB_STATUS_FD16: accessed-variable=CanCom_FD16RxSignalsSR.COMRX_CRC_MCPB_STATUS_MCPB_STATUS_FD16
          data-send-points:
            access DSP_VeCANR_y_CRC_MCPB_STATUS_FD16_VeCANR_y_CRC_MCPB_STATUS_FD16: accessed-variable=VeCANR_y_CRC_MCPB_STATUS_FD16.VeCANR_y_CRC_MCPB_STATUS_FD16
            access DSP_VeCANR_b_CRC_MCPB_STATUS_FD16TO_VeCANR_b_CRC_MCPB_STATUS_FD16TO: accessed-variable=VeCANR_b_CRC_MCPB_STATUS_FD16TO.VeCANR_b_CRC_MCPB_STATUS_FD16TO
        COMRX_CRC_MCPB_STATUS_MCPB_STATUS_FD16_Error: symbol=ApplCanComAb_FD16_COMRX_CRC_MCPB_STATUS_MCPB_STATUS_FD16_Error  # Error
          data-receive-point-by-arguments:
            access DRP_CanCom_FD16RxSignalsSR_COMRX_CRC_MCPB_STATUS_MCPB_STATUS_FD16: accessed-variable=CanCom_FD16RxSignalsSR.COMRX_CRC_MCPB_STATUS_MCPB_STATUS_FD16
          data-send-points:
            access DSP_VeCANR_y_CRC_MCPB_STATUS_FD16_VeCANR_y_CRC_MCPB_STATUS_FD16: accessed-variable=VeCANR_y_CRC_MCPB_STATUS_FD16.VeCANR_y_CRC_MCPB_STATUS_FD16
            access DSP_VeCANR_b_CRC_MCPB_STATUS_FD16TO_VeCANR_b_CRC_MCPB_STATUS_FD16TO: accessed-variable=VeCANR_b_CRC_MCPB_STATUS_FD16TO.VeCANR_b_CRC_MCPB_STATUS_FD16TO
        COMRX_MC_MCPB_STATUS_MCPB_STATUS_FD16_Received: symbol=ApplCanComAb_FD16_COMRX_MC_MCPB_STATUS_MCPB_STATUS_FD16_Received  # Received
          data-receive-point-by-arguments:
            access DRP_CanCom_FD16RxSignalsSR_COMRX_MC_MCPB_STATUS_MCPB_STATUS_FD16: accessed-variable=CanCom_FD16RxSignalsSR.COMRX_MC_MCPB_STATUS_MCPB_STATUS_FD16
          data-send-points:
            access DSP_VeCANR_y_MC_MCPB_STATUS_FD16_VeCANR_y_MC_MCPB_STATUS_FD16: accessed-variable=VeCANR_y_MC_MCPB_STATUS_FD16.VeCANR_y_MC_MCPB_STATUS_FD16
            access DSP_VeCANR_b_MC_MCPB_STATUS_FD16TO_VeCANR_b_MC_MCPB_STATUS_FD16TO: accessed-variable=VeCANR_b_MC_MCPB_STATUS_FD16TO.VeCANR_b_MC_MCPB_STATUS_FD16TO
        COMRX_MC_MCPB_STATUS_MCPB_STATUS_FD16_Error: symbol=ApplCanComAb_FD16_COMRX_MC_MCPB_STATUS_MCPB_STATUS_FD16_Error  # Error
          data-receive-point-by-arguments:
            access DRP_CanCom_FD16RxSignalsSR_COMRX_MC_MCPB_STATUS_MCPB_STATUS_FD16: accessed-variable=CanCom_FD16RxSignalsSR.COMRX_MC_MCPB_STATUS_MCPB_STATUS_FD16
          data-send-points:
            access DSP_VeCANR_y_MC_MCPB_STATUS_FD16_VeCANR_y_MC_MCPB_STATUS_FD16: accessed-variable=VeCANR_y_MC_MCPB_STATUS_FD16.VeCANR_y_MC_MCPB_STATUS_FD16
            access DSP_VeCANR_b_MC_MCPB_STATUS_FD16TO_VeCANR_b_MC_MCPB_STATUS_FD16TO: accessed-variable=VeCANR_b_MC_MCPB_STATUS_FD16TO.VeCANR_b_MC_MCPB_STATUS_FD16TO
        COMRX_MCPB_Control_Board_Temperature_P_MCPB_STATUS_FD16_Received: symbol=ApplCanComAb_FD16_COMRX_MCPB_Control_Board_Temperature_P_MCPB_STATUS_FD16_Received  # Received
          data-receive-point-by-arguments:
            access DRP_CanCom_FD16RxSignalsSR_COMRX_MCPB_Control_Board_Temperature_P_MCPB_STATUS_FD16: accessed-variable=CanCom_FD16RxSignalsSR.COMRX_MCPB_Control_Board_Temperature_P_MCPB_STATUS_FD16
          data-send-points:
            access DSP_VeCANR_y_MCPBCtrlBoarTempP_FD16_VeCANR_y_MCPBCtrlBoarTempP_FD16: accessed-variable=VeCANR_y_MCPBCtrlBoarTempP_FD16.VeCANR_y_MCPBCtrlBoarTempP_FD16
            access DSP_VeCANR_b_MCPBCtrlBoarTempP_FD16TO_VeCANR_b_MCPBCtrlBoarTempP_FD16TO: accessed-variable=VeCANR_b_MCPBCtrlBoarTempP_FD16TO.VeCANR_b_MCPBCtrlBoarTempP_FD16TO
        COMRX_MCPB_Control_Board_Temperature_P_MCPB_STATUS_FD16_Error: symbol=ApplCanComAb_FD16_COMRX_MCPB_Control_Board_Temperature_P_MCPB_STATUS_FD16_Error  # Error
          data-receive-point-by-arguments:
            access DRP_CanCom_FD16RxSignalsSR_COMRX_MCPB_Control_Board_Temperature_P_MCPB_STATUS_FD16: accessed-variable=CanCom_FD16RxSignalsSR.COMRX_MCPB_Control_Board_Temperature_P_MCPB_STATUS_FD16
          data-send-points:
            access DSP_VeCANR_y_MCPBCtrlBoarTempP_FD16_VeCANR_y_MCPBCtrlBoarTempP_FD16: accessed-variable=VeCANR_y_MCPBCtrlBoarTempP_FD16.VeCANR_y_MCPBCtrlBoarTempP_FD16
            access DSP_VeCANR_b_MCPBCtrlBoarTempP_FD16TO_VeCANR_b_MCPBCtrlBoarTempP_FD16TO: accessed-variable=VeCANR_b_MCPBCtrlBoarTempP_FD16TO.VeCANR_b_MCPBCtrlBoarTempP_FD16TO
        COMRX_MCPB_CoolantTemp_P_MCPB_STATUS_FD16_Received: symbol=ApplCanComAb_FD16_COMRX_MCPB_CoolantTemp_P_MCPB_STATUS_FD16_Received  # Received
          data-receive-point-by-arguments:
            access DRP_CanCom_FD16RxSignalsSR_COMRX_MCPB_CoolantTemp_P_MCPB_STATUS_FD16: accessed-variable=CanCom_FD16RxSignalsSR.COMRX_MCPB_CoolantTemp_P_MCPB_STATUS_FD16
          data-send-points:
            access DSP_VeCANR_T_MCPB_CoolantTmp_P_FD16_VeCANR_T_MCPB_CoolantTmp_P_FD16: accessed-variable=VeCANR_T_MCPB_CoolantTmp_P_FD16.VeCANR_T_MCPB_CoolantTmp_P_FD16
            access DSP_VeCANR_b_MCPB_CoolantTmp_P_FD16TO_VeCANR_b_MCPB_CoolantTmp_P_FD16TO: accessed-variable=VeCANR_b_MCPB_CoolantTmp_P_FD16TO.VeCANR_b_MCPB_CoolantTmp_P_FD16TO
        COMRX_MCPB_CoolantTemp_P_MCPB_STATUS_FD16_Error: symbol=ApplCanComAb_FD16_COMRX_MCPB_CoolantTemp_P_MCPB_STATUS_FD16_Error  # Error
          data-receive-point-by-arguments:
            access DRP_CanCom_FD16RxSignalsSR_COMRX_MCPB_CoolantTemp_P_MCPB_STATUS_FD16: accessed-variable=CanCom_FD16RxSignalsSR.COMRX_MCPB_CoolantTemp_P_MCPB_STATUS_FD16
          data-send-points:
            access DSP_VeCANR_T_MCPB_CoolantTmp_P_FD16_VeCANR_T_MCPB_CoolantTmp_P_FD16: accessed-variable=VeCANR_T_MCPB_CoolantTmp_P_FD16.VeCANR_T_MCPB_CoolantTmp_P_FD16
            access DSP_VeCANR_b_MCPB_CoolantTmp_P_FD16TO_VeCANR_b_MCPB_CoolantTmp_P_FD16TO: accessed-variable=VeCANR_b_MCPB_CoolantTmp_P_FD16TO.VeCANR_b_MCPB_CoolantTmp_P_FD16TO
        COMRX_MCPB_DC_Current_P_MCPB_STATUS_FD16_Received: symbol=ApplCanComAb_FD16_COMRX_MCPB_DC_Current_P_MCPB_STATUS_FD16_Received  # Received
          data-receive-point-by-arguments:
            access DRP_CanCom_FD16RxSignalsSR_COMRX_MCPB_DC_Current_P_MCPB_STATUS_FD16: accessed-variable=CanCom_FD16RxSignalsSR.COMRX_MCPB_DC_Current_P_MCPB_STATUS_FD16
          data-send-points:
            access DSP_VeCANR_I_MCPB_DC_Current_P_FD16_VeCANR_I_MCPB_DC_Current_P_FD16: accessed-variable=VeCANR_I_MCPB_DC_Current_P_FD16.VeCANR_I_MCPB_DC_Current_P_FD16
            access DSP_VeCANR_b_MCPB_DC_Current_P_FD16TO_VeCANR_b_MCPB_DC_Current_P_FD16TO: accessed-variable=VeCANR_b_MCPB_DC_Current_P_FD16TO.VeCANR_b_MCPB_DC_Current_P_FD16TO
        COMRX_MCPB_DC_Current_P_MCPB_STATUS_FD16_Error: symbol=ApplCanComAb_FD16_COMRX_MCPB_DC_Current_P_MCPB_STATUS_FD16_Error  # Error
          data-receive-point-by-arguments:
            access DRP_CanCom_FD16RxSignalsSR_COMRX_MCPB_DC_Current_P_MCPB_STATUS_FD16: accessed-variable=CanCom_FD16RxSignalsSR.COMRX_MCPB_DC_Current_P_MCPB_STATUS_FD16
          data-send-points:
            access DSP_VeCANR_I_MCPB_DC_Current_P_FD16_VeCANR_I_MCPB_DC_Current_P_FD16: accessed-variable=VeCANR_I_MCPB_DC_Current_P_FD16.VeCANR_I_MCPB_DC_Current_P_FD16
            access DSP_VeCANR_b_MCPB_DC_Current_P_FD16TO_VeCANR_b_MCPB_DC_Current_P_FD16TO: accessed-variable=VeCANR_b_MCPB_DC_Current_P_FD16TO.VeCANR_b_MCPB_DC_Current_P_FD16TO
        COMRX_MCPB_DC_Current_V_P_MCPB_STATUS_FD16_Received: symbol=ApplCanComAb_FD16_COMRX_MCPB_DC_Current_V_P_MCPB_STATUS_FD16_Received  # Received
          data-receive-point-by-arguments:
            access DRP_CanCom_FD16RxSignalsSR_COMRX_MCPB_DC_Current_V_P_MCPB_STATUS_FD16: accessed-variable=CanCom_FD16RxSignalsSR.COMRX_MCPB_DC_Current_V_P_MCPB_STATUS_FD16
          data-send-points:
            access DSP_VeCANR_b_MCPB_DC_Crrnt_V_P_FD16_VeCANR_b_MCPB_DC_Crrnt_V_P_FD16: accessed-variable=VeCANR_b_MCPB_DC_Crrnt_V_P_FD16.VeCANR_b_MCPB_DC_Crrnt_V_P_FD16
            access DSP_VeCANR_b_MCPB_DC_Crrnt_V_P_FD16TO_VeCANR_b_MCPB_DC_Crrnt_V_P_FD16TO: accessed-variable=VeCANR_b_MCPB_DC_Crrnt_V_P_FD16TO.VeCANR_b_MCPB_DC_Crrnt_V_P_FD16TO
        COMRX_MCPB_DC_Current_V_P_MCPB_STATUS_FD16_Error: symbol=ApplCanComAb_FD16_COMRX_MCPB_DC_Current_V_P_MCPB_STATUS_FD16_Error  # Error
          data-receive-point-by-arguments:
            access DRP_CanCom_FD16RxSignalsSR_COMRX_MCPB_DC_Current_V_P_MCPB_STATUS_FD16: accessed-variable=CanCom_FD16RxSignalsSR.COMRX_MCPB_DC_Current_V_P_MCPB_STATUS_FD16
          data-send-points:
            access DSP_VeCANR_b_MCPB_DC_Crrnt_V_P_FD16_VeCANR_b_MCPB_DC_Crrnt_V_P_FD16: accessed-variable=VeCANR_b_MCPB_DC_Crrnt_V_P_FD16.VeCANR_b_MCPB_DC_Crrnt_V_P_FD16
            access DSP_VeCANR_b_MCPB_DC_Crrnt_V_P_FD16TO_VeCANR_b_MCPB_DC_Crrnt_V_P_FD16TO: accessed-variable=VeCANR_b_MCPB_DC_Crrnt_V_P_FD16TO.VeCANR_b_MCPB_DC_Crrnt_V_P_FD16TO
        COMRX_MCPB_DC_Volt_V_P_MCPB_STATUS_FD16_Received: symbol=ApplCanComAb_FD16_COMRX_MCPB_DC_Volt_V_P_MCPB_STATUS_FD16_Received  # Received
          data-receive-point-by-arguments:
            access DRP_CanCom_FD16RxSignalsSR_COMRX_MCPB_DC_Volt_V_P_MCPB_STATUS_FD16: accessed-variable=CanCom_FD16RxSignalsSR.COMRX_MCPB_DC_Volt_V_P_MCPB_STATUS_FD16
          data-send-points:
            access DSP_VeCANR_b_MCPB_DC_Volt_V_P_FD16_VeCANR_b_MCPB_DC_Volt_V_P_FD16: accessed-variable=VeCANR_b_MCPB_DC_Volt_V_P_FD16.VeCANR_b_MCPB_DC_Volt_V_P_FD16
            access DSP_VeCANR_b_MCPB_DC_Volt_V_P_FD16TO_VeCANR_b_MCPB_DC_Volt_V_P_FD16TO: accessed-variable=VeCANR_b_MCPB_DC_Volt_V_P_FD16TO.VeCANR_b_MCPB_DC_Volt_V_P_FD16TO
        COMRX_MCPB_DC_Volt_V_P_MCPB_STATUS_FD16_Error: symbol=ApplCanComAb_FD16_COMRX_MCPB_DC_Volt_V_P_MCPB_STATUS_FD16_Error  # Error
          data-receive-point-by-arguments:
            access DRP_CanCom_FD16RxSignalsSR_COMRX_MCPB_DC_Volt_V_P_MCPB_STATUS_FD16: accessed-variable=CanCom_FD16RxSignalsSR.COMRX_MCPB_DC_Volt_V_P_MCPB_STATUS_FD16
          data-send-points:
            access DSP_VeCANR_b_MCPB_DC_Volt_V_P_FD16_VeCANR_b_MCPB_DC_Volt_V_P_FD16: accessed-variable=VeCANR_b_MCPB_DC_Volt_V_P_FD16.VeCANR_b_MCPB_DC_Volt_V_P_FD16
            access DSP_VeCANR_b_MCPB_DC_Volt_V_P_FD16TO_VeCANR_b_MCPB_DC_Volt_V_P_FD16TO: accessed-variable=VeCANR_b_MCPB_DC_Volt_V_P_FD16TO.VeCANR_b_MCPB_DC_Volt_V_P_FD16TO
        COMRX_MCPB_DC_Voltage_P_MCPB_STATUS_FD16_Received: symbol=ApplCanComAb_FD16_COMRX_MCPB_DC_Voltage_P_MCPB_STATUS_FD16_Received  # Received
          data-receive-point-by-arguments:
            access DRP_CanCom_FD16RxSignalsSR_COMRX_MCPB_DC_Voltage_P_MCPB_STATUS_FD16: accessed-variable=CanCom_FD16RxSignalsSR.COMRX_MCPB_DC_Voltage_P_MCPB_STATUS_FD16
          data-send-points:
            access DSP_VeCANR_U_MCPB_DC_Voltage_P_FD16_VeCANR_U_MCPB_DC_Voltage_P_FD16: accessed-variable=VeCANR_U_MCPB_DC_Voltage_P_FD16.VeCANR_U_MCPB_DC_Voltage_P_FD16
            access DSP_VeCANR_b_MCPB_DC_Voltage_P_FD16TO_VeCANR_b_MCPB_DC_Voltage_P_FD16TO: accessed-variable=VeCANR_b_MCPB_DC_Voltage_P_FD16TO.VeCANR_b_MCPB_DC_Voltage_P_FD16TO
        COMRX_MCPB_DC_Voltage_P_MCPB_STATUS_FD16_Error: symbol=ApplCanComAb_FD16_COMRX_MCPB_DC_Voltage_P_MCPB_STATUS_FD16_Error  # Error
          data-receive-point-by-arguments:
            access DRP_CanCom_FD16RxSignalsSR_COMRX_MCPB_DC_Voltage_P_MCPB_STATUS_FD16: accessed-variable=CanCom_FD16RxSignalsSR.COMRX_MCPB_DC_Voltage_P_MCPB_STATUS_FD16
          data-send-points:
            access DSP_VeCANR_U_MCPB_DC_Voltage_P_FD16_VeCANR_U_MCPB_DC_Voltage_P_FD16: accessed-variable=VeCANR_U_MCPB_DC_Voltage_P_FD16.VeCANR_U_MCPB_DC_Voltage_P_FD16
            access DSP_VeCANR_b_MCPB_DC_Voltage_P_FD16TO_VeCANR_b_MCPB_DC_Voltage_P_FD16TO: accessed-variable=VeCANR_b_MCPB_DC_Voltage_P_FD16TO.VeCANR_b_MCPB_DC_Voltage_P_FD16TO
        COMRX_MCPB_DerateReason_P_MCPB_STATUS_FD16_Received: symbol=ApplCanComAb_FD16_COMRX_MCPB_DerateReason_P_MCPB_STATUS_FD16_Received  # Received
          data-receive-point-by-arguments:
            access DRP_CanCom_FD16RxSignalsSR_COMRX_MCPB_DerateReason_P_MCPB_STATUS_FD16: accessed-variable=CanCom_FD16RxSignalsSR.COMRX_MCPB_DerateReason_P_MCPB_STATUS_FD16
          data-send-points:
            access DSP_VeCANR_e_MCPB_DerateResn_P_FD16_VeCANR_e_MCPB_DerateResn_P_FD16: accessed-variable=VeCANR_e_MCPB_DerateResn_P_FD16.VeCANR_e_MCPB_DerateResn_P_FD16
            access DSP_VeCANR_b_MCPB_DerateResn_P_FD16TO_VeCANR_b_MCPB_DerateResn_P_FD16TO: accessed-variable=VeCANR_b_MCPB_DerateResn_P_FD16TO.VeCANR_b_MCPB_DerateResn_P_FD16TO
        COMRX_MCPB_DerateReason_P_MCPB_STATUS_FD16_Error: symbol=ApplCanComAb_FD16_COMRX_MCPB_DerateReason_P_MCPB_STATUS_FD16_Error  # Error
          data-receive-point-by-arguments:
            access DRP_CanCom_FD16RxSignalsSR_COMRX_MCPB_DerateReason_P_MCPB_STATUS_FD16: accessed-variable=CanCom_FD16RxSignalsSR.COMRX_MCPB_DerateReason_P_MCPB_STATUS_FD16
          data-send-points:
            access DSP_VeCANR_e_MCPB_DerateResn_P_FD16_VeCANR_e_MCPB_DerateResn_P_FD16: accessed-variable=VeCANR_e_MCPB_DerateResn_P_FD16.VeCANR_e_MCPB_DerateResn_P_FD16
            access DSP_VeCANR_b_MCPB_DerateResn_P_FD16TO_VeCANR_b_MCPB_DerateResn_P_FD16TO: accessed-variable=VeCANR_b_MCPB_DerateResn_P_FD16TO.VeCANR_b_MCPB_DerateResn_P_FD16TO
        COMRX_MCPB_Inverter_Temp_P_MCPB_STATUS_FD16_Received: symbol=ApplCanComAb_FD16_COMRX_MCPB_Inverter_Temp_P_MCPB_STATUS_FD16_Received  # Received
          data-receive-point-by-arguments:
            access DRP_CanCom_FD16RxSignalsSR_COMRX_MCPB_Inverter_Temp_P_MCPB_STATUS_FD16: accessed-variable=CanCom_FD16RxSignalsSR.COMRX_MCPB_Inverter_Temp_P_MCPB_STATUS_FD16
          data-send-points:
            access DSP_VeCANR_T_MCPB_InvertTemp_P_FD16_VeCANR_T_MCPB_InvertTemp_P_FD16: accessed-variable=VeCANR_T_MCPB_InvertTemp_P_FD16.VeCANR_T_MCPB_InvertTemp_P_FD16
            access DSP_VeCANR_b_MCPB_InvertTemp_P_FD16TO_VeCANR_b_MCPB_InvertTemp_P_FD16TO: accessed-variable=VeCANR_b_MCPB_InvertTemp_P_FD16TO.VeCANR_b_MCPB_InvertTemp_P_FD16TO
        COMRX_MCPB_Inverter_Temp_P_MCPB_STATUS_FD16_Error: symbol=ApplCanComAb_FD16_COMRX_MCPB_Inverter_Temp_P_MCPB_STATUS_FD16_Error  # Error
          data-receive-point-by-arguments:
            access DRP_CanCom_FD16RxSignalsSR_COMRX_MCPB_Inverter_Temp_P_MCPB_STATUS_FD16: accessed-variable=CanCom_FD16RxSignalsSR.COMRX_MCPB_Inverter_Temp_P_MCPB_STATUS_FD16
          data-send-points:
            access DSP_VeCANR_T_MCPB_InvertTemp_P_FD16_VeCANR_T_MCPB_InvertTemp_P_FD16: accessed-variable=VeCANR_T_MCPB_InvertTemp_P_FD16.VeCANR_T_MCPB_InvertTemp_P_FD16
            access DSP_VeCANR_b_MCPB_InvertTemp_P_FD16TO_VeCANR_b_MCPB_InvertTemp_P_FD16TO: accessed-variable=VeCANR_b_MCPB_InvertTemp_P_FD16TO.VeCANR_b_MCPB_InvertTemp_P_FD16TO
        COMRX_MCPB_PIM_DC_Side_Busbar_Temp_P_MCPB_STATUS_FD16_Received: symbol=ApplCanComAb_FD16_COMRX_MCPB_PIM_DC_Side_Busbar_Temp_P_MCPB_STATUS_FD16_Received  # Received
          data-receive-point-by-arguments:
            access DRP_CanCom_FD16RxSignalsSR_COMRX_MCPB_PIM_DC_Side_Busbar_Temp_P_MCPB_STATUS_FD16: accessed-variable=CanCom_FD16RxSignalsSR.COMRX_MCPB_PIM_DC_Side_Busbar_Temp_P_MCPB_STATUS_FD16
          data-send-points:
            access DSP_VeCANR_T_MCPBPIMDCSdBusTmpPFD16_VeCANR_T_MCPBPIMDCSdBusTmpPFD16: accessed-variable=VeCANR_T_MCPBPIMDCSdBusTmpPFD16.VeCANR_T_MCPBPIMDCSdBusTmpPFD16
            access DSP_VeCANR_b_MCPBPIMDCSdBusTmpPFD16TO_VeCANR_b_MCPBPIMDCSdBusTmpPFD16TO: accessed-variable=VeCANR_b_MCPBPIMDCSdBusTmpPFD16TO.VeCANR_b_MCPBPIMDCSdBusTmpPFD16TO
        COMRX_MCPB_PIM_DC_Side_Busbar_Temp_P_MCPB_STATUS_FD16_Error: symbol=ApplCanComAb_FD16_COMRX_MCPB_PIM_DC_Side_Busbar_Temp_P_MCPB_STATUS_FD16_Error  # Error
          data-receive-point-by-arguments:
            access DRP_CanCom_FD16RxSignalsSR_COMRX_MCPB_PIM_DC_Side_Busbar_Temp_P_MCPB_STATUS_FD16: accessed-variable=CanCom_FD16RxSignalsSR.COMRX_MCPB_PIM_DC_Side_Busbar_Temp_P_MCPB_STATUS_FD16
          data-send-points:
            access DSP_VeCANR_T_MCPBPIMDCSdBusTmpPFD16_VeCANR_T_MCPBPIMDCSdBusTmpPFD16: accessed-variable=VeCANR_T_MCPBPIMDCSdBusTmpPFD16.VeCANR_T_MCPBPIMDCSdBusTmpPFD16
            access DSP_VeCANR_b_MCPBPIMDCSdBusTmpPFD16TO_VeCANR_b_MCPBPIMDCSdBusTmpPFD16TO: accessed-variable=VeCANR_b_MCPBPIMDCSdBusTmpPFD16TO.VeCANR_b_MCPBPIMDCSdBusTmpPFD16TO
        COMRX_MCPB_Rotor_Temperature_P_MCPB_STATUS_FD16_Received: symbol=ApplCanComAb_FD16_COMRX_MCPB_Rotor_Temperature_P_MCPB_STATUS_FD16_Received  # Received
          data-receive-point-by-arguments:
            access DRP_CanCom_FD16RxSignalsSR_COMRX_MCPB_Rotor_Temperature_P_MCPB_STATUS_FD16: accessed-variable=CanCom_FD16RxSignalsSR.COMRX_MCPB_Rotor_Temperature_P_MCPB_STATUS_FD16
          data-send-points:
            access DSP_VeCANR_T_MCPBRotorTemp_P_FD16_VeCANR_T_MCPBRotorTemp_P_FD16: accessed-variable=VeCANR_T_MCPBRotorTemp_P_FD16.VeCANR_T_MCPBRotorTemp_P_FD16
            access DSP_VeCANR_b_MCPBRotorTemp_P_FD16TO_VeCANR_b_MCPBRotorTemp_P_FD16TO: accessed-variable=VeCANR_b_MCPBRotorTemp_P_FD16TO.VeCANR_b_MCPBRotorTemp_P_FD16TO
        COMRX_MCPB_Rotor_Temperature_P_MCPB_STATUS_FD16_Error: symbol=ApplCanComAb_FD16_COMRX_MCPB_Rotor_Temperature_P_MCPB_STATUS_FD16_Error  # Error
          data-receive-point-by-arguments:
            access DRP_CanCom_FD16RxSignalsSR_COMRX_MCPB_Rotor_Temperature_P_MCPB_STATUS_FD16: accessed-variable=CanCom_FD16RxSignalsSR.COMRX_MCPB_Rotor_Temperature_P_MCPB_STATUS_FD16
          data-send-points:
            access DSP_VeCANR_T_MCPBRotorTemp_P_FD16_VeCANR_T_MCPBRotorTemp_P_FD16: accessed-variable=VeCANR_T_MCPBRotorTemp_P_FD16.VeCANR_T_MCPBRotorTemp_P_FD16
            access DSP_VeCANR_b_MCPBRotorTemp_P_FD16TO_VeCANR_b_MCPBRotorTemp_P_FD16TO: accessed-variable=VeCANR_b_MCPBRotorTemp_P_FD16TO.VeCANR_b_MCPBRotorTemp_P_FD16TO
        COMRX_MCPB_Service_Lamp_Request_P_MCPB_STATUS_FD16_Received: symbol=ApplCanComAb_FD16_COMRX_MCPB_Service_Lamp_Request_P_MCPB_STATUS_FD16_Received  # Received
          data-receive-point-by-arguments:
            access DRP_CanCom_FD16RxSignalsSR_COMRX_MCPB_Service_Lamp_Request_P_MCPB_STATUS_FD16: accessed-variable=CanCom_FD16RxSignalsSR.COMRX_MCPB_Service_Lamp_Request_P_MCPB_STATUS_FD16
          data-send-points:
            access DSP_VeCANR_b_MCPBServLampReq_P_FD16_VeCANR_b_MCPBServLampReq_P_FD16: accessed-variable=VeCANR_b_MCPBServLampReq_P_FD16.VeCANR_b_MCPBServLampReq_P_FD16
            access DSP_VeCANR_b_MCPBServLampReq_P_FD16TO_VeCANR_b_MCPBServLampReq_P_FD16TO: accessed-variable=VeCANR_b_MCPBServLampReq_P_FD16TO.VeCANR_b_MCPBServLampReq_P_FD16TO
        COMRX_MCPB_Service_Lamp_Request_P_MCPB_STATUS_FD16_Error: symbol=ApplCanComAb_FD16_COMRX_MCPB_Service_Lamp_Request_P_MCPB_STATUS_FD16_Error  # Error
          data-receive-point-by-arguments:
            access DRP_CanCom_FD16RxSignalsSR_COMRX_MCPB_Service_Lamp_Request_P_MCPB_STATUS_FD16: accessed-variable=CanCom_FD16RxSignalsSR.COMRX_MCPB_Service_Lamp_Request_P_MCPB_STATUS_FD16
          data-send-points:
            access DSP_VeCANR_b_MCPBServLampReq_P_FD16_VeCANR_b_MCPBServLampReq_P_FD16: accessed-variable=VeCANR_b_MCPBServLampReq_P_FD16.VeCANR_b_MCPBServLampReq_P_FD16
            access DSP_VeCANR_b_MCPBServLampReq_P_FD16TO_VeCANR_b_MCPBServLampReq_P_FD16TO: accessed-variable=VeCANR_b_MCPBServLampReq_P_FD16TO.VeCANR_b_MCPBServLampReq_P_FD16TO
        COMRX_CLrDiagInfo_SGCP_P_SGCP_STATUS_FD16_Received: symbol=ApplCanComAb_FD16_COMRX_CLrDiagInfo_SGCP_P_SGCP_STATUS_FD16_Received  # Received
          data-receive-point-by-arguments:
            access DRP_CanCom_FD16RxSignalsSR_COMRX_CLrDiagInfo_SGCP_P_SGCP_STATUS_FD16: accessed-variable=CanCom_FD16RxSignalsSR.COMRX_CLrDiagInfo_SGCP_P_SGCP_STATUS_FD16
          data-send-points:
            access DSP_VeCANR_b_CLrDiagInfoSGCP_P_FD16_VeCANR_b_CLrDiagInfoSGCP_P_FD16: accessed-variable=VeCANR_b_CLrDiagInfoSGCP_P_FD16.VeCANR_b_CLrDiagInfoSGCP_P_FD16
            access DSP_VeCANR_b_CLrDiagInfoSGCP_P_FD16TO_VeCANR_b_CLrDiagInfoSGCP_P_FD16TO: accessed-variable=VeCANR_b_CLrDiagInfoSGCP_P_FD16TO.VeCANR_b_CLrDiagInfoSGCP_P_FD16TO
        COMRX_CLrDiagInfo_SGCP_P_SGCP_STATUS_FD16_Error: symbol=ApplCanComAb_FD16_COMRX_CLrDiagInfo_SGCP_P_SGCP_STATUS_FD16_Error  # Error
          data-receive-point-by-arguments:
            access DRP_CanCom_FD16RxSignalsSR_COMRX_CLrDiagInfo_SGCP_P_SGCP_STATUS_FD16: accessed-variable=CanCom_FD16RxSignalsSR.COMRX_CLrDiagInfo_SGCP_P_SGCP_STATUS_FD16
          data-send-points:
            access DSP_VeCANR_b_CLrDiagInfoSGCP_P_FD16_VeCANR_b_CLrDiagInfoSGCP_P_FD16: accessed-variable=VeCANR_b_CLrDiagInfoSGCP_P_FD16.VeCANR_b_CLrDiagInfoSGCP_P_FD16
            access DSP_VeCANR_b_CLrDiagInfoSGCP_P_FD16TO_VeCANR_b_CLrDiagInfoSGCP_P_FD16TO: accessed-variable=VeCANR_b_CLrDiagInfoSGCP_P_FD16TO.VeCANR_b_CLrDiagInfoSGCP_P_FD16TO
        COMRX_CRC_SGCP_STATUS_SGCP_STATUS_FD16_Received: symbol=ApplCanComAb_FD16_COMRX_CRC_SGCP_STATUS_SGCP_STATUS_FD16_Received  # Received
          data-receive-point-by-arguments:
            access DRP_CanCom_FD16RxSignalsSR_COMRX_CRC_SGCP_STATUS_SGCP_STATUS_FD16: accessed-variable=CanCom_FD16RxSignalsSR.COMRX_CRC_SGCP_STATUS_SGCP_STATUS_FD16
          data-send-points:
            access DSP_VeCANR_y_CRC_SGCP_STATUS_FD16_VeCANR_y_CRC_SGCP_STATUS_FD16: accessed-variable=VeCANR_y_CRC_SGCP_STATUS_FD16.VeCANR_y_CRC_SGCP_STATUS_FD16
            access DSP_VeCANR_b_CRC_SGCP_STATUS_FD16TO_VeCANR_b_CRC_SGCP_STATUS_FD16TO: accessed-variable=VeCANR_b_CRC_SGCP_STATUS_FD16TO.VeCANR_b_CRC_SGCP_STATUS_FD16TO
        COMRX_CRC_SGCP_STATUS_SGCP_STATUS_FD16_Error: symbol=ApplCanComAb_FD16_COMRX_CRC_SGCP_STATUS_SGCP_STATUS_FD16_Error  # Error
          data-receive-point-by-arguments:
            access DRP_CanCom_FD16RxSignalsSR_COMRX_CRC_SGCP_STATUS_SGCP_STATUS_FD16: accessed-variable=CanCom_FD16RxSignalsSR.COMRX_CRC_SGCP_STATUS_SGCP_STATUS_FD16
          data-send-points:
            access DSP_VeCANR_y_CRC_SGCP_STATUS_FD16_VeCANR_y_CRC_SGCP_STATUS_FD16: accessed-variable=VeCANR_y_CRC_SGCP_STATUS_FD16.VeCANR_y_CRC_SGCP_STATUS_FD16
            access DSP_VeCANR_b_CRC_SGCP_STATUS_FD16TO_VeCANR_b_CRC_SGCP_STATUS_FD16TO: accessed-variable=VeCANR_b_CRC_SGCP_STATUS_FD16TO.VeCANR_b_CRC_SGCP_STATUS_FD16TO
        COMRX_MC_SGCP_STATUS_SGCP_STATUS_FD16_Received: symbol=ApplCanComAb_FD16_COMRX_MC_SGCP_STATUS_SGCP_STATUS_FD16_Received  # Received
          data-receive-point-by-arguments:
            access DRP_CanCom_FD16RxSignalsSR_COMRX_MC_SGCP_STATUS_SGCP_STATUS_FD16: accessed-variable=CanCom_FD16RxSignalsSR.COMRX_MC_SGCP_STATUS_SGCP_STATUS_FD16
          data-send-points:
            access DSP_VeCANR_y_MC_SGCP_STATUS_FD16_VeCANR_y_MC_SGCP_STATUS_FD16: accessed-variable=VeCANR_y_MC_SGCP_STATUS_FD16.VeCANR_y_MC_SGCP_STATUS_FD16
            access DSP_VeCANR_b_MC_SGCP_STATUS_FD16TO_VeCANR_b_MC_SGCP_STATUS_FD16TO: accessed-variable=VeCANR_b_MC_SGCP_STATUS_FD16TO.VeCANR_b_MC_SGCP_STATUS_FD16TO
        COMRX_MC_SGCP_STATUS_SGCP_STATUS_FD16_Error: symbol=ApplCanComAb_FD16_COMRX_MC_SGCP_STATUS_SGCP_STATUS_FD16_Error  # Error
          data-receive-point-by-arguments:
            access DRP_CanCom_FD16RxSignalsSR_COMRX_MC_SGCP_STATUS_SGCP_STATUS_FD16: accessed-variable=CanCom_FD16RxSignalsSR.COMRX_MC_SGCP_STATUS_SGCP_STATUS_FD16
          data-send-points:
            access DSP_VeCANR_y_MC_SGCP_STATUS_FD16_VeCANR_y_MC_SGCP_STATUS_FD16: accessed-variable=VeCANR_y_MC_SGCP_STATUS_FD16.VeCANR_y_MC_SGCP_STATUS_FD16
            access DSP_VeCANR_b_MC_SGCP_STATUS_FD16TO_VeCANR_b_MC_SGCP_STATUS_FD16TO: accessed-variable=VeCANR_b_MC_SGCP_STATUS_FD16TO.VeCANR_b_MC_SGCP_STATUS_FD16TO
        COMRX_SGCP_Control_Board_Temperature_P_SGCP_STATUS_FD16_Received: symbol=ApplCanComAb_FD16_COMRX_SGCP_Control_Board_Temperature_P_SGCP_STATUS_FD16_Received  # Received
          data-receive-point-by-arguments:
            access DRP_CanCom_FD16RxSignalsSR_COMRX_SGCP_Control_Board_Temperature_P_SGCP_STATUS_FD16: accessed-variable=CanCom_FD16RxSignalsSR.COMRX_SGCP_Control_Board_Temperature_P_SGCP_STATUS_FD16
          data-send-points:
            access DSP_VeCANR_T_SGCPCtrlBoarTempP_FD16_VeCANR_T_SGCPCtrlBoarTempP_FD16: accessed-variable=VeCANR_T_SGCPCtrlBoarTempP_FD16.VeCANR_T_SGCPCtrlBoarTempP_FD16
            access DSP_VeCANR_b_SGCPCtrlBoarTempP_FD16TO_VeCANR_b_SGCPCtrlBoarTempP_FD16TO: accessed-variable=VeCANR_b_SGCPCtrlBoarTempP_FD16TO.VeCANR_b_SGCPCtrlBoarTempP_FD16TO
        COMRX_SGCP_Control_Board_Temperature_P_SGCP_STATUS_FD16_Error: symbol=ApplCanComAb_FD16_COMRX_SGCP_Control_Board_Temperature_P_SGCP_STATUS_FD16_Error  # Error
          data-receive-point-by-arguments:
            access DRP_CanCom_FD16RxSignalsSR_COMRX_SGCP_Control_Board_Temperature_P_SGCP_STATUS_FD16: accessed-variable=CanCom_FD16RxSignalsSR.COMRX_SGCP_Control_Board_Temperature_P_SGCP_STATUS_FD16
          data-send-points:
            access DSP_VeCANR_T_SGCPCtrlBoarTempP_FD16_VeCANR_T_SGCPCtrlBoarTempP_FD16: accessed-variable=VeCANR_T_SGCPCtrlBoarTempP_FD16.VeCANR_T_SGCPCtrlBoarTempP_FD16
            access DSP_VeCANR_b_SGCPCtrlBoarTempP_FD16TO_VeCANR_b_SGCPCtrlBoarTempP_FD16TO: accessed-variable=VeCANR_b_SGCPCtrlBoarTempP_FD16TO.VeCANR_b_SGCPCtrlBoarTempP_FD16TO
        COMRX_SGCP_CoolantTemp_P_SGCP_STATUS_FD16_Received: symbol=ApplCanComAb_FD16_COMRX_SGCP_CoolantTemp_P_SGCP_STATUS_FD16_Received  # Received
          data-receive-point-by-arguments:
            access DRP_CanCom_FD16RxSignalsSR_COMRX_SGCP_CoolantTemp_P_SGCP_STATUS_FD16: accessed-variable=CanCom_FD16RxSignalsSR.COMRX_SGCP_CoolantTemp_P_SGCP_STATUS_FD16
          data-send-points:
            access DSP_VeCANR_T_SGCP_CoolantTmp_P_FD16_VeCANR_T_SGCP_CoolantTmp_P_FD16: accessed-variable=VeCANR_T_SGCP_CoolantTmp_P_FD16.VeCANR_T_SGCP_CoolantTmp_P_FD16
            access DSP_VeCANR_b_SGCP_CoolantTmp_P_FD16TO_VeCANR_b_SGCP_CoolantTmp_P_FD16TO: accessed-variable=VeCANR_b_SGCP_CoolantTmp_P_FD16TO.VeCANR_b_SGCP_CoolantTmp_P_FD16TO
        COMRX_SGCP_CoolantTemp_P_SGCP_STATUS_FD16_Error: symbol=ApplCanComAb_FD16_COMRX_SGCP_CoolantTemp_P_SGCP_STATUS_FD16_Error  # Error
          data-receive-point-by-arguments:
            access DRP_CanCom_FD16RxSignalsSR_COMRX_SGCP_CoolantTemp_P_SGCP_STATUS_FD16: accessed-variable=CanCom_FD16RxSignalsSR.COMRX_SGCP_CoolantTemp_P_SGCP_STATUS_FD16
          data-send-points:
            access DSP_VeCANR_T_SGCP_CoolantTmp_P_FD16_VeCANR_T_SGCP_CoolantTmp_P_FD16: accessed-variable=VeCANR_T_SGCP_CoolantTmp_P_FD16.VeCANR_T_SGCP_CoolantTmp_P_FD16
            access DSP_VeCANR_b_SGCP_CoolantTmp_P_FD16TO_VeCANR_b_SGCP_CoolantTmp_P_FD16TO: accessed-variable=VeCANR_b_SGCP_CoolantTmp_P_FD16TO.VeCANR_b_SGCP_CoolantTmp_P_FD16TO
        COMRX_SGCP_DC_Current_P_SGCP_STATUS_FD16_Received: symbol=ApplCanComAb_FD16_COMRX_SGCP_DC_Current_P_SGCP_STATUS_FD16_Received  # Received
          data-receive-point-by-arguments:
            access DRP_CanCom_FD16RxSignalsSR_COMRX_SGCP_DC_Current_P_SGCP_STATUS_FD16: accessed-variable=CanCom_FD16RxSignalsSR.COMRX_SGCP_DC_Current_P_SGCP_STATUS_FD16
          data-send-points:
            access DSP_VeCANR_I_SGCP_DC_Current_P_FD16_VeCANR_I_SGCP_DC_Current_P_FD16: accessed-variable=VeCANR_I_SGCP_DC_Current_P_FD16.VeCANR_I_SGCP_DC_Current_P_FD16
            access DSP_VeCANR_b_SGCP_DC_Current_P_FD16TO_VeCANR_b_SGCP_DC_Current_P_FD16TO: accessed-variable=VeCANR_b_SGCP_DC_Current_P_FD16TO.VeCANR_b_SGCP_DC_Current_P_FD16TO
        COMRX_SGCP_DC_Current_P_SGCP_STATUS_FD16_Error: symbol=ApplCanComAb_FD16_COMRX_SGCP_DC_Current_P_SGCP_STATUS_FD16_Error  # Error
          data-receive-point-by-arguments:
            access DRP_CanCom_FD16RxSignalsSR_COMRX_SGCP_DC_Current_P_SGCP_STATUS_FD16: accessed-variable=CanCom_FD16RxSignalsSR.COMRX_SGCP_DC_Current_P_SGCP_STATUS_FD16
          data-send-points:
            access DSP_VeCANR_I_SGCP_DC_Current_P_FD16_VeCANR_I_SGCP_DC_Current_P_FD16: accessed-variable=VeCANR_I_SGCP_DC_Current_P_FD16.VeCANR_I_SGCP_DC_Current_P_FD16
            access DSP_VeCANR_b_SGCP_DC_Current_P_FD16TO_VeCANR_b_SGCP_DC_Current_P_FD16TO: accessed-variable=VeCANR_b_SGCP_DC_Current_P_FD16TO.VeCANR_b_SGCP_DC_Current_P_FD16TO
        COMRX_SGCP_DC_Current_V_P_SGCP_STATUS_FD16_Received: symbol=ApplCanComAb_FD16_COMRX_SGCP_DC_Current_V_P_SGCP_STATUS_FD16_Received  # Received
          data-receive-point-by-arguments:
            access DRP_CanCom_FD16RxSignalsSR_COMRX_SGCP_DC_Current_V_P_SGCP_STATUS_FD16: accessed-variable=CanCom_FD16RxSignalsSR.COMRX_SGCP_DC_Current_V_P_SGCP_STATUS_FD16
          data-send-points:
            access DSP_VeCANR_b_SGCP_DC_Crrnt_V_P_FD16_VeCANR_b_SGCP_DC_Crrnt_V_P_FD16: accessed-variable=VeCANR_b_SGCP_DC_Crrnt_V_P_FD16.VeCANR_b_SGCP_DC_Crrnt_V_P_FD16
            access DSP_VeCANR_b_SGCP_DC_Crrnt_V_P_FD16TO_VeCANR_b_SGCP_DC_Crrnt_V_P_FD16TO: accessed-variable=VeCANR_b_SGCP_DC_Crrnt_V_P_FD16TO.VeCANR_b_SGCP_DC_Crrnt_V_P_FD16TO
        COMRX_SGCP_DC_Current_V_P_SGCP_STATUS_FD16_Error: symbol=ApplCanComAb_FD16_COMRX_SGCP_DC_Current_V_P_SGCP_STATUS_FD16_Error  # Error
          data-receive-point-by-arguments:
            access DRP_CanCom_FD16RxSignalsSR_COMRX_SGCP_DC_Current_V_P_SGCP_STATUS_FD16: accessed-variable=CanCom_FD16RxSignalsSR.COMRX_SGCP_DC_Current_V_P_SGCP_STATUS_FD16
          data-send-points:
            access DSP_VeCANR_b_SGCP_DC_Crrnt_V_P_FD16_VeCANR_b_SGCP_DC_Crrnt_V_P_FD16: accessed-variable=VeCANR_b_SGCP_DC_Crrnt_V_P_FD16.VeCANR_b_SGCP_DC_Crrnt_V_P_FD16
            access DSP_VeCANR_b_SGCP_DC_Crrnt_V_P_FD16TO_VeCANR_b_SGCP_DC_Crrnt_V_P_FD16TO: accessed-variable=VeCANR_b_SGCP_DC_Crrnt_V_P_FD16TO.VeCANR_b_SGCP_DC_Crrnt_V_P_FD16TO
        COMRX_SGCP_DC_Volt_V_P_SGCP_STATUS_FD16_Received: symbol=ApplCanComAb_FD16_COMRX_SGCP_DC_Volt_V_P_SGCP_STATUS_FD16_Received  # Received
          data-receive-point-by-arguments:
            access DRP_CanCom_FD16RxSignalsSR_COMRX_SGCP_DC_Volt_V_P_SGCP_STATUS_FD16: accessed-variable=CanCom_FD16RxSignalsSR.COMRX_SGCP_DC_Volt_V_P_SGCP_STATUS_FD16
          data-send-points:
            access DSP_VeCANR_b_SGCP_DC_Volt_V_P_FD16_VeCANR_b_SGCP_DC_Volt_V_P_FD16: accessed-variable=VeCANR_b_SGCP_DC_Volt_V_P_FD16.VeCANR_b_SGCP_DC_Volt_V_P_FD16
            access DSP_VeCANR_b_SGCP_DC_Volt_V_P_FD16TO_VeCANR_b_SGCP_DC_Volt_V_P_FD16TO: accessed-variable=VeCANR_b_SGCP_DC_Volt_V_P_FD16TO.VeCANR_b_SGCP_DC_Volt_V_P_FD16TO
        COMRX_SGCP_DC_Volt_V_P_SGCP_STATUS_FD16_Error: symbol=ApplCanComAb_FD16_COMRX_SGCP_DC_Volt_V_P_SGCP_STATUS_FD16_Error  # Error
          data-receive-point-by-arguments:
            access DRP_CanCom_FD16RxSignalsSR_COMRX_SGCP_DC_Volt_V_P_SGCP_STATUS_FD16: accessed-variable=CanCom_FD16RxSignalsSR.COMRX_SGCP_DC_Volt_V_P_SGCP_STATUS_FD16
          data-send-points:
            access DSP_VeCANR_b_SGCP_DC_Volt_V_P_FD16_VeCANR_b_SGCP_DC_Volt_V_P_FD16: accessed-variable=VeCANR_b_SGCP_DC_Volt_V_P_FD16.VeCANR_b_SGCP_DC_Volt_V_P_FD16
            access DSP_VeCANR_b_SGCP_DC_Volt_V_P_FD16TO_VeCANR_b_SGCP_DC_Volt_V_P_FD16TO: accessed-variable=VeCANR_b_SGCP_DC_Volt_V_P_FD16TO.VeCANR_b_SGCP_DC_Volt_V_P_FD16TO
        COMRX_SGCP_DC_Voltage_P_SGCP_STATUS_FD16_Received: symbol=ApplCanComAb_FD16_COMRX_SGCP_DC_Voltage_P_SGCP_STATUS_FD16_Received  # Received
          data-receive-point-by-arguments:
            access DRP_CanCom_FD16RxSignalsSR_COMRX_SGCP_DC_Voltage_P_SGCP_STATUS_FD16: accessed-variable=CanCom_FD16RxSignalsSR.COMRX_SGCP_DC_Voltage_P_SGCP_STATUS_FD16
          data-send-points:
            access DSP_VeCANR_U_SGCP_DC_Voltage_P_FD16_VeCANR_U_SGCP_DC_Voltage_P_FD16: accessed-variable=VeCANR_U_SGCP_DC_Voltage_P_FD16.VeCANR_U_SGCP_DC_Voltage_P_FD16
            access DSP_VeCANR_b_SGCP_DC_Voltage_P_FD16TO_VeCANR_b_SGCP_DC_Voltage_P_FD16TO: accessed-variable=VeCANR_b_SGCP_DC_Voltage_P_FD16TO.VeCANR_b_SGCP_DC_Voltage_P_FD16TO
        COMRX_SGCP_DC_Voltage_P_SGCP_STATUS_FD16_Error: symbol=ApplCanComAb_FD16_COMRX_SGCP_DC_Voltage_P_SGCP_STATUS_FD16_Error  # Error
          data-receive-point-by-arguments:
            access DRP_CanCom_FD16RxSignalsSR_COMRX_SGCP_DC_Voltage_P_SGCP_STATUS_FD16: accessed-variable=CanCom_FD16RxSignalsSR.COMRX_SGCP_DC_Voltage_P_SGCP_STATUS_FD16
          data-send-points:
            access DSP_VeCANR_U_SGCP_DC_Voltage_P_FD16_VeCANR_U_SGCP_DC_Voltage_P_FD16: accessed-variable=VeCANR_U_SGCP_DC_Voltage_P_FD16.VeCANR_U_SGCP_DC_Voltage_P_FD16
            access DSP_VeCANR_b_SGCP_DC_Voltage_P_FD16TO_VeCANR_b_SGCP_DC_Voltage_P_FD16TO: accessed-variable=VeCANR_b_SGCP_DC_Voltage_P_FD16TO.VeCANR_b_SGCP_DC_Voltage_P_FD16TO
        COMRX_SGCP_DerateReason_P_SGCP_STATUS_FD16_Received: symbol=ApplCanComAb_FD16_COMRX_SGCP_DerateReason_P_SGCP_STATUS_FD16_Received  # Received
          data-receive-point-by-arguments:
            access DRP_CanCom_FD16RxSignalsSR_COMRX_SGCP_DerateReason_P_SGCP_STATUS_FD16: accessed-variable=CanCom_FD16RxSignalsSR.COMRX_SGCP_DerateReason_P_SGCP_STATUS_FD16
          data-send-points:
            access DSP_VeCANR_e_SGCP_DerateResn_P_FD16_VeCANR_e_SGCP_DerateResn_P_FD16: accessed-variable=VeCANR_e_SGCP_DerateResn_P_FD16.VeCANR_e_SGCP_DerateResn_P_FD16
            access DSP_VeCANR_b_SGCP_DerateResn_P_FD16TO_VeCANR_b_SGCP_DerateResn_P_FD16TO: accessed-variable=VeCANR_b_SGCP_DerateResn_P_FD16TO.VeCANR_b_SGCP_DerateResn_P_FD16TO
        COMRX_SGCP_DerateReason_P_SGCP_STATUS_FD16_Error: symbol=ApplCanComAb_FD16_COMRX_SGCP_DerateReason_P_SGCP_STATUS_FD16_Error  # Error
          data-receive-point-by-arguments:
            access DRP_CanCom_FD16RxSignalsSR_COMRX_SGCP_DerateReason_P_SGCP_STATUS_FD16: accessed-variable=CanCom_FD16RxSignalsSR.COMRX_SGCP_DerateReason_P_SGCP_STATUS_FD16
          data-send-points:
            access DSP_VeCANR_e_SGCP_DerateResn_P_FD16_VeCANR_e_SGCP_DerateResn_P_FD16: accessed-variable=VeCANR_e_SGCP_DerateResn_P_FD16.VeCANR_e_SGCP_DerateResn_P_FD16
            access DSP_VeCANR_b_SGCP_DerateResn_P_FD16TO_VeCANR_b_SGCP_DerateResn_P_FD16TO: accessed-variable=VeCANR_b_SGCP_DerateResn_P_FD16TO.VeCANR_b_SGCP_DerateResn_P_FD16TO
        COMRX_SGCP_Inverter_Temp_P_SGCP_STATUS_FD16_Received: symbol=ApplCanComAb_FD16_COMRX_SGCP_Inverter_Temp_P_SGCP_STATUS_FD16_Received  # Received
          data-receive-point-by-arguments:
            access DRP_CanCom_FD16RxSignalsSR_COMRX_SGCP_Inverter_Temp_P_SGCP_STATUS_FD16: accessed-variable=CanCom_FD16RxSignalsSR.COMRX_SGCP_Inverter_Temp_P_SGCP_STATUS_FD16
          data-send-points:
            access DSP_VeCANR_T_SGCP_InvertTemp_P_FD16_VeCANR_T_SGCP_InvertTemp_P_FD16: accessed-variable=VeCANR_T_SGCP_InvertTemp_P_FD16.VeCANR_T_SGCP_InvertTemp_P_FD16
            access DSP_VeCANR_b_SGCP_InvertTemp_P_FD16TO_VeCANR_b_SGCP_InvertTemp_P_FD16TO: accessed-variable=VeCANR_b_SGCP_InvertTemp_P_FD16TO.VeCANR_b_SGCP_InvertTemp_P_FD16TO
        COMRX_SGCP_Inverter_Temp_P_SGCP_STATUS_FD16_Error: symbol=ApplCanComAb_FD16_COMRX_SGCP_Inverter_Temp_P_SGCP_STATUS_FD16_Error  # Error
          data-receive-point-by-arguments:
            access DRP_CanCom_FD16RxSignalsSR_COMRX_SGCP_Inverter_Temp_P_SGCP_STATUS_FD16: accessed-variable=CanCom_FD16RxSignalsSR.COMRX_SGCP_Inverter_Temp_P_SGCP_STATUS_FD16
          data-send-points:
            access DSP_VeCANR_T_SGCP_InvertTemp_P_FD16_VeCANR_T_SGCP_InvertTemp_P_FD16: accessed-variable=VeCANR_T_SGCP_InvertTemp_P_FD16.VeCANR_T_SGCP_InvertTemp_P_FD16
            access DSP_VeCANR_b_SGCP_InvertTemp_P_FD16TO_VeCANR_b_SGCP_InvertTemp_P_FD16TO: accessed-variable=VeCANR_b_SGCP_InvertTemp_P_FD16TO.VeCANR_b_SGCP_InvertTemp_P_FD16TO
        COMRX_SGCP_PIM_AC_Side_Busbar_Temp_P_SGCP_STATUS_FD16_Received: symbol=ApplCanComAb_FD16_COMRX_SGCP_PIM_AC_Side_Busbar_Temp_P_SGCP_STATUS_FD16_Received  # Received
          data-receive-point-by-arguments:
            access DRP_CanCom_FD16RxSignalsSR_COMRX_SGCP_PIM_AC_Side_Busbar_Temp_P_SGCP_STATUS_FD16: accessed-variable=CanCom_FD16RxSignalsSR.COMRX_SGCP_PIM_AC_Side_Busbar_Temp_P_SGCP_STATUS_FD16
          data-send-points:
            access DSP_VeCANR_y_SGCPPIMACSdBusTmpPFD16_VeCANR_y_SGCPPIMACSdBusTmpPFD16: accessed-variable=VeCANR_y_SGCPPIMACSdBusTmpPFD16.VeCANR_y_SGCPPIMACSdBusTmpPFD16
            access DSP_VeCANR_b_SGCPPIMACSdBusTmpPFD16TO_VeCANR_b_SGCPPIMACSdBusTmpPFD16TO: accessed-variable=VeCANR_b_SGCPPIMACSdBusTmpPFD16TO.VeCANR_b_SGCPPIMACSdBusTmpPFD16TO
        COMRX_SGCP_PIM_AC_Side_Busbar_Temp_P_SGCP_STATUS_FD16_Error: symbol=ApplCanComAb_FD16_COMRX_SGCP_PIM_AC_Side_Busbar_Temp_P_SGCP_STATUS_FD16_Error  # Error
          data-receive-point-by-arguments:
            access DRP_CanCom_FD16RxSignalsSR_COMRX_SGCP_PIM_AC_Side_Busbar_Temp_P_SGCP_STATUS_FD16: accessed-variable=CanCom_FD16RxSignalsSR.COMRX_SGCP_PIM_AC_Side_Busbar_Temp_P_SGCP_STATUS_FD16
          data-send-points:
            access DSP_VeCANR_y_SGCPPIMACSdBusTmpPFD16_VeCANR_y_SGCPPIMACSdBusTmpPFD16: accessed-variable=VeCANR_y_SGCPPIMACSdBusTmpPFD16.VeCANR_y_SGCPPIMACSdBusTmpPFD16
            access DSP_VeCANR_b_SGCPPIMACSdBusTmpPFD16TO_VeCANR_b_SGCPPIMACSdBusTmpPFD16TO: accessed-variable=VeCANR_b_SGCPPIMACSdBusTmpPFD16TO.VeCANR_b_SGCPPIMACSdBusTmpPFD16TO
        COMRX_SGCP_PIM_DC_Side_Busbar_Temp_P_SGCP_STATUS_FD16_Received: symbol=ApplCanComAb_FD16_COMRX_SGCP_PIM_DC_Side_Busbar_Temp_P_SGCP_STATUS_FD16_Received  # Received
          data-receive-point-by-arguments:
            access DRP_CanCom_FD16RxSignalsSR_COMRX_SGCP_PIM_DC_Side_Busbar_Temp_P_SGCP_STATUS_FD16: accessed-variable=CanCom_FD16RxSignalsSR.COMRX_SGCP_PIM_DC_Side_Busbar_Temp_P_SGCP_STATUS_FD16
          data-send-points:
            access DSP_VeCANR_T_SGCPPIMDCSdBusTmpPFD16_VeCANR_T_SGCPPIMDCSdBusTmpPFD16: accessed-variable=VeCANR_T_SGCPPIMDCSdBusTmpPFD16.VeCANR_T_SGCPPIMDCSdBusTmpPFD16
            access DSP_VeCANR_b_SGCPPIMDCSdBusTmpPFD16TO_VeCANR_b_SGCPPIMDCSdBusTmpPFD16TO: accessed-variable=VeCANR_b_SGCPPIMDCSdBusTmpPFD16TO.VeCANR_b_SGCPPIMDCSdBusTmpPFD16TO
        COMRX_SGCP_PIM_DC_Side_Busbar_Temp_P_SGCP_STATUS_FD16_Error: symbol=ApplCanComAb_FD16_COMRX_SGCP_PIM_DC_Side_Busbar_Temp_P_SGCP_STATUS_FD16_Error  # Error
          data-receive-point-by-arguments:
            access DRP_CanCom_FD16RxSignalsSR_COMRX_SGCP_PIM_DC_Side_Busbar_Temp_P_SGCP_STATUS_FD16: accessed-variable=CanCom_FD16RxSignalsSR.COMRX_SGCP_PIM_DC_Side_Busbar_Temp_P_SGCP_STATUS_FD16
          data-send-points:
            access DSP_VeCANR_T_SGCPPIMDCSdBusTmpPFD16_VeCANR_T_SGCPPIMDCSdBusTmpPFD16: accessed-variable=VeCANR_T_SGCPPIMDCSdBusTmpPFD16.VeCANR_T_SGCPPIMDCSdBusTmpPFD16
            access DSP_VeCANR_b_SGCPPIMDCSdBusTmpPFD16TO_VeCANR_b_SGCPPIMDCSdBusTmpPFD16TO: accessed-variable=VeCANR_b_SGCPPIMDCSdBusTmpPFD16TO.VeCANR_b_SGCPPIMDCSdBusTmpPFD16TO
        COMRX_SGCP_Rotor_Temperature_P_SGCP_STATUS_FD16_Received: symbol=ApplCanComAb_FD16_COMRX_SGCP_Rotor_Temperature_P_SGCP_STATUS_FD16_Received  # Received
          data-receive-point-by-arguments:
            access DRP_CanCom_FD16RxSignalsSR_COMRX_SGCP_Rotor_Temperature_P_SGCP_STATUS_FD16: accessed-variable=CanCom_FD16RxSignalsSR.COMRX_SGCP_Rotor_Temperature_P_SGCP_STATUS_FD16
          data-send-points:
            access DSP_VeCANR_T_SGCPRotorTemp_P_FD16_VeCANR_T_SGCPRotorTemp_P_FD16: accessed-variable=VeCANR_T_SGCPRotorTemp_P_FD16.VeCANR_T_SGCPRotorTemp_P_FD16
            access DSP_VeCANR_b_SGCPRotorTemp_P_FD16TO_VeCANR_b_SGCPRotorTemp_P_FD16TO: accessed-variable=VeCANR_b_SGCPRotorTemp_P_FD16TO.VeCANR_b_SGCPRotorTemp_P_FD16TO
        COMRX_SGCP_Rotor_Temperature_P_SGCP_STATUS_FD16_Error: symbol=ApplCanComAb_FD16_COMRX_SGCP_Rotor_Temperature_P_SGCP_STATUS_FD16_Error  # Error
          data-receive-point-by-arguments:
            access DRP_CanCom_FD16RxSignalsSR_COMRX_SGCP_Rotor_Temperature_P_SGCP_STATUS_FD16: accessed-variable=CanCom_FD16RxSignalsSR.COMRX_SGCP_Rotor_Temperature_P_SGCP_STATUS_FD16
          data-send-points:
            access DSP_VeCANR_T_SGCPRotorTemp_P_FD16_VeCANR_T_SGCPRotorTemp_P_FD16: accessed-variable=VeCANR_T_SGCPRotorTemp_P_FD16.VeCANR_T_SGCPRotorTemp_P_FD16
            access DSP_VeCANR_b_SGCPRotorTemp_P_FD16TO_VeCANR_b_SGCPRotorTemp_P_FD16TO: accessed-variable=VeCANR_b_SGCPRotorTemp_P_FD16TO.VeCANR_b_SGCPRotorTemp_P_FD16TO
        COMRX_SGCP_Service_Lamp_Request_P_SGCP_STATUS_FD16_Received: symbol=ApplCanComAb_FD16_COMRX_SGCP_Service_Lamp_Request_P_SGCP_STATUS_FD16_Received  # Received
          data-receive-point-by-arguments:
            access DRP_CanCom_FD16RxSignalsSR_COMRX_SGCP_Service_Lamp_Request_P_SGCP_STATUS_FD16: accessed-variable=CanCom_FD16RxSignalsSR.COMRX_SGCP_Service_Lamp_Request_P_SGCP_STATUS_FD16
          data-send-points:
            access DSP_VeCANR_b_SGCPServLampReq_P_FD16_VeCANR_b_SGCPServLampReq_P_FD16: accessed-variable=VeCANR_b_SGCPServLampReq_P_FD16.VeCANR_b_SGCPServLampReq_P_FD16
            access DSP_VeCANR_b_SGCPServLampReq_P_FD16TO_VeCANR_b_SGCPServLampReq_P_FD16TO: accessed-variable=VeCANR_b_SGCPServLampReq_P_FD16TO.VeCANR_b_SGCPServLampReq_P_FD16TO
        COMRX_SGCP_Service_Lamp_Request_P_SGCP_STATUS_FD16_Error: symbol=ApplCanComAb_FD16_COMRX_SGCP_Service_Lamp_Request_P_SGCP_STATUS_FD16_Error  # Error
          data-receive-point-by-arguments:
            access DRP_CanCom_FD16RxSignalsSR_COMRX_SGCP_Service_Lamp_Request_P_SGCP_STATUS_FD16: accessed-variable=CanCom_FD16RxSignalsSR.COMRX_SGCP_Service_Lamp_Request_P_SGCP_STATUS_FD16
          data-send-points:
            access DSP_VeCANR_b_SGCPServLampReq_P_FD16_VeCANR_b_SGCPServLampReq_P_FD16: accessed-variable=VeCANR_b_SGCPServLampReq_P_FD16.VeCANR_b_SGCPServLampReq_P_FD16
            access DSP_VeCANR_b_SGCPServLampReq_P_FD16TO_VeCANR_b_SGCPServLampReq_P_FD16TO: accessed-variable=VeCANR_b_SGCPServLampReq_P_FD16TO.VeCANR_b_SGCPServLampReq_P_FD16TO
        SendCANR_CmdIgnSts_FD16: can-be-invoked-concurrently=true, symbol=ApplCanComAb_FD16_SendCANR_CmdIgnSts_FD16  # Transmit
          data-receive-point-by-arguments:
            access DRP_SendCANR_CmdIgnSts_FD16_SendCANR_CmdIgnSts_FD16: accessed-variable=SendCANR_CmdIgnSts_FD16.SendCANR_CmdIgnSts_FD16
            access DRP_SendCANR_CmdIgnSts_FD16Vld_SendCANR_CmdIgnSts_FD16Vld: accessed-variable=SendCANR_CmdIgnSts_FD16Vld.SendCANR_CmdIgnSts_FD16Vld
          data-send-points:
            access DSP_CanCom_FD16TxSignalsSR_COMTX_CmdIgnSts_BCM_FD_10_FD16: accessed-variable=CanCom_FD16TxSignalsSR.COMTX_CmdIgnSts_BCM_FD_10_FD16
        SendCANR_CRC_BCM10_FD16: can-be-invoked-concurrently=true, symbol=ApplCanComAb_FD16_SendCANR_CRC_BCM10_FD16  # Transmit
          data-receive-point-by-arguments:
            access DRP_SendCANR_CRC_BCM10_FD16_SendCANR_CRC_BCM10_FD16: accessed-variable=SendCANR_CRC_BCM10_FD16.SendCANR_CRC_BCM10_FD16
            access DRP_SendCANR_CRC_BCM10_FD16Vld_SendCANR_CRC_BCM10_FD16Vld: accessed-variable=SendCANR_CRC_BCM10_FD16Vld.SendCANR_CRC_BCM10_FD16Vld
          data-send-points:
            access DSP_CanCom_FD16TxSignalsSR_COMTX_CRC_BCM10_BCM_FD_10_FD16: accessed-variable=CanCom_FD16TxSignalsSR.COMTX_CRC_BCM10_BCM_FD_10_FD16
        SendCANR_MsgCounter_BCM10_FD16: can-be-invoked-concurrently=true, symbol=ApplCanComAb_FD16_SendCANR_MsgCounter_BCM10_FD16  # Transmit
          data-receive-point-by-arguments:
            access DRP_SendCANR_MsgCounter_BCM10_FD16_SendCANR_MsgCounter_BCM10_FD16: accessed-variable=SendCANR_MsgCounter_BCM10_FD16.SendCANR_MsgCounter_BCM10_FD16
            access DRP_SendCANR_MsgCounter_BCM10_FD16Vld_SendCANR_MsgCounter_BCM10_FD16Vld: accessed-variable=SendCANR_MsgCounter_BCM10_FD16Vld.SendCANR_MsgCounter_BCM10_FD16Vld
          data-send-points:
            access DSP_CanCom_FD16TxSignalsSR_COMTX_MessageCounter_BCM10_BCM_FD_10_FD16: accessed-variable=CanCom_FD16TxSignalsSR.COMTX_MessageCounter_BCM10_BCM_FD_10_FD16
        SendCANR_OperationalModeStsFD16: can-be-invoked-concurrently=true, symbol=ApplCanComAb_FD16_SendCANR_OperationalModeStsFD16  # Transmit
          data-receive-point-by-arguments:
            access DRP_SendCANR_OperationalModeStsFD16_SendCANR_OperationalModeStsFD16: accessed-variable=SendCANR_OperationalModeStsFD16.SendCANR_OperationalModeStsFD16
            access DRP_SendCANR_OperationalModeStsFD16Vld_SendCANR_OperationalModeStsFD16Vld: accessed-variable=SendCANR_OperationalModeStsFD16Vld.SendCANR_OperationalModeStsFD16Vld
          data-send-points:
            access DSP_CanCom_FD16TxSignalsSR_COMTX_OperationalModeSts_BCM_FD_2_FD16: accessed-variable=CanCom_FD16TxSignalsSR.COMTX_OperationalModeSts_BCM_FD_2_FD16
        SendCANR_ExtTemp_FD16: can-be-invoked-concurrently=true, symbol=ApplCanComAb_FD16_SendCANR_ExtTemp_FD16  # Transmit
          data-receive-point-by-arguments:
            access DRP_SendCANR_ExtTemp_FD16_SendCANR_ExtTemp_FD16: accessed-variable=SendCANR_ExtTemp_FD16.SendCANR_ExtTemp_FD16
            access DRP_SendCANR_ExtTemp_FD16Vld_SendCANR_ExtTemp_FD16Vld: accessed-variable=SendCANR_ExtTemp_FD16Vld.SendCANR_ExtTemp_FD16Vld
          data-send-points:
            access DSP_CanCom_FD16TxSignalsSR_COMTX_ExternalTemperature_BCM_FD_9_FD16: accessed-variable=CanCom_FD16TxSignalsSR.COMTX_ExternalTemperature_BCM_FD_9_FD16
        SendCANR_EPBSts_FD16: can-be-invoked-concurrently=true, symbol=ApplCanComAb_FD16_SendCANR_EPBSts_FD16  # Transmit
          data-receive-point-by-arguments:
            access DRP_SendCANR_EPBSts_FD16_SendCANR_EPBSts_FD16: accessed-variable=SendCANR_EPBSts_FD16.SendCANR_EPBSts_FD16
            access DRP_SendCANR_EPBSts_FD16Vld_SendCANR_EPBSts_FD16Vld: accessed-variable=SendCANR_EPBSts_FD16Vld.SendCANR_EPBSts_FD16Vld
          data-send-points:
            access DSP_CanCom_FD16TxSignalsSR_COMTX_EPBSts_BRAKE_FD_4_FD16: accessed-variable=CanCom_FD16TxSignalsSR.COMTX_EPBSts_BRAKE_FD_4_FD16
        SendCANR_ABSFailSts_FD16: can-be-invoked-concurrently=true, symbol=ApplCanComAb_FD16_SendCANR_ABSFailSts_FD16  # Transmit
          data-receive-point-by-arguments:
            access DRP_SendCANR_ABSFailSts_FD16_SendCANR_ABSFailSts_FD16: accessed-variable=SendCANR_ABSFailSts_FD16.SendCANR_ABSFailSts_FD16
            access DRP_SendCANR_ABSFailSts_FD16Vld_SendCANR_ABSFailSts_FD16Vld: accessed-variable=SendCANR_ABSFailSts_FD16Vld.SendCANR_ABSFailSts_FD16Vld
          data-send-points:
            access DSP_CanCom_FD16TxSignalsSR_COMTX_ABSFailSts_BRAKE_FD_5_FD16: accessed-variable=CanCom_FD16TxSignalsSR.COMTX_ABSFailSts_BRAKE_FD_5_FD16
        SendCANR_ESCFailSts: can-be-invoked-concurrently=true, symbol=ApplCanComAb_FD16_SendCANR_ESCFailSts  # Transmit
          data-receive-point-by-arguments:
            access DRP_SendCANR_ESCFailSts_SendCANR_ESCFailSts: accessed-variable=SendCANR_ESCFailSts.SendCANR_ESCFailSts
            access DRP_SendCANR_ESCFailStsVld_SendCANR_ESCFailStsVld: accessed-variable=SendCANR_ESCFailStsVld.SendCANR_ESCFailStsVld
          data-send-points:
            access DSP_CanCom_FD16TxSignalsSR_COMTX_ESCFailSts_BRAKE_FD_5_FD16: accessed-variable=CanCom_FD16TxSignalsSR.COMTX_ESCFailSts_BRAKE_FD_5_FD16
        SendCANR_N_PDU_7E_FD16: can-be-invoked-concurrently=true, symbol=ApplCanComAb_FD16_SendCANR_N_PDU_7E_FD16  # Transmit
          data-receive-point-by-arguments:
            access DRP_SendCANR_N_PDU_7E_FD16_SendCANR_N_PDU_7E_FD16: accessed-variable=SendCANR_N_PDU_7E_FD16.SendCANR_N_PDU_7E_FD16
            access DRP_SendCANR_N_PDU_7E_FD16Vld_SendCANR_N_PDU_7E_FD16Vld: accessed-variable=SendCANR_N_PDU_7E_FD16Vld.SendCANR_N_PDU_7E_FD16Vld
          data-send-points:
            access DSP_CanCom_FD16TxSignalsSR_COMTX_N_PDU_7E_GLIWA_MCPA_RX_FD16: accessed-variable=CanCom_FD16TxSignalsSR.COMTX_N_PDU_7E_GLIWA_MCPA_RX_FD16
        SendCANR_N_PDU_7F_FD16: can-be-invoked-concurrently=true, symbol=ApplCanComAb_FD16_SendCANR_N_PDU_7F_FD16  # Transmit
          data-receive-point-by-arguments:
            access DRP_SendCANR_N_PDU_7F_FD16_SendCANR_N_PDU_7F_FD16: accessed-variable=SendCANR_N_PDU_7F_FD16.SendCANR_N_PDU_7F_FD16
            access DRP_SendCANR_N_PDU_7F_FD16Vld_SendCANR_N_PDU_7F_FD16Vld: accessed-variable=SendCANR_N_PDU_7F_FD16Vld.SendCANR_N_PDU_7F_FD16Vld
          data-send-points:
            access DSP_CanCom_FD16TxSignalsSR_COMTX_N_PDU_7F_GLIWA_MCPB_RX_FD16: accessed-variable=CanCom_FD16TxSignalsSR.COMTX_N_PDU_7F_GLIWA_MCPB_RX_FD16
        SendCANR_N_PDU_81: can-be-invoked-concurrently=true, symbol=ApplCanComAb_FD16_SendCANR_N_PDU_81  # Transmit
          data-receive-point-by-arguments:
            access DRP_SendCANR_N_PDU_81_SendCANR_N_PDU_81: accessed-variable=SendCANR_N_PDU_81.SendCANR_N_PDU_81
            access DRP_SendCANR_N_PDU_81Vld_SendCANR_N_PDU_81Vld: accessed-variable=SendCANR_N_PDU_81Vld.SendCANR_N_PDU_81Vld
          data-send-points:
            access DSP_CanCom_FD16TxSignalsSR_COMTX_N_PDU_81_GLIWA_SGCP_RX_FD16: accessed-variable=CanCom_FD16TxSignalsSR.COMTX_N_PDU_81_GLIWA_SGCP_RX_FD16
        SendCANR_PerWakeUp_Diag_FD16: can-be-invoked-concurrently=true, symbol=ApplCanComAb_FD16_SendCANR_PerWakeUp_Diag_FD16  # Transmit
          data-receive-point-by-arguments:
            access DRP_SendCANR_PerWakeUp_Diag_FD16_SendCANR_PerWakeUp_Diag_FD16: accessed-variable=SendCANR_PerWakeUp_Diag_FD16.SendCANR_PerWakeUp_Diag_FD16
            access DRP_SendCANR_PerWakeUp_Diag_FD16Vld_SendCANR_PerWakeUp_Diag_FD16Vld: accessed-variable=SendCANR_PerWakeUp_Diag_FD16Vld.SendCANR_PerWakeUp_Diag_FD16Vld
          data-send-points:
            access DSP_CanCom_FD16TxSignalsSR_COMTX_PerWakeUp_Diag_HYBRID_SYSTEM_EPT1_FD16: accessed-variable=CanCom_FD16TxSignalsSR.COMTX_PerWakeUp_Diag_HYBRID_SYSTEM_EPT1_FD16
        SendCANR_WU_Timer_Value_FD16: can-be-invoked-concurrently=true, symbol=ApplCanComAb_FD16_SendCANR_WU_Timer_Value_FD16  # Transmit
          data-receive-point-by-arguments:
            access DRP_SendCANR_WU_Timer_Value_FD16_SendCANR_WU_Timer_Value_FD16: accessed-variable=SendCANR_WU_Timer_Value_FD16.SendCANR_WU_Timer_Value_FD16
            access DRP_SendCANR_WU_Timer_Value_FD16Vld_SendCANR_WU_Timer_Value_FD16Vld: accessed-variable=SendCANR_WU_Timer_Value_FD16Vld.SendCANR_WU_Timer_Value_FD16Vld
          data-send-points:
            access DSP_CanCom_FD16TxSignalsSR_COMTX_WU_Timer_Value_HYBRID_SYSTEM_EPT1_FD16: accessed-variable=CanCom_FD16TxSignalsSR.COMTX_WU_Timer_Value_HYBRID_SYSTEM_EPT1_FD16
        SendCANR_CRC_HYB_THRM_CMND_FD16: can-be-invoked-concurrently=true, symbol=ApplCanComAb_FD16_SendCANR_CRC_HYB_THRM_CMND_FD16  # Transmit
          data-receive-point-by-arguments:
            access DRP_SendCANR_CRC_HYB_THRM_CMND_FD16_SendCANR_CRC_HYB_THRM_CMND_FD16: accessed-variable=SendCANR_CRC_HYB_THRM_CMND_FD16.SendCANR_CRC_HYB_THRM_CMND_FD16
            access DRP_SendCANR_CRC_HYB_THRM_CMND_FD16Vld_SendCANR_CRC_HYB_THRM_CMND_FD16Vld: accessed-variable=SendCANR_CRC_HYB_THRM_CMND_FD16Vld.SendCANR_CRC_HYB_THRM_CMND_FD16Vld
          data-send-points:
            access DSP_CanCom_FD16TxSignalsSR_COMTX_CRC_HYBRID_THERMAL_COMMAND_HYBRID_THERMAL_COMMAND_FD16: accessed-variable=CanCom_FD16TxSignalsSR.COMTX_CRC_HYBRID_THERMAL_COMMAND_HYBRID_THERMAL_COMMAND_FD16
        SendCANR_EOPA_OIL_FlwRate_FD16: can-be-invoked-concurrently=true, symbol=ApplCanComAb_FD16_SendCANR_EOPA_OIL_FlwRate_FD16  # Transmit
          data-receive-point-by-arguments:
            access DRP_SendCANR_EOPA_OIL_FlwRate_FD16_SendCANR_EOPA_OIL_FlwRate_FD16: accessed-variable=SendCANR_EOPA_OIL_FlwRate_FD16.SendCANR_EOPA_OIL_FlwRate_FD16
            access DRP_SendCANR_EOPA_OIL_FlwRate_FD16Vld_SendCANR_EOPA_OIL_FlwRate_FD16Vld: accessed-variable=SendCANR_EOPA_OIL_FlwRate_FD16Vld.SendCANR_EOPA_OIL_FlwRate_FD16Vld
          data-send-points:
            access DSP_CanCom_FD16TxSignalsSR_COMTX_EOPA_OIL_FlwRate_HYBRID_THERMAL_COMMAND_FD16: accessed-variable=CanCom_FD16TxSignalsSR.COMTX_EOPA_OIL_FlwRate_HYBRID_THERMAL_COMMAND_FD16
        SendCANR_EOPA_OIL_TEMP_FD16: can-be-invoked-concurrently=true, symbol=ApplCanComAb_FD16_SendCANR_EOPA_OIL_TEMP_FD16  # Transmit
          data-receive-point-by-arguments:
            access DRP_SendCANR_EOPA_OIL_TEMP_FD16_SendCANR_EOPA_OIL_TEMP_FD16: accessed-variable=SendCANR_EOPA_OIL_TEMP_FD16.SendCANR_EOPA_OIL_TEMP_FD16
            access DRP_SendCANR_EOPA_OIL_TEMP_FD16Vld_SendCANR_EOPA_OIL_TEMP_FD16Vld: accessed-variable=SendCANR_EOPA_OIL_TEMP_FD16Vld.SendCANR_EOPA_OIL_TEMP_FD16Vld
          data-send-points:
            access DSP_CanCom_FD16TxSignalsSR_COMTX_EOPA_OIL_TEMP_HYBRID_THERMAL_COMMAND_FD16: accessed-variable=CanCom_FD16TxSignalsSR.COMTX_EOPA_OIL_TEMP_HYBRID_THERMAL_COMMAND_FD16
        SendCANR_EOPB_OIL_FlwRate_FD16: can-be-invoked-concurrently=true, symbol=ApplCanComAb_FD16_SendCANR_EOPB_OIL_FlwRate_FD16  # Transmit
          data-receive-point-by-arguments:
            access DRP_SendCANR_EOPB_OIL_FlwRate_FD16_SendCANR_EOPB_OIL_FlwRate_FD16: accessed-variable=SendCANR_EOPB_OIL_FlwRate_FD16.SendCANR_EOPB_OIL_FlwRate_FD16
            access DRP_SendCANR_EOPB_OIL_FlwRate_FD16Vld_SendCANR_EOPB_OIL_FlwRate_FD16Vld: accessed-variable=SendCANR_EOPB_OIL_FlwRate_FD16Vld.SendCANR_EOPB_OIL_FlwRate_FD16Vld
          data-send-points:
            access DSP_CanCom_FD16TxSignalsSR_COMTX_EOPB_OIL_FlwRate_HYBRID_THERMAL_COMMAND_FD16: accessed-variable=CanCom_FD16TxSignalsSR.COMTX_EOPB_OIL_FlwRate_HYBRID_THERMAL_COMMAND_FD16
        SendCANR_EOPB_OIL_TEMP_FD16: can-be-invoked-concurrently=true, symbol=ApplCanComAb_FD16_SendCANR_EOPB_OIL_TEMP_FD16  # Transmit
          data-receive-point-by-arguments:
            access DRP_SendCANR_EOPB_OIL_TEMP_FD16_SendCANR_EOPB_OIL_TEMP_FD16: accessed-variable=SendCANR_EOPB_OIL_TEMP_FD16.SendCANR_EOPB_OIL_TEMP_FD16
            access DRP_SendCANR_EOPB_OIL_TEMP_FD16Vld_SendCANR_EOPB_OIL_TEMP_FD16Vld: accessed-variable=SendCANR_EOPB_OIL_TEMP_FD16Vld.SendCANR_EOPB_OIL_TEMP_FD16Vld
          data-send-points:
            access DSP_CanCom_FD16TxSignalsSR_COMTX_EOPB_OIL_TEMP_HYBRID_THERMAL_COMMAND_FD16: accessed-variable=CanCom_FD16TxSignalsSR.COMTX_EOPB_OIL_TEMP_HYBRID_THERMAL_COMMAND_FD16
        SendCANR_MC_HYBD_THRM_CMND_FD16: can-be-invoked-concurrently=true, symbol=ApplCanComAb_FD16_SendCANR_MC_HYBD_THRM_CMND_FD16  # Transmit
          data-receive-point-by-arguments:
            access DRP_SendCANR_MC_HYBD_THRM_CMND_FD16_SendCANR_MC_HYBD_THRM_CMND_FD16: accessed-variable=SendCANR_MC_HYBD_THRM_CMND_FD16.SendCANR_MC_HYBD_THRM_CMND_FD16
            access DRP_SendCANR_MC_HYBD_THRM_CMND_FD16Vld_SendCANR_MC_HYBD_THRM_CMND_FD16Vld: accessed-variable=SendCANR_MC_HYBD_THRM_CMND_FD16Vld.SendCANR_MC_HYBD_THRM_CMND_FD16Vld
          data-send-points:
            access DSP_CanCom_FD16TxSignalsSR_COMTX_MessageCounter_HYBRID_THERMAL_COMMAND_HYBRID_THERMAL_COMMAND_FD16: accessed-variable=CanCom_FD16TxSignalsSR.COMTX_MessageCounter_HYBRID_THERMAL_COMMAND_HYBRID_THERMAL_COMMAND_FD16
        SendCANR_SGCP_OIL_FlwRate_FD16: can-be-invoked-concurrently=true, symbol=ApplCanComAb_FD16_SendCANR_SGCP_OIL_FlwRate_FD16  # Transmit
          data-receive-point-by-arguments:
            access DRP_SendCANR_SGCP_OIL_FlwRate_FD16_SendCANR_SGCP_OIL_FlwRate_FD16: accessed-variable=SendCANR_SGCP_OIL_FlwRate_FD16.SendCANR_SGCP_OIL_FlwRate_FD16
            access DRP_SendCANR_SGCP_OIL_FlwRate_FD16Vld_SendCANR_SGCP_OIL_FlwRate_FD16Vld: accessed-variable=SendCANR_SGCP_OIL_FlwRate_FD16Vld.SendCANR_SGCP_OIL_FlwRate_FD16Vld
          data-send-points:
            access DSP_CanCom_FD16TxSignalsSR_COMTX_SGCP_OIL_FlwRate_HYBRID_THERMAL_COMMAND_FD16: accessed-variable=CanCom_FD16TxSignalsSR.COMTX_SGCP_OIL_FlwRate_HYBRID_THERMAL_COMMAND_FD16
        SendCANR_SGCP_OIL_TEMP_FD16: can-be-invoked-concurrently=true, symbol=ApplCanComAb_FD16_SendCANR_SGCP_OIL_TEMP_FD16  # Transmit
          data-receive-point-by-arguments:
            access DRP_SendCANR_SGCP_OIL_TEMP_FD16_SendCANR_SGCP_OIL_TEMP_FD16: accessed-variable=SendCANR_SGCP_OIL_TEMP_FD16.SendCANR_SGCP_OIL_TEMP_FD16
            access DRP_SendCANR_SGCP_OIL_TEMP_FD16Vld_SendCANR_SGCP_OIL_TEMP_FD16Vld: accessed-variable=SendCANR_SGCP_OIL_TEMP_FD16Vld.SendCANR_SGCP_OIL_TEMP_FD16Vld
          data-send-points:
            access DSP_CanCom_FD16TxSignalsSR_COMTX_SGCP_OIL_TEMP_HYBRID_THERMAL_COMMAND_FD16: accessed-variable=CanCom_FD16TxSignalsSR.COMTX_SGCP_OIL_TEMP_HYBRID_THERMAL_COMMAND_FD16
        SendCANR_IMPACTCommand_FD16: can-be-invoked-concurrently=true, symbol=ApplCanComAb_FD16_SendCANR_IMPACTCommand_FD16  # Transmit
          data-receive-point-by-arguments:
            access DRP_SendCANR_IMPACTCommand_FD16_SendCANR_IMPACTCommand_FD16: accessed-variable=SendCANR_IMPACTCommand_FD16.SendCANR_IMPACTCommand_FD16
            access DRP_SendCANR_IMPACTCommand_FD16Vld_SendCANR_IMPACTCommand_FD16Vld: accessed-variable=SendCANR_IMPACTCommand_FD16Vld.SendCANR_IMPACTCommand_FD16Vld
          data-send-points:
            access DSP_CanCom_FD16TxSignalsSR_COMTX_IMPACTCommand_IMPACT_INFO_FD16: accessed-variable=CanCom_FD16TxSignalsSR.COMTX_IMPACTCommand_IMPACT_INFO_FD16
        SendCANR_IMPACTConfirm_FD16: can-be-invoked-concurrently=true, symbol=ApplCanComAb_FD16_SendCANR_IMPACTConfirm_FD16  # Transmit
          data-receive-point-by-arguments:
            access DRP_SendCANR_IMPACTConfirm_FD16_SendCANR_IMPACTConfirm_FD16: accessed-variable=SendCANR_IMPACTConfirm_FD16.SendCANR_IMPACTConfirm_FD16
            access DRP_SendCANR_IMPACTConfirm_FD16Vld_SendCANR_IMPACTConfirm_FD16Vld: accessed-variable=SendCANR_IMPACTConfirm_FD16Vld.SendCANR_IMPACTConfirm_FD16Vld
          data-send-points:
            access DSP_CanCom_FD16TxSignalsSR_COMTX_IMPACTConfirm_IMPACT_INFO_FD16: accessed-variable=CanCom_FD16TxSignalsSR.COMTX_IMPACTConfirm_IMPACT_INFO_FD16
        SendCANR_TotalOdometer_FD16: can-be-invoked-concurrently=true, symbol=ApplCanComAb_FD16_SendCANR_TotalOdometer_FD16  # Transmit
          data-receive-point-by-arguments:
            access DRP_SendCANR_TotalOdometer_FD16_SendCANR_TotalOdometer_FD16: accessed-variable=SendCANR_TotalOdometer_FD16.SendCANR_TotalOdometer_FD16
            access DRP_SendCANR_TotalOdometer_FD16Vld_SendCANR_TotalOdometer_FD16Vld: accessed-variable=SendCANR_TotalOdometer_FD16Vld.SendCANR_TotalOdometer_FD16Vld
          data-send-points:
            access DSP_CanCom_FD16TxSignalsSR_COMTX_TotalOdometer_IPC_FD_1_FD16: accessed-variable=CanCom_FD16TxSignalsSR.COMTX_TotalOdometer_IPC_FD_1_FD16
        SendCANR_Real_Time_Clock_FD16: can-be-invoked-concurrently=true, symbol=ApplCanComAb_FD16_SendCANR_Real_Time_Clock_FD16  # Transmit
          data-receive-point-by-arguments:
            access DRP_SendCANR_Real_Time_Clock_FD16_SendCANR_Real_Time_Clock_FD16: accessed-variable=SendCANR_Real_Time_Clock_FD16.SendCANR_Real_Time_Clock_FD16
            access DRP_SendCANR_Real_Time_Clock_FD16Vld_SendCANR_Real_Time_Clock_FD16Vld: accessed-variable=SendCANR_Real_Time_Clock_FD16Vld.SendCANR_Real_Time_Clock_FD16Vld
          data-send-points:
            access DSP_CanCom_FD16TxSignalsSR_COMTX_Real_Time_Clock_REAL_TIME_CLOCK_FD16: accessed-variable=CanCom_FD16TxSignalsSR.COMTX_Real_Time_Clock_REAL_TIME_CLOCK_FD16
        SendCANR_Real_Time_Valdity_FD16: can-be-invoked-concurrently=true, symbol=ApplCanComAb_FD16_SendCANR_Real_Time_Valdity_FD16  # Transmit
          data-receive-point-by-arguments:
            access DRP_SendCANR_Real_Time_Valdity_FD16_SendCANR_Real_Time_Valdity_FD16: accessed-variable=SendCANR_Real_Time_Valdity_FD16.SendCANR_Real_Time_Valdity_FD16
            access DRP_SendCANR_Real_Time_Valdity_FD16Vld_SendCANR_Real_Time_Valdity_FD16Vld: accessed-variable=SendCANR_Real_Time_Valdity_FD16Vld.SendCANR_Real_Time_Valdity_FD16Vld
          data-send-points:
            access DSP_CanCom_FD16TxSignalsSR_COMTX_Real_Time_Validity_REAL_TIME_CLOCK_FD16: accessed-variable=CanCom_FD16TxSignalsSR.COMTX_Real_Time_Validity_REAL_TIME_CLOCK_FD16
        SendCANR_GPS_Date_Day_FD16: can-be-invoked-concurrently=true, symbol=ApplCanComAb_FD16_SendCANR_GPS_Date_Day_FD16  # Transmit
          data-receive-point-by-arguments:
            access DRP_SendCANR_GPS_Date_Day_FD16_SendCANR_GPS_Date_Day_FD16: accessed-variable=SendCANR_GPS_Date_Day_FD16.SendCANR_GPS_Date_Day_FD16
            access DRP_SendCANR_GPS_Date_Day_FD16Vld_SendCANR_GPS_Date_Day_FD16Vld: accessed-variable=SendCANR_GPS_Date_Day_FD16Vld.SendCANR_GPS_Date_Day_FD16Vld
          data-send-points:
            access DSP_CanCom_FD16TxSignalsSR_COMTX_GPS_Date_Day_TELEMATIC_FD_1_FD16: accessed-variable=CanCom_FD16TxSignalsSR.COMTX_GPS_Date_Day_TELEMATIC_FD_1_FD16
        SendCANR_GPS_Date_Month_FD16: can-be-invoked-concurrently=true, symbol=ApplCanComAb_FD16_SendCANR_GPS_Date_Month_FD16  # Transmit
          data-receive-point-by-arguments:
            access DRP_SendCANR_GPS_Date_Month_FD16_SendCANR_GPS_Date_Month_FD16: accessed-variable=SendCANR_GPS_Date_Month_FD16.SendCANR_GPS_Date_Month_FD16
            access DRP_SendCANR_GPS_Date_Month_FD16Vld_SendCANR_GPS_Date_Month_FD16Vld: accessed-variable=SendCANR_GPS_Date_Month_FD16Vld.SendCANR_GPS_Date_Month_FD16Vld
          data-send-points:
            access DSP_CanCom_FD16TxSignalsSR_COMTX_GPS_Date_Month_TELEMATIC_FD_1_FD16: accessed-variable=CanCom_FD16TxSignalsSR.COMTX_GPS_Date_Month_TELEMATIC_FD_1_FD16
        SendCANR_GPS_Date_Year_FD16: can-be-invoked-concurrently=true, symbol=ApplCanComAb_FD16_SendCANR_GPS_Date_Year_FD16  # Transmit
          data-receive-point-by-arguments:
            access DRP_SendCANR_GPS_Date_Year_FD16_SendCANR_GPS_Date_Year_FD16: accessed-variable=SendCANR_GPS_Date_Year_FD16.SendCANR_GPS_Date_Year_FD16
            access DRP_SendCANR_GPS_Date_Year_FD16Vld_SendCANR_GPS_Date_Year_FD16Vld: accessed-variable=SendCANR_GPS_Date_Year_FD16Vld.SendCANR_GPS_Date_Year_FD16Vld
          data-send-points:
            access DSP_CanCom_FD16TxSignalsSR_COMTX_GPS_Date_Year_TELEMATIC_FD_1_FD16: accessed-variable=CanCom_FD16TxSignalsSR.COMTX_GPS_Date_Year_TELEMATIC_FD_1_FD16
        SendCANR_GPS_UTC_Hour_FD16: can-be-invoked-concurrently=true, symbol=ApplCanComAb_FD16_SendCANR_GPS_UTC_Hour_FD16  # Transmit
          data-receive-point-by-arguments:
            access DRP_SendCANR_GPS_UTC_Hour_FD16_SendCANR_GPS_UTC_Hour_FD16: accessed-variable=SendCANR_GPS_UTC_Hour_FD16.SendCANR_GPS_UTC_Hour_FD16
            access DRP_SendCANR_GPS_UTC_Hour_FD16Vld_SendCANR_GPS_UTC_Hour_FD16Vld: accessed-variable=SendCANR_GPS_UTC_Hour_FD16Vld.SendCANR_GPS_UTC_Hour_FD16Vld
          data-send-points:
            access DSP_CanCom_FD16TxSignalsSR_COMTX_GPS_UTC_Hour_TELEMATIC_FD_1_FD16: accessed-variable=CanCom_FD16TxSignalsSR.COMTX_GPS_UTC_Hour_TELEMATIC_FD_1_FD16
        SendCANR_GPS_UTC_Minute_FD16: can-be-invoked-concurrently=true, symbol=ApplCanComAb_FD16_SendCANR_GPS_UTC_Minute_FD16  # Transmit
          data-receive-point-by-arguments:
            access DRP_SendCANR_GPS_UTC_Minute_FD16_SendCANR_GPS_UTC_Minute_FD16: accessed-variable=SendCANR_GPS_UTC_Minute_FD16.SendCANR_GPS_UTC_Minute_FD16
            access DRP_SendCANR_GPS_UTC_Minute_FD16Vld_SendCANR_GPS_UTC_Minute_FD16Vld: accessed-variable=SendCANR_GPS_UTC_Minute_FD16Vld.SendCANR_GPS_UTC_Minute_FD16Vld
          data-send-points:
            access DSP_CanCom_FD16TxSignalsSR_COMTX_GPS_UTC_Minute_TELEMATIC_FD_1_FD16: accessed-variable=CanCom_FD16TxSignalsSR.COMTX_GPS_UTC_Minute_TELEMATIC_FD_1_FD16
        SendCANR_GPS_UTC_Second_FD16: can-be-invoked-concurrently=true, symbol=ApplCanComAb_FD16_SendCANR_GPS_UTC_Second_FD16  # Transmit
          data-receive-point-by-arguments:
            access DRP_SendCANR_GPS_UTC_Second_FD16_SendCANR_GPS_UTC_Second_FD16: accessed-variable=SendCANR_GPS_UTC_Second_FD16.SendCANR_GPS_UTC_Second_FD16
            access DRP_SendCANR_GPS_UTC_Second_FD16Vld_SendCANR_GPS_UTC_Second_FD16Vld: accessed-variable=SendCANR_GPS_UTC_Second_FD16Vld.SendCANR_GPS_UTC_Second_FD16Vld
          data-send-points:
            access DSP_CanCom_FD16TxSignalsSR_COMTX_GPS_UTC_Second_TELEMATIC_FD_1_FD16: accessed-variable=CanCom_FD16TxSignalsSR.COMTX_GPS_UTC_Second_TELEMATIC_FD_1_FD16
        SendCANR_T4_Sensor_Temp_FD16: can-be-invoked-concurrently=true, symbol=ApplCanComAb_FD16_SendCANR_T4_Sensor_Temp_FD16  # Transmit
          data-receive-point-by-arguments:
            access DRP_SendCANR_T4_Sensor_Temp_FD16_SendCANR_T4_Sensor_Temp_FD16: accessed-variable=SendCANR_T4_Sensor_Temp_FD16.SendCANR_T4_Sensor_Temp_FD16
            access DRP_SendCANR_T4_Sensor_Temp_FD16Vld_SendCANR_T4_Sensor_Temp_FD16Vld: accessed-variable=SendCANR_T4_Sensor_Temp_FD16Vld.SendCANR_T4_Sensor_Temp_FD16Vld
          data-send-points:
            access DSP_CanCom_FD16TxSignalsSR_COMTX_T4_Sensor_Temp_VDCM_PWT3_FD16: accessed-variable=CanCom_FD16TxSignalsSR.COMTX_T4_Sensor_Temp_VDCM_PWT3_FD16
        SendCANR_T7_CoolntTmpVldty_FD16: can-be-invoked-concurrently=true, symbol=ApplCanComAb_FD16_SendCANR_T7_CoolntTmpVldty_FD16  # Transmit
          data-receive-point-by-arguments:
            access DRP_SendCANR_T7_CoolntTmpVldty_FD16_SendCANR_T7_CoolntTmpVldty_FD16: accessed-variable=SendCANR_T7_CoolntTmpVldty_FD16.SendCANR_T7_CoolntTmpVldty_FD16
            access DRP_SendCANR_T7_CoolntTmpVldty_FD16Vld_SendCANR_T7_CoolntTmpVldty_FD16Vld: accessed-variable=SendCANR_T7_CoolntTmpVldty_FD16Vld.SendCANR_T7_CoolntTmpVldty_FD16Vld
          data-send-points:
            access DSP_CanCom_FD16TxSignalsSR_COMTX_T7_CoolantTempVldty_VDCM_PWT3_FD16: accessed-variable=CanCom_FD16TxSignalsSR.COMTX_T7_CoolantTempVldty_VDCM_PWT3_FD16
        SendCANR_T7_Sensor_Temp_FD16: can-be-invoked-concurrently=true, symbol=ApplCanComAb_FD16_SendCANR_T7_Sensor_Temp_FD16  # Transmit
          data-receive-point-by-arguments:
            access DRP_SendCANR_T7_Sensor_Temp_FD16_SendCANR_T7_Sensor_Temp_FD16: accessed-variable=SendCANR_T7_Sensor_Temp_FD16.SendCANR_T7_Sensor_Temp_FD16
            access DRP_SendCANR_T7_Sensor_Temp_FD16Vld_SendCANR_T7_Sensor_Temp_FD16Vld: accessed-variable=SendCANR_T7_Sensor_Temp_FD16Vld.SendCANR_T7_Sensor_Temp_FD16Vld
          data-send-points:
            access DSP_CanCom_FD16TxSignalsSR_COMTX_T7_Sensor_Temp_VDCM_PWT3_FD16: accessed-variable=CanCom_FD16TxSignalsSR.COMTX_T7_Sensor_Temp_VDCM_PWT3_FD16
        SendCANR_RELSD_TgtTrq_FD16: can-be-invoked-concurrently=true, symbol=ApplCanComAb_FD16_SendCANR_RELSD_TgtTrq_FD16  # Transmit
          data-receive-point-by-arguments:
            access DRP_SendCANR_RELSD_TgtTrq_FD16_SendCANR_RELSD_TgtTrq_FD16: accessed-variable=SendCANR_RELSD_TgtTrq_FD16.SendCANR_RELSD_TgtTrq_FD16
            access DRP_SendCANR_RELSD_TgtTrq_FD16Vld_SendCANR_RELSD_TgtTrq_FD16Vld: accessed-variable=SendCANR_RELSD_TgtTrq_FD16Vld.SendCANR_RELSD_TgtTrq_FD16Vld
          data-send-points:
            access DSP_CanCom_FD16TxSignalsSR_COMTX_RELSD_TgtTrq_VEHDYN_FD_1_FD16: accessed-variable=CanCom_FD16TxSignalsSR.COMTX_RELSD_TgtTrq_VEHDYN_FD_1_FD16
        SendCANR_VIN_DATA_FD16: can-be-invoked-concurrently=true, symbol=ApplCanComAb_FD16_SendCANR_VIN_DATA_FD16  # Transmit
          data-receive-point-by-arguments:
            access DRP_SendCANR_VIN_DATA_FD16_SendCANR_VIN_DATA_FD16: accessed-variable=SendCANR_VIN_DATA_FD16.SendCANR_VIN_DATA_FD16
            access DRP_SendCANR_VIN_DATA_FD16Vld_SendCANR_VIN_DATA_FD16Vld: accessed-variable=SendCANR_VIN_DATA_FD16Vld.SendCANR_VIN_DATA_FD16Vld
          data-send-points:
            access DSP_CanCom_FD16TxSignalsSR_COMTX_VIN_DATA_VIN_FD16: accessed-variable=CanCom_FD16TxSignalsSR.COMTX_VIN_DATA_VIN_FD16
        SendCANR_VIN_MSG_FD16: can-be-invoked-concurrently=true, symbol=ApplCanComAb_FD16_SendCANR_VIN_MSG_FD16  # Transmit
          data-receive-point-by-arguments:
            access DRP_SendCANR_VIN_MSG_FD16_SendCANR_VIN_MSG_FD16: accessed-variable=SendCANR_VIN_MSG_FD16.SendCANR_VIN_MSG_FD16
            access DRP_SendCANR_VIN_MSG_FD16Vld_SendCANR_VIN_MSG_FD16Vld: accessed-variable=SendCANR_VIN_MSG_FD16Vld.SendCANR_VIN_MSG_FD16Vld
          data-send-points:
            access DSP_CanCom_FD16TxSignalsSR_COMTX_VIN_MSG_VIN_FD16: accessed-variable=CanCom_FD16TxSignalsSR.COMTX_VIN_MSG_VIN_FD16
      shared-parameters:
        27 x parameter data prototype, all with type=ADTSBoolean, init-value=1:
          KeCANR_b_ComTxMsg_BCM_FD_10_FD16_Enbld
          KeCANR_b_ComTxMsg_BCM_FD_2_FD16_Enbld
          KeCANR_b_ComTxMsg_BCM_FD_9_FD16_Enbld
          KeCANR_b_ComTxMsg_BRAKE_FD_2_FD16_Enbld
          KeCANR_b_ComTxMsg_BRAKE_FD_4_FD16_Enbld
          KeCANR_b_ComTxMsg_BRAKE_FD_5_FD16_Enbld
          KeCANR_b_ComTxMsg_GLIWA_MCPA_RX_FD16_Enbld
          KeCANR_b_ComTxMsg_GLIWA_MCPB_RX_FD16_Enbld
          KeCANR_b_ComTxMsg_GLIWA_SGCP_RX_FD16_Enbld
          KeCANR_b_ComTxMsg_HYBRID_POWERTRAIN1_FD16_Enbld
          KeCANR_b_ComTxMsg_HYBRID_POWERTRAIN2_FD16_Enbld
          KeCANR_b_ComTxMsg_HYBRID_POWERTRAIN5_FD16_Enbld
          KeCANR_b_ComTxMsg_HYBRID_SYSTEM_EPT1_FD16_Enbld
          KeCANR_b_ComTxMsg_HYBRID_THERMAL_COMMAND_FD16_Enbld
          KeCANR_b_ComTxMsg_IMPACT_INFO_FD16_Enbld
          KeCANR_b_ComTxMsg_INVTARGET_PROPULSION1_FD16_Enbld
          KeCANR_b_ComTxMsg_INVTARGET_PROPULSION2_FD16_Enbld
          KeCANR_b_ComTxMsg_IPC_FD_1_FD16_Enbld
          KeCANR_b_ComTxMsg_PT_ENERGY_FD_1_FD16_Enbld
          KeCANR_b_ComTxMsg_PT_SYSTEM_FD_1_FD16_Enbld
          KeCANR_b_ComTxMsg_PT_TORQUE_FD_1_FD16_Enbld
          KeCANR_b_ComTxMsg_REAL_TIME_CLOCK_FD16_Enbld
          KeCANR_b_ComTxMsg_TELEMATIC_FD_1_FD16_Enbld
          KeCANR_b_ComTxMsg_VDCM_PWT3_FD16_Enbld
          KeCANR_b_ComTxMsg_VEHDYN_FD_1_FD16_Enbld
          KeCANR_b_ComTxMsg_VIN_FD16_Enbld
          KeCANR_b_ComTxMsg_CFG_DATA_CODE_REQUEST_FD16_Enbld
